VERSION ""

NS_ :

BS_:

BU_: PowertrainControlModule AtmosphericSensor SafetyRestraintSystem2 Aftertreatment_2_GasOutlet Aftertreatment_2_GasIntake DieselParticulateFilterControl Turbocharger SafetyRestraintSystem1 CabDisplay2 Aftertreatment_1_GasOutlet Aftertreatment_1_GasIntake OnBoardDataLogger OffBoardDiagnosticTool2 OffBoardDiagnosticTool1 FileServer ParkingBrakeController SeatController2 FanDriveController SteeringColumnUnit CommunicationUnitRadio CommunicationUnitSatellite CommunicationUnitCellular PropulsionBatteryCharger ChassisController2 ChassisController1 EngineValveControl AuxiliaryHeater2 AuxiliaryHeater1 ClutchUnit RampControl InformationSystem1 SuspensionSystemController2 OilSensor VehicleDynamicStability ExhaustEmissionController TransmissionDisplay2 TransmissionDisplay1 ClimateControl2 WaterPumpController RearAxleSteeringController LightingOperatorControl SeatController1 IgnitionController2 IgnitionController1 TirePressureController CabController2 CabController1 PneumaticSystemController SuspensionSystemController1 HydraulicPumpController EnduranceBrakingSystem RetarderExhaustEngine2 OnBoardDiagnosticUnit HeadwayController RetarderExhaustEngine1 CabDisplay1 ManagementComputer VirtualTerminal OffVehicleGateway PowerTakeOffFront HitchControl AuxiliaryValveControl BodyController TractorTrailerBridge1 StarterSystem ElectricalSystem VehicleSecurity VehicleNavigation AerodynamicControl ElectricalChargingSystem ClimateControl1 TripRecorder InstrumentCluster SuspensionDriveAxle2 SuspensionDriveAxle1 SuspensionSteerAxle SteeringController FuelSystem CruiseControl RetarderDriveline RetarderEngine BrakesDriveAxle2 BrakesDriveAxle1 BrakesSystemController BrakesSteerAxle AxleDrive2 AxleDrive1 AxleSteering PowerTakeOff ShiftConsoleSecondary ShiftConsolePrimary Transmission2 Transmission1 Engine2 Engine1

BO_ 2558394110 EAMC: 8 Vector__XXX
 SG_ Instance15 : 46|1@1+ (1,0) [0|1] "" Vector__XXX
 SG_ Instance14 : 45|1@1+ (1,0) [0|1] "" Vector__XXX
 SG_ Instance13 : 44|1@1+ (1,0) [0|1] "" Vector__XXX
 SG_ Instance12 : 43|1@1+ (1,0) [0|1] "" Vector__XXX
 SG_ Instance11 : 42|1@1+ (1,0) [0|1] "" Vector__XXX
 SG_ Instance10 : 41|1@1+ (1,0) [0|1] "" Vector__XXX
 SG_ Instance9 : 40|1@1+ (1,0) [0|1] "" Vector__XXX
 SG_ Instance8 : 39|1@1+ (1,0) [0|1] "" Vector__XXX
 SG_ Instance7 : 38|1@1+ (1,0) [0|1] "" Vector__XXX
 SG_ Instance6 : 37|1@1+ (1,0) [0|1] "" Vector__XXX
 SG_ Instance5 : 36|1@1+ (1,0) [0|1] "" Vector__XXX
 SG_ Instance4 : 35|1@1+ (1,0) [0|1] "" Vector__XXX
 SG_ Instance3 : 34|1@1+ (1,0) [0|1] "" Vector__XXX
 SG_ Instance2 : 33|1@1+ (1,0) [0|1] "" Vector__XXX
 SG_ Instance1 : 32|1@1+ (1,0) [0|1] "" Vector__XXX
 SG_ PercentSpdCmd : 24|8@1+ (0.5,0) [0|100] "%" Vector__XXX
 SG_ SpdCmd : 8|16@1+ (0.5,0) [0|32127.5] "rpm" Vector__XXX
 SG_ PwrHold : 2|2@1+ (1,0) [0|3] "" Vector__XXX
 SG_ EnableCmd : 0|2@1+ (1,0) [0|3] "" Vector__XXX

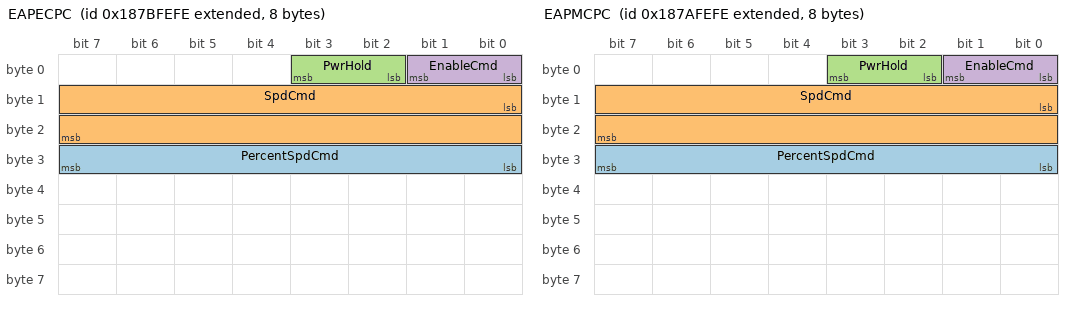
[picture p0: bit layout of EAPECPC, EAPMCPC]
BO_ 2558263038 EAPECPC: 8 Vector__XXX
 SG_ PercentSpdCmd : 24|8@1+ (0.5,0) [0|100] "%" Vector__XXX
 SG_ SpdCmd : 8|16@1+ (0.5,0) [0|32127.5] "rpm" Vector__XXX
 SG_ PwrHold : 2|2@1+ (1,0) [0|3] "" Vector__XXX
 SG_ EnableCmd : 0|2@1+ (1,0) [0|3] "" Vector__XXX

BO_ 2558197502 EAPMCPC: 8 Vector__XXX
 SG_ PercentSpdCmd : 24|8@1+ (0.5,0) [0|100] "%" Vector__XXX
 SG_ SpdCmd : 8|16@1+ (0.5,0) [0|32127.5] "rpm" Vector__XXX
 SG_ PwrHold : 2|2@1+ (1,0) [0|3] "" Vector__XXX
 SG_ EnableCmd : 0|2@1+ (1,0) [0|3] "" Vector__XXX

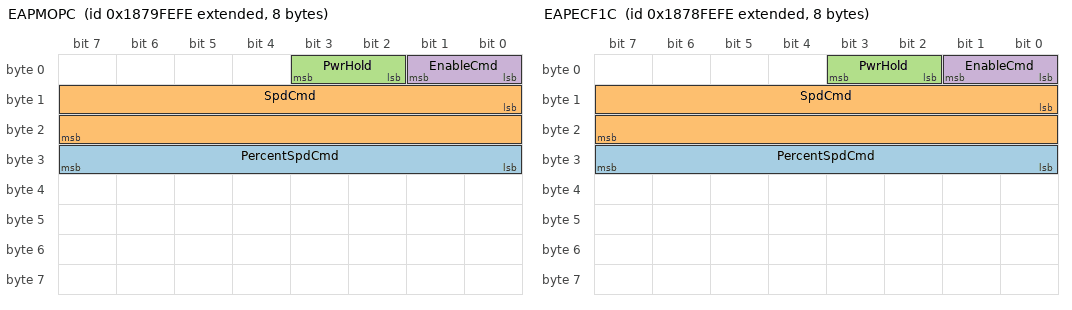
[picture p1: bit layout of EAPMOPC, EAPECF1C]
BO_ 2558131966 EAPMOPC: 8 Vector__XXX
 SG_ PercentSpdCmd : 24|8@1+ (0.5,0) [0|100] "%" Vector__XXX
 SG_ SpdCmd : 8|16@1+ (0.5,0) [0|32127.5] "rpm" Vector__XXX
 SG_ PwrHold : 2|2@1+ (1,0) [0|3] "" Vector__XXX
 SG_ EnableCmd : 0|2@1+ (1,0) [0|3] "" Vector__XXX

BO_ 2558066430 EAPECF1C: 8 Vector__XXX
 SG_ PercentSpdCmd : 24|8@1+ (0.5,0) [0|100] "%" Vector__XXX
 SG_ SpdCmd : 8|16@1+ (0.5,0) [0|32127.5] "rpm" Vector__XXX
 SG_ PwrHold : 2|2@1+ (1,0) [0|3] "" Vector__XXX
 SG_ EnableCmd : 0|2@1+ (1,0) [0|3] "" Vector__XXX

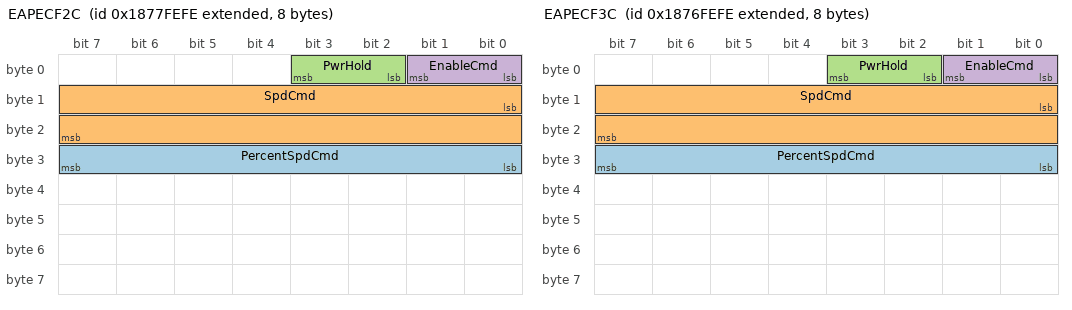
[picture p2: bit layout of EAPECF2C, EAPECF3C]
BO_ 2558000894 EAPECF2C: 8 Vector__XXX
 SG_ PercentSpdCmd : 24|8@1+ (0.5,0) [0|100] "%" Vector__XXX
 SG_ SpdCmd : 8|16@1+ (0.5,0) [0|32127.5] "rpm" Vector__XXX
 SG_ PwrHold : 2|2@1+ (1,0) [0|3] "" Vector__XXX
 SG_ EnableCmd : 0|2@1+ (1,0) [0|3] "" Vector__XXX

BO_ 2557935358 EAPECF3C: 8 Vector__XXX
 SG_ PercentSpdCmd : 24|8@1+ (0.5,0) [0|100] "%" Vector__XXX
 SG_ SpdCmd : 8|16@1+ (0.5,0) [0|32127.5] "rpm" Vector__XXX
 SG_ PwrHold : 2|2@1+ (1,0) [0|3] "" Vector__XXX
 SG_ EnableCmd : 0|2@1+ (1,0) [0|3] "" Vector__XXX

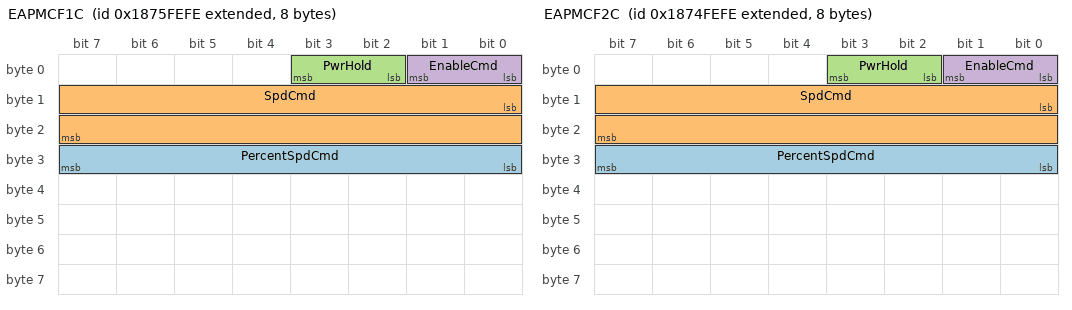
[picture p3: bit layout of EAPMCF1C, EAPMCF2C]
BO_ 2557869822 EAPMCF1C: 8 Vector__XXX
 SG_ PercentSpdCmd : 24|8@1+ (0.5,0) [0|100] "%" Vector__XXX
 SG_ SpdCmd : 8|16@1+ (0.5,0) [0|32127.5] "rpm" Vector__XXX
 SG_ PwrHold : 2|2@1+ (1,0) [0|3] "" Vector__XXX
 SG_ EnableCmd : 0|2@1+ (1,0) [0|3] "" Vector__XXX

BO_ 2557804286 EAPMCF2C: 8 Vector__XXX
 SG_ PercentSpdCmd : 24|8@1+ (0.5,0) [0|100] "%" Vector__XXX
 SG_ SpdCmd : 8|16@1+ (0.5,0) [0|32127.5] "rpm" Vector__XXX
 SG_ PwrHold : 2|2@1+ (1,0) [0|3] "" Vector__XXX
 SG_ EnableCmd : 0|2@1+ (1,0) [0|3] "" Vector__XXX

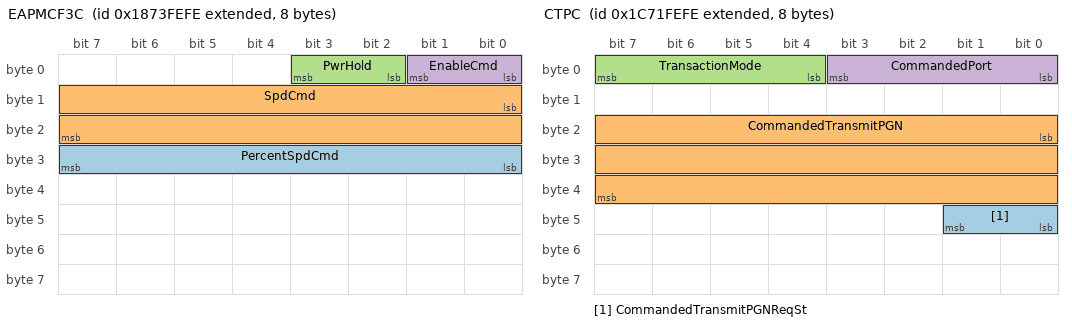
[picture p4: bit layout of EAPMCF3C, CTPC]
BO_ 2557738750 EAPMCF3C: 8 Vector__XXX
 SG_ PercentSpdCmd : 24|8@1+ (0.5,0) [0|100] "%" Vector__XXX
 SG_ SpdCmd : 8|16@1+ (0.5,0) [0|32127.5] "rpm" Vector__XXX
 SG_ PwrHold : 2|2@1+ (1,0) [0|3] "" Vector__XXX
 SG_ EnableCmd : 0|2@1+ (1,0) [0|3] "" Vector__XXX

BO_ 2557673214 ODMCC: 37 Vector__XXX
 SG_ NFBin6CountCmd : 272|24@1+ (1,0) [0|16449535] "" Vector__XXX
 SG_ NFBin5CountCmd : 248|24@1+ (1,0) [0|16449535] "" Vector__XXX
 SG_ NFBin4CountCmd : 224|24@1+ (1,0) [0|16449535] "" Vector__XXX
 SG_ NFBin3CountCmd : 200|24@1+ (1,0) [0|16449535] "" Vector__XXX
 SG_ NFBin2CountCmd : 176|24@1+ (1,0) [0|16449535] "" Vector__XXX
 SG_ NFBin1CountCmd : 152|24@1+ (1,0) [0|16449535] "" Vector__XXX
 SG_ FBin6CountCmd : 128|24@1+ (1,0) [0|16449535] "" Vector__XXX
 SG_ FBin5CountCmd : 104|24@1+ (1,0) [0|16449535] "" Vector__XXX
 SG_ FBin4CountCmd : 80|24@1+ (1,0) [0|16449535] "" Vector__XXX
 SG_ FBin3CountCmd : 56|24@1+ (1,0) [0|16449535] "" Vector__XXX
 SG_ FBin2CountCmd : 32|24@1+ (1,0) [0|16449535] "" Vector__XXX
 SG_ FBin1CountCmd : 8|24@1+ (1,0) [0|16449535] "" Vector__XXX
 SG_ IdNum : 0|8@1+ (1,0) [0|250] "" Vector__XXX

BO_ 2624716542 CTPC: 8 Vector__XXX
 SG_ CommandedTransmitPGNReqSt : 40|2@1+ (1,0) [0|3] "" Vector__XXX
 SG_ CommandedTransmitPGN : 16|24@1+ (1,0) [0|16777215] "" Vector__XXX
 SG_ TransactionMode : 4|4@1+ (1,0) [0|15] "" Vector__XXX
 SG_ CommandedPort : 0|4@1+ (1,0) [0|15] "" Vector__XXX

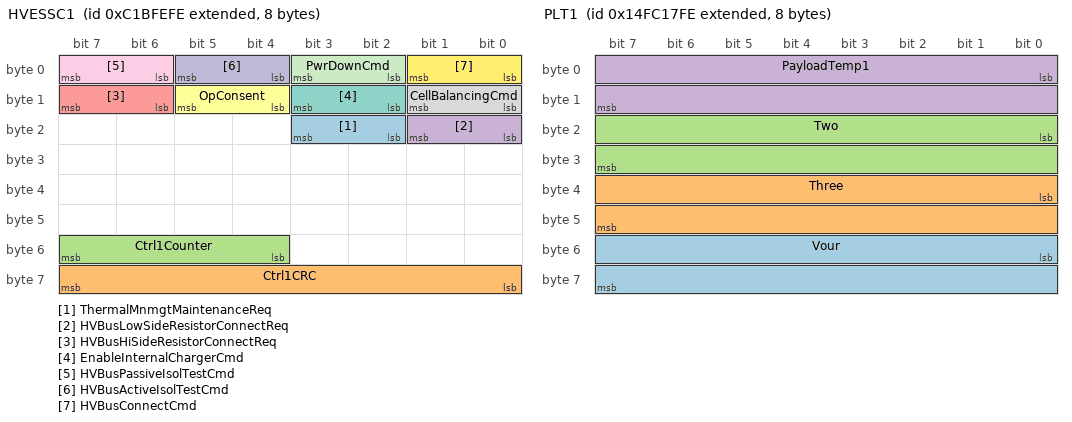
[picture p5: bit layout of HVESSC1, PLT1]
BO_ 2350644990 HVESSC1: 8 Vector__XXX
 SG_ ThermalMnmgtMaintenanceReq : 18|2@1+ (1,0) [0|3] "" Vector__XXX
 SG_ Ctrl1CRC : 56|8@1+ (1,0) [0|255] "" Vector__XXX
 SG_ Ctrl1Counter : 52|4@1+ (1,0) [0|15] "" Vector__XXX
 SG_ HVBusLowSideResistorConnectReq : 16|2@1+ (1,0) [0|3] "" Vector__XXX
 SG_ HVBusHiSideResistorConnectReq : 14|2@1+ (1,0) [0|3] "" Vector__XXX
 SG_ OpConsent : 12|2@1+ (1,0) [0|3] "" Vector__XXX
 SG_ EnableInternalChargerCmd : 10|2@1+ (1,0) [0|3] "" Vector__XXX
 SG_ CellBalancingCmd : 8|2@1+ (1,0) [0|3] "" Vector__XXX
 SG_ HVBusPassiveIsolTestCmd : 6|2@1+ (1,0) [0|3] "" Vector__XXX
 SG_ HVBusActiveIsolTestCmd : 4|2@1+ (1,0) [0|3] "" Vector__XXX
 SG_ PwrDownCmd : 2|2@1+ (1,0) [0|3] "" Vector__XXX
 SG_ HVBusConnectCmd : 0|2@1+ (1,0) [0|3] "" Vector__XXX

BO_ 2566658558 PLST1: 8 Vector__XXX
 SG_ TotalHaulCycleCount : 32|32@1+ (1,0) [0|4211081215] "" Vector__XXX
 SG_ TotalDeliveredPayloadWeight : 0|32@1+ (100,0) [0|421108121500] "kg" Vector__XXX

BO_ 2566658302 PLST2: 8 Vector__XXX
 SG_ TotalPayloadTransactionCount : 0|32@1+ (1,0) [0|4211081215] "" Vector__XXX

BO_ 2499549182 PLT1: 8 Vector__XXX
 SG_ Vour : 48|16@1+ (0.03125,-273) [-40|250] "°C" Vector__XXX
 SG_ Three : 32|16@1+ (0.03125,-273) [-40|250] "°C" Vector__XXX
 SG_ Two : 16|16@1+ (0.03125,-273) [-40|250] "°C" Vector__XXX
 SG_ PayloadTemp1 : 0|16@1+ (0.03125,-273) [-40|250] "°C" Vector__XXX

BO_ 2499548926 PLT2: 8 Vector__XXX
 SG_ Five : 0|16@1+ (0.03125,-273) [-40|250] "°C" Vector__XXX

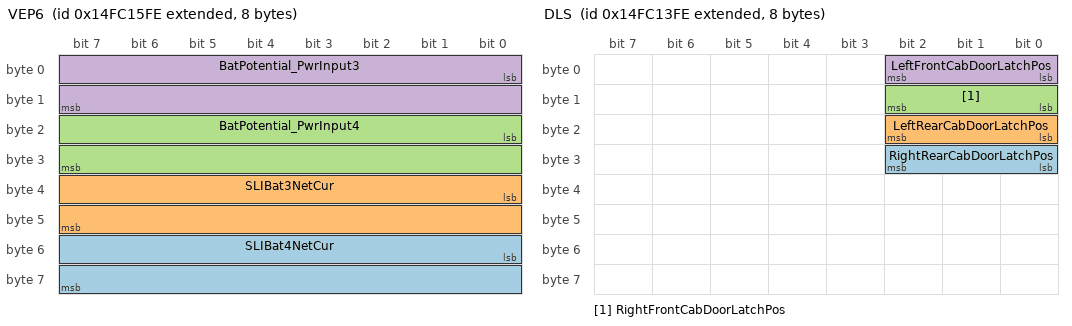
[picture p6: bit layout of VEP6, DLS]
BO_ 2499548670 VEP6: 8 Vector__XXX
 SG_ SLIBat4NetCur : 48|16@1+ (0.05,-1600) [-1600|1612.75] "A" Vector__XXX
 SG_ SLIBat3NetCur : 32|16@1+ (0.05,-1600) [-1600|1612.75] "A" Vector__XXX
 SG_ BatPotential_PwrInput4 : 16|16@1+ (0.05,0) [0|3212.75] "V" Vector__XXX
 SG_ BatPotential_PwrInput3 : 0|16@1+ (0.05,0) [0|3212.75] "V" Vector__XXX

BO_ 2499548158 DLS: 8 Vector__XXX
 SG_ RightRearCabDoorLatchPos : 24|3@1+ (1,0) [0|7] "" Vector__XXX
 SG_ LeftRearCabDoorLatchPos : 16|3@1+ (1,0) [0|7] "" Vector__XXX
 SG_ RightFrontCabDoorLatchPos : 8|3@1+ (1,0) [0|7] "" Vector__XXX
 SG_ LeftFrontCabDoorLatchPos : 0|3@1+ (1,0) [0|7] "" Vector__XXX

BO_ 2499547902 CDC1: 8 Vector__XXX
 SG_ MirrorAutoPanningEnable : 30|2@1+ (1,0) [0|3] "" Vector__XXX
 SG_ MirrorFoldingSw : 22|2@1+ (1,0) [0|3] "" Vector__XXX
 SG_ MirrorRight2HeatCmd : 54|2@1+ (1,0) [0|3] "" Vector__XXX
 SG_ MirrorLeft2HeatCmd : 52|2@1+ (1,0) [0|3] "" Vector__XXX
 SG_ MirrorRight1HeatCmd : 50|2@1+ (1,0) [0|3] "" Vector__XXX
 SG_ MirrorLeft1HeatCmd : 48|2@1+ (1,0) [0|3] "" Vector__XXX
 SG_ MirrorRight2VerticalCmd : 46|2@1+ (1,0) [0|3] "" Vector__XXX
 SG_ MirrorRight2HorizontalCmd : 44|2@1+ (1,0) [0|3] "" Vector__XXX
 SG_ MirrorLeft2VerticalCmd : 42|2@1+ (1,0) [0|3] "" Vector__XXX
 SG_ MirrorLeft2HorizontalCmd : 40|2@1+ (1,0) [0|3] "" Vector__XXX
 SG_ MirrorRight1VerticalCmd : 38|2@1+ (1,0) [0|3] "" Vector__XXX
 SG_ MirrorRight1HorizontalCmd : 36|2@1+ (1,0) [0|3] "" Vector__XXX
 SG_ MirrorLeft1VerticalCmd : 34|2@1+ (1,0) [0|3] "" Vector__XXX
 SG_ MirrorLeft1HorizontalCmd : 32|2@1+ (1,0) [0|3] "" Vector__XXX
 SG_ RightRearWindowPosCmd : 27|3@1+ (1,0) [0|7] "" Vector__XXX
 SG_ LeftRearWindowPosCmd : 24|3@1+ (1,0) [0|7] "" Vector__XXX
 SG_ RightFrontWindowPosCmd : 19|3@1+ (1,0) [0|7] "" Vector__XXX
 SG_ LeftFrontWindowPosCmd : 16|3@1+ (1,0) [0|7] "" Vector__XXX
 SG_ RemoteCabDoorLockReq : 8|3@1+ (1,0) [0|7] "" Vector__XXX
 SG_ DoorsLockActCmd : 0|3@1+ (1,0) [0|7] "" Vector__XXX

BO_ 2566656510 TGFI: 8 Vector__XXX
 SG_ EngTotalGasIdleFuelVolumeUsed : 32|32@1+ (0.5,0) [0|2105540607.5] "m³" Vector__XXX
 SG_ EngTotalGasFuelVolumeUsed : 0|32@1+ (0.5,0) [0|2105540607.5] "m³" Vector__XXX

BO_ 2565929214 ADASIS3: 8 Vector__XXX

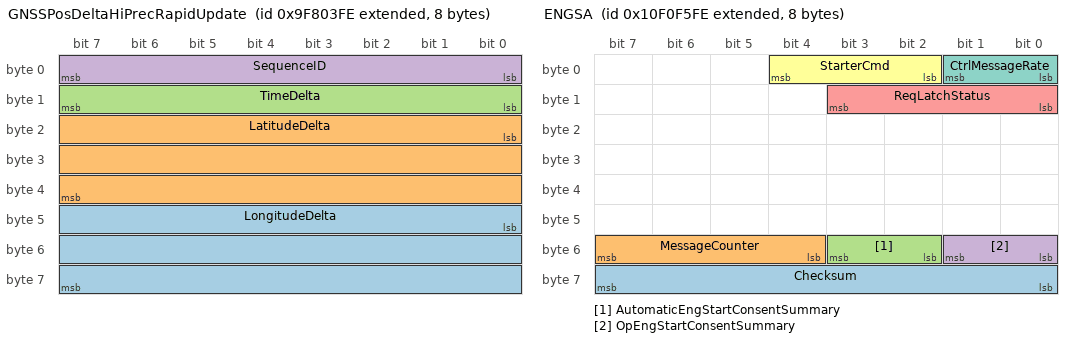
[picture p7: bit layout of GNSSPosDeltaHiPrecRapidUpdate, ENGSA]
BO_ 2314732542 GNSSPosDeltaHiPrecRapidUpdate: 8 Vector__XXX
 SG_ LongitudeDelta : 40|24@1- (10,0) [0|0] "µsec" Vector__XXX
 SG_ LatitudeDelta : 16|24@1- (10,0) [0|0] "µsec" Vector__XXX
 SG_ TimeDelta : 8|8@1+ (5,0) [0|0] "ms" Vector__XXX
 SG_ SequenceID : 0|8@1+ (1,0) [0|0] "" Vector__XXX

BO_ 2565928958 ADASIS2: 8 Vector__XXX

BO_ 2565928702 ADASIS1: 8 Vector__XXX

BO_ 2431710718 ENGSA: 8 Vector__XXX
 SG_ Checksum : 56|8@1+ (1,0) [0|255] "" Vector__XXX
 SG_ MessageCounter : 52|4@1+ (1,0) [0|15] "" Vector__XXX
 SG_ AutomaticEngStartConsentSummary : 50|2@1+ (1,0) [0|3] "" Vector__XXX
 SG_ OpEngStartConsentSummary : 48|2@1+ (1,0) [0|3] "" Vector__XXX
 SG_ ReqLatchStatus : 8|4@1+ (1,0) [0|15] "" Vector__XXX
 SG_ StarterCmd : 2|3@1+ (1,0) [0|7] "" Vector__XXX
 SG_ CtrlMessageRate : 0|2@1+ (1,0) [0|3] "" Vector__XXX

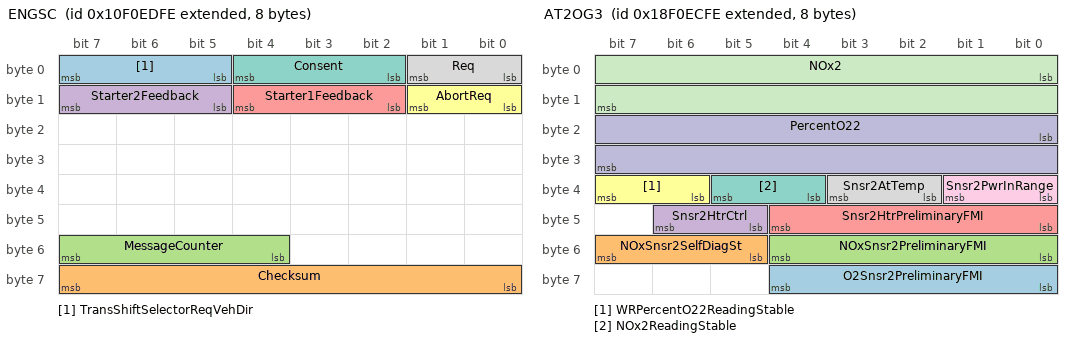
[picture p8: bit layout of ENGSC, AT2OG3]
BO_ 2431708670 ENGSC: 8 Vector__XXX
 SG_ TransShiftSelectorReqVehDir : 5|3@1+ (1,0) [0|7] "" Vector__XXX
 SG_ Checksum : 56|8@1+ (1,0) [0|255] "" Vector__XXX
 SG_ MessageCounter : 52|4@1+ (1,0) [0|15] "" Vector__XXX
 SG_ Starter2Feedback : 13|3@1+ (1,0) [0|7] "" Vector__XXX
 SG_ Starter1Feedback : 10|3@1+ (1,0) [0|7] "" Vector__XXX
 SG_ AbortReq : 8|2@1+ (1,0) [0|3] "" Vector__XXX
 SG_ Consent : 2|3@1+ (1,0) [0|7] "" Vector__XXX
 SG_ Req : 0|2@1+ (1,0) [0|3] "" Vector__XXX

BO_ 2566661118 LFC2: 8 Vector__XXX
 SG_ EngTotalDieselFuelDemand : 0|32@1+ (0.5,0) [0|2105540607.5] "l" Vector__XXX

BO_ 2633769726 EEC19: 8 Vector__XXX
 SG_ ExhFlowRate : 32|32@1+ (0.001,0) [0|4211081.215] "kg/h" Vector__XXX
 SG_ TotalEngEnergy : 0|32@1+ (1,0) [0|4211081215] "kWh" Vector__XXX

BO_ 2565926142 AT2OG3: 8 Vector__XXX
 SG_ O2Snsr2PreliminaryFMI : 56|5@1+ (1,0) [0|31] "" Vector__XXX
 SG_ NOxSnsr2SelfDiagSt : 53|3@1+ (1,0) [0|7] "" Vector__XXX
 SG_ NOxSnsr2PreliminaryFMI : 48|5@1+ (1,0) [0|31] "" Vector__XXX
 SG_ Snsr2HtrCtrl : 45|2@1+ (1,0) [0|3] "" Vector__XXX
 SG_ Snsr2HtrPreliminaryFMI : 40|5@1+ (1,0) [0|31] "" Vector__XXX
 SG_ WRPercentO22ReadingStable : 38|2@1+ (1,0) [0|3] "" Vector__XXX
 SG_ NOx2ReadingStable : 36|2@1+ (1,0) [0|3] "" Vector__XXX
 SG_ Snsr2AtTemp : 34|2@1+ (1,0) [0|3] "" Vector__XXX
 SG_ Snsr2PwrInRange : 32|2@1+ (1,0) [0|3] "" Vector__XXX
 SG_ PercentO22 : 16|16@1+ (0.000514,-12) [-12|21.02707] "%" Vector__XXX
 SG_ NOx2 : 0|16@1+ (0.05,-200) [-200|3012.75] "ppm" Vector__XXX

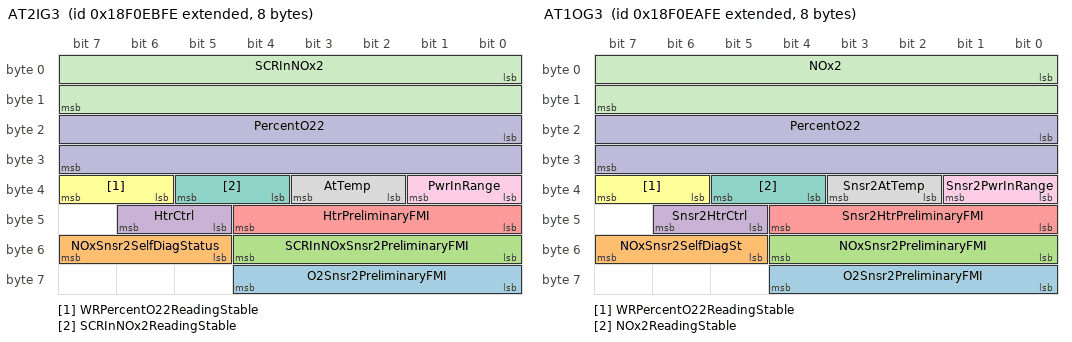
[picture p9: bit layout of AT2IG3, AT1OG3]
BO_ 2565925886 AT2IG3: 8 Vector__XXX
 SG_ O2Snsr2PreliminaryFMI : 56|5@1+ (1,0) [0|31] "" Vector__XXX
 SG_ NOxSnsr2SelfDiagStatus : 53|3@1+ (1,0) [0|7] "" Vector__XXX
 SG_ SCRInNOxSnsr2PreliminaryFMI : 48|5@1+ (1,0) [0|31] "" Vector__XXX
 SG_ HtrCtrl : 45|2@1+ (1,0) [0|3] "" Vector__XXX
 SG_ HtrPreliminaryFMI : 40|5@1+ (1,0) [0|31] "" Vector__XXX
 SG_ WRPercentO22ReadingStable : 38|2@1+ (1,0) [0|3] "" Vector__XXX
 SG_ SCRInNOx2ReadingStable : 36|2@1+ (1,0) [0|3] "" Vector__XXX
 SG_ AtTemp : 34|2@1+ (1,0) [0|3] "" Vector__XXX
 SG_ PwrInRange : 32|2@1+ (1,0) [0|3] "" Vector__XXX
 SG_ PercentO22 : 16|16@1+ (0.000514,-12) [-12|21.02707] "%" Vector__XXX
 SG_ SCRInNOx2 : 0|16@1+ (0.05,-200) [-200|3012.75] "ppm" Vector__XXX

BO_ 2565925630 AT1OG3: 8 Vector__XXX
 SG_ O2Snsr2PreliminaryFMI : 56|5@1+ (1,0) [0|31] "" Vector__XXX
 SG_ NOxSnsr2SelfDiagSt : 53|3@1+ (1,0) [0|7] "" Vector__XXX
 SG_ NOxSnsr2PreliminaryFMI : 48|5@1+ (1,0) [0|31] "" Vector__XXX
 SG_ Snsr2HtrCtrl : 45|2@1+ (1,0) [0|3] "" Vector__XXX
 SG_ Snsr2HtrPreliminaryFMI : 40|5@1+ (1,0) [0|31] "" Vector__XXX
 SG_ WRPercentO22ReadingStable : 38|2@1+ (1,0) [0|3] "" Vector__XXX
 SG_ NOx2ReadingStable : 36|2@1+ (1,0) [0|3] "" Vector__XXX
 SG_ Snsr2AtTemp : 34|2@1+ (1,0) [0|3] "" Vector__XXX
 SG_ Snsr2PwrInRange : 32|2@1+ (1,0) [0|3] "" Vector__XXX
 SG_ PercentO22 : 16|16@1+ (0.000514,-12) [-12|21.02707] "%" Vector__XXX
 SG_ NOx2 : 0|16@1+ (0.05,-200) [-200|3012.75] "ppm" Vector__XXX

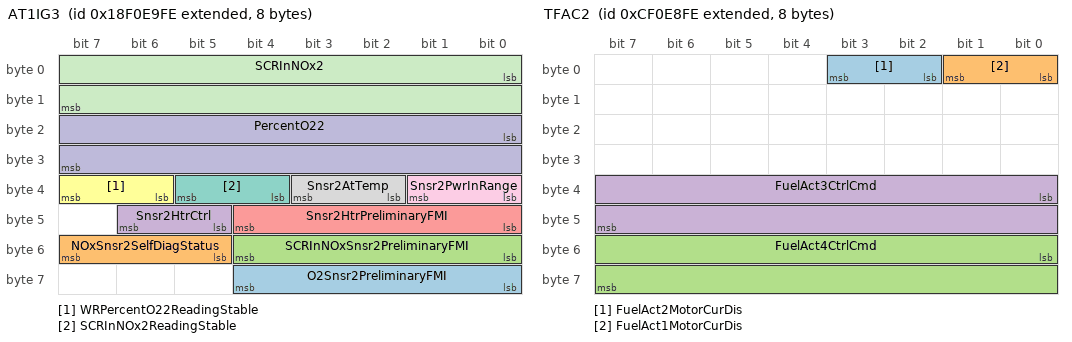
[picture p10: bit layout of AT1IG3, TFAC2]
BO_ 2565925374 AT1IG3: 8 Vector__XXX
 SG_ O2Snsr2PreliminaryFMI : 56|5@1+ (1,0) [0|31] "" Vector__XXX
 SG_ NOxSnsr2SelfDiagStatus : 53|3@1+ (1,0) [0|7] "" Vector__XXX
 SG_ SCRInNOxSnsr2PreliminaryFMI : 48|5@1+ (1,0) [0|31] "" Vector__XXX
 SG_ Snsr2HtrCtrl : 45|2@1+ (1,0) [0|3] "" Vector__XXX
 SG_ Snsr2HtrPreliminaryFMI : 40|5@1+ (1,0) [0|31] "" Vector__XXX
 SG_ WRPercentO22ReadingStable : 38|2@1+ (1,0) [0|3] "" Vector__XXX
 SG_ SCRInNOx2ReadingStable : 36|2@1+ (1,0) [0|3] "" Vector__XXX
 SG_ Snsr2AtTemp : 34|2@1+ (1,0) [0|3] "" Vector__XXX
 SG_ Snsr2PwrInRange : 32|2@1+ (1,0) [0|3] "" Vector__XXX
 SG_ PercentO22 : 16|16@1+ (0.000514,-12) [-12|21.02707] "%" Vector__XXX
 SG_ SCRInNOx2 : 0|16@1+ (0.05,-200) [-200|3012.75] "ppm" Vector__XXX

BO_ 2364598526 TFAC2: 8 Vector__XXX
 SG_ FuelAct2MotorCurDis : 2|2@1+ (1,0) [0|3] "" Vector__XXX
 SG_ FuelAct1MotorCurDis : 0|2@1+ (1,0) [0|3] "" Vector__XXX
 SG_ FuelAct4CtrlCmd : 48|16@1+ (0.0025,0) [0|160.6375] "%" Vector__XXX
 SG_ FuelAct3CtrlCmd : 32|16@1+ (0.0025,0) [0|100] "%" Vector__XXX

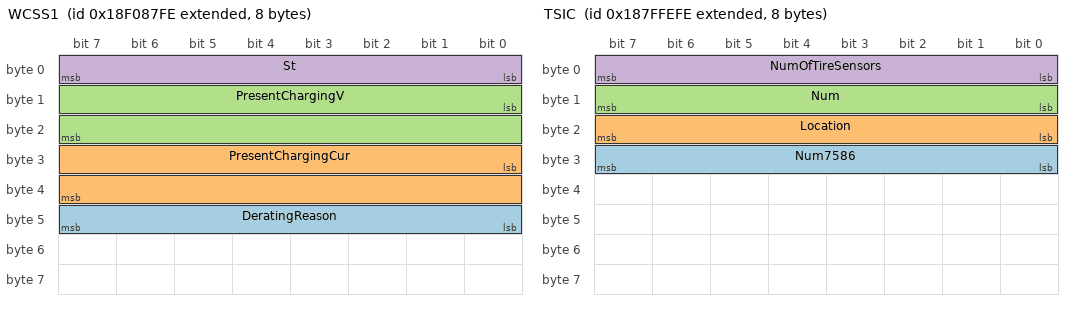
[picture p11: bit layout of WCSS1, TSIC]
BO_ 2565900286 WCSS1: 8 Vector__XXX
 SG_ DeratingReason : 40|8@1+ (1,0) [0|255] "" Vector__XXX
 SG_ PresentChargingCur : 24|16@1+ (0.1,-3212.7) [-3212.7|3212.8] "A" Vector__XXX
 SG_ PresentChargingV : 8|16@1+ (0.03125,0) [0|2007.96875] "V" Vector__XXX
 SG_ St : 0|8@1+ (1,0) [0|255] "" Vector__XXX

BO_ 2558525182 TSIC: 8 Vector__XXX
 SG_ Num7586 : 24|8@1+ (1,0) [0|255] "" Vector__XXX
 SG_ Location : 16|8@1+ (1,0) [0|255] "" Vector__XXX
 SG_ Num : 8|8@1+ (1,0) [0|250] "" Vector__XXX
 SG_ NumOfTireSensors : 0|8@1+ (1,0) [0|250] "" Vector__XXX

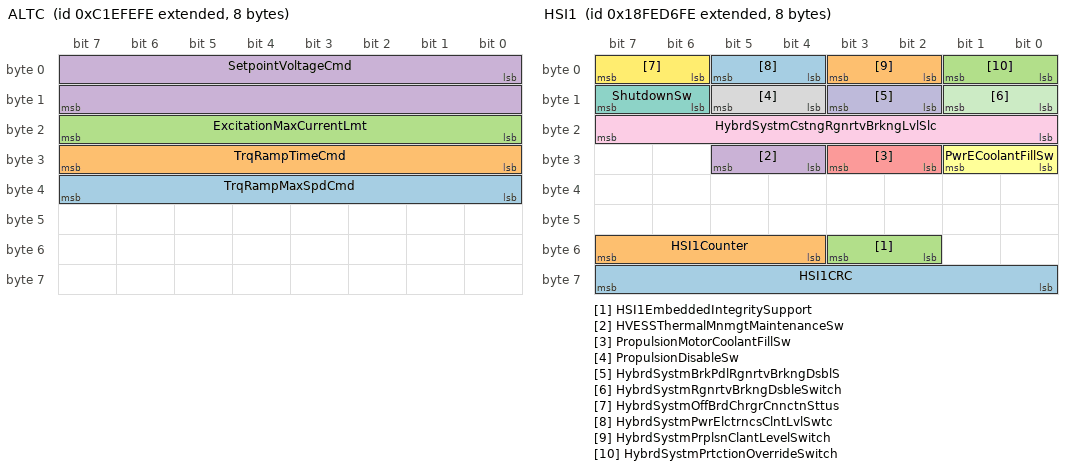
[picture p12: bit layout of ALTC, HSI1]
BO_ 2350841598 ALTC: 8 Vector__XXX
 SG_ TrqRampMaxSpdCmd : 32|8@1+ (32,0) [0|8000] "rpm" Vector__XXX
 SG_ TrqRampTimeCmd : 24|8@1+ (0.1,0) [0.1|25] "s" Vector__XXX
 SG_ ExcitationMaxCurrentLmt : 16|8@1+ (0.25,0) [0|62.5] "A" Vector__XXX
 SG_ SetpointVoltageCmd : 0|16@1+ (0.001,0) [0|64.255] "V" Vector__XXX

BO_ 2566838014 HSI1: 8 Vector__XXX
 SG_ HSI1CRC : 56|8@1+ (1,0) [0|255] "" Vector__XXX
 SG_ HSI1Counter : 52|4@1+ (1,0) [0|15] "" Vector__XXX
 SG_ HSI1EmbeddedIntegritySupport : 50|2@1+ (1,0) [0|3] "" Vector__XXX
 SG_ HVESSThermalMnmgtMaintenanceSw : 28|2@1+ (1,0) [0|3] "" Vector__XXX
 SG_ PropulsionMotorCoolantFillSw : 26|2@1+ (1,0) [0|3] "" Vector__XXX
 SG_ PwrECoolantFillSw : 24|2@1+ (1,0) [0|3] "" Vector__XXX
 SG_ ShutdownSw : 14|2@1+ (1,0) [0|3] "" Vector__XXX
 SG_ PropulsionDisableSw : 12|2@1+ (1,0) [0|3] "" Vector__XXX
 SG_ HybrdSystmCstngRgnrtvBrkngLvlSlc : 16|8@1+ (0.4,0) [0|100] "%" Vector__XXX
 SG_ HybrdSystmBrkPdlRgnrtvBrkngDsblS : 10|2@1+ (1,0) [0|3] "" Vector__XXX
 SG_ HybrdSystmRgnrtvBrkngDsbleSwitch : 8|2@1+ (1,0) [0|3] "" Vector__XXX
 SG_ HybrdSystmOffBrdChrgrCnnctnSttus : 6|2@1+ (1,0) [0|3] "" Vector__XXX
 SG_ HybrdSystmPwrElctrncsClntLvlSwtc : 4|2@1+ (1,0) [0|3] "" Vector__XXX
 SG_ HybrdSystmPrplsnClantLevelSwitch : 2|2@1+ (1,0) [0|3] "" Vector__XXX
 SG_ HybrdSystmPrtctionOverrideSwitch : 0|2@1+ (1,0) [0|3] "" Vector__XXX

BO_ 2566761726 EFI: 8 Vector__XXX
 SG_ EngIdleFuelFlowRateThreshold : 8|32@1+ (0.001,0) [0|4211081.215] "l/h" Vector__XXX
 SG_ NmbrOfFlCnsmptnMntrngTransducers : 0|8@1+ (1,0) [0|250] "" Vector__XXX

BO_ 2566756350 LFI3: 8 Vector__XXX
 SG_ EngFuelReturnTemp : 8|8@1+ (1,-40) [-40|210] "°C" Vector__XXX
 SG_ EngFuelSupplyTemp : 0|8@1+ (1,-40) [-40|210] "°C" Vector__XXX

BO_ 2566756094 LFI2: 8 Vector__XXX
 SG_ EngFuelReturnFlowRate : 32|32@1+ (0.001,0) [0|4211081.215] "l/h" Vector__XXX
 SG_ EngFuelSupplyFlowRate : 0|32@1+ (0.001,0) [0|4211081.215] "l/h" Vector__XXX

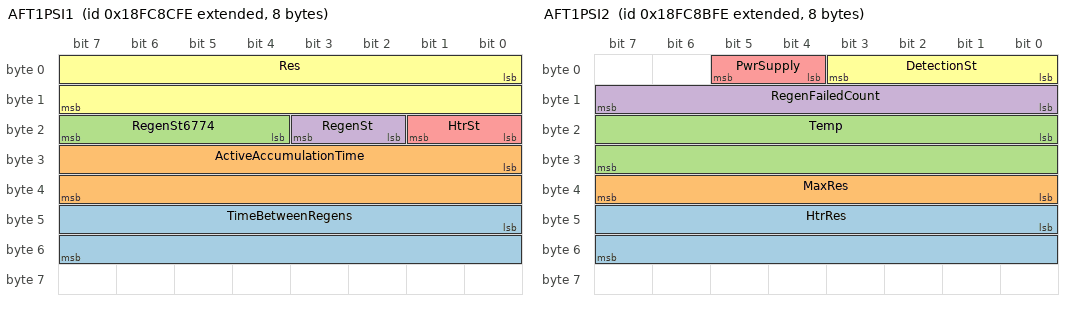
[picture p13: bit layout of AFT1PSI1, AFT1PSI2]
BO_ 2566687998 AFT1PSI1: 8 Vector__XXX
 SG_ TimeBetweenRegens : 40|16@1+ (6,0) [0|385530] "s" Vector__XXX
 SG_ ActiveAccumulationTime : 24|16@1+ (6,0) [0|385530] "s" Vector__XXX
 SG_ RegenSt6774 : 20|4@1+ (1,0) [0|15] "" Vector__XXX
 SG_ RegenSt : 18|2@1+ (1,0) [0|3] "" Vector__XXX
 SG_ HtrSt : 16|2@1+ (1,0) [0|3] "" Vector__XXX
 SG_ Res : 0|16@1+ (1,0) [0|62500] "kOhm" Vector__XXX

BO_ 2566687742 AFT1PSI2: 8 Vector__XXX
 SG_ HtrRes : 40|16@1+ (0.1,0) [0|6425.5] "Ohm" Vector__XXX
 SG_ MaxRes : 32|8@1+ (250,0) [0|62500] "kOhm" Vector__XXX
 SG_ Temp : 16|16@1+ (0.03125,-273) [-273|1734.96875] "°C" Vector__XXX
 SG_ RegenFailedCount : 8|8@1+ (1,0) [0|250] "" Vector__XXX
 SG_ PwrSupply : 4|2@1+ (1,0) [0|3] "" Vector__XXX
 SG_ DetectionSt : 0|4@1+ (1,0) [0|15] "" Vector__XXX

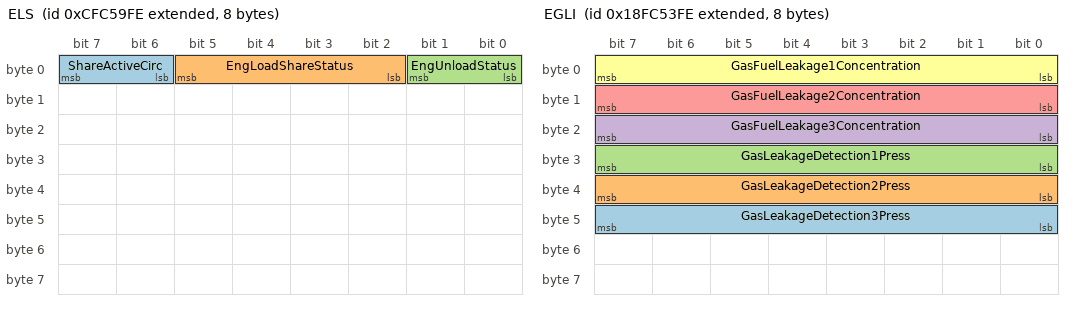
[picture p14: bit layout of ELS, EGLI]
BO_ 2365348350 ELS: 8 Vector__XXX
 SG_ ShareActiveCirc : 6|2@1+ (1,0) [0|3] "" Vector__XXX
 SG_ EngLoadShareStatus : 2|4@1+ (1,0) [0|15] "" Vector__XXX
 SG_ EngUnloadStatus : 0|2@1+ (1,0) [0|3] "" Vector__XXX

BO_ 2566674686 TCI7: 8 Vector__XXX
 SG_ EngTC2OilTemp : 24|16@1+ (0.03125,-273) [-273|1734.96875] "°C" Vector__XXX
 SG_ EngTurbo4LubeOilPress : 16|8@1+ (4,0) [0|1000] "kPa" Vector__XXX
 SG_ EngTurbo3LubeOilPress : 8|8@1+ (4,0) [0|1000] "kPa" Vector__XXX
 SG_ EngTurbo2LubeOilPress : 0|8@1+ (4,0) [0|1000] "kPa" Vector__XXX

BO_ 2566674430 SCROII1: 8 Vector__XXX
 SG_ DslExhstFldQalityMalfunctionTime : 32|32@1+ (1,0) [0|4211081215] "s" Vector__XXX
 SG_ DieselExhaustFluidTank1EmptyTime : 0|32@1+ (1,0) [0|4211081215] "s" Vector__XXX

BO_ 2566674174 SCROII2: 8 Vector__XXX
 SG_ SCROperatorInducementTotalTime : 32|32@1+ (1,0) [0|4211081215] "s" Vector__XXX
 SG_ AFTSCRMalfunctionTime : 0|32@1+ (1,0) [0|4211081215] "s" Vector__XXX

BO_ 2566673406 EGLI: 8 Vector__XXX
 SG_ GasLeakageDetection3Press : 40|8@1+ (4,0) [0|100] "kPa" Vector__XXX
 SG_ GasLeakageDetection2Press : 32|8@1+ (4,0) [0|100] "kPa" Vector__XXX
 SG_ GasLeakageDetection1Press : 24|8@1+ (4,0) [0|100] "kPa" Vector__XXX
 SG_ GasFuelLeakage3Concentration : 16|8@1+ (0.5,0) [0|100] "%" Vector__XXX
 SG_ GasFuelLeakage2Concentration : 8|8@1+ (0.5,0) [0|100] "%" Vector__XXX
 SG_ GasFuelLeakage1Concentration : 0|8@1+ (0.5,0) [0|100] "%" Vector__XXX

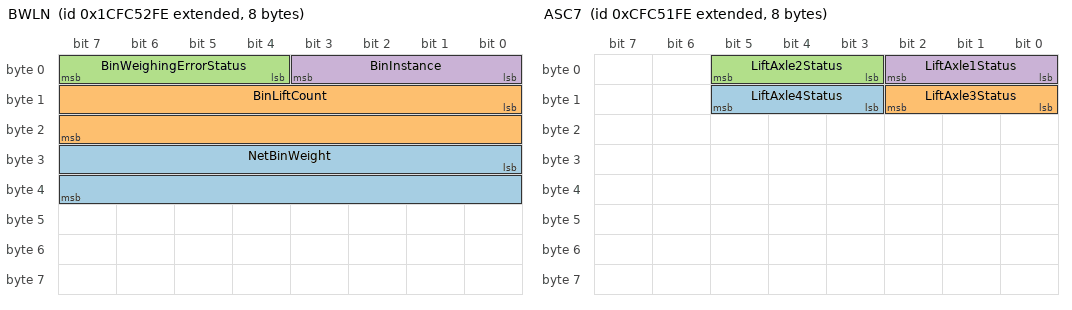
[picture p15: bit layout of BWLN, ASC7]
BO_ 2633782014 BWLN: 8 Vector__XXX
 SG_ NetBinWeight : 24|16@1+ (2,0) [0|128510] "kg" Vector__XXX
 SG_ BinLiftCount : 8|16@1+ (1,0) [0|64255] "" Vector__XXX
 SG_ BinWeighingErrorStatus : 4|4@1+ (1,0) [0|15] "" Vector__XXX
 SG_ BinInstance : 0|4@1+ (1,0) [0|15] "" Vector__XXX

BO_ 2365346302 ASC7: 8 Vector__XXX
 SG_ LiftAxle4Status : 11|3@1+ (1,0) [0|7] "" Vector__XXX
 SG_ LiftAxle3Status : 8|3@1+ (1,0) [0|7] "" Vector__XXX
 SG_ LiftAxle2Status : 3|3@1+ (1,0) [0|7] "" Vector__XXX
 SG_ LiftAxle1Status : 0|3@1+ (1,0) [0|7] "" Vector__XXX

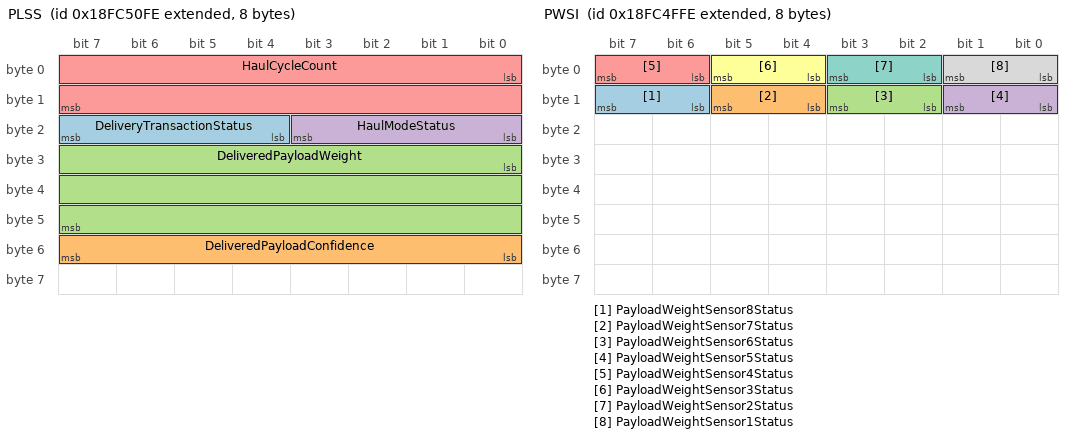
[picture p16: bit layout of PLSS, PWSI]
BO_ 2566672638 PLSS: 8 Vector__XXX
 SG_ DeliveryTransactionStatus : 20|4@1+ (1,0) [0|15] "" Vector__XXX
 SG_ DeliveredPayloadConfidence : 48|8@1+ (0.5,0) [0|100] "%" Vector__XXX
 SG_ DeliveredPayloadWeight : 24|24@1+ (2,0) [0|32899070] "kg" Vector__XXX
 SG_ HaulModeStatus : 16|4@1+ (1,0) [0|15] "" Vector__XXX
 SG_ HaulCycleCount : 0|16@1+ (1,0) [0|64255] "" Vector__XXX

BO_ 2566672382 PWSI: 8 Vector__XXX
 SG_ PayloadWeightSensor8Status : 14|2@1+ (1,0) [0|3] "" Vector__XXX
 SG_ PayloadWeightSensor7Status : 12|2@1+ (1,0) [0|3] "" Vector__XXX
 SG_ PayloadWeightSensor6Status : 10|2@1+ (1,0) [0|3] "" Vector__XXX
 SG_ PayloadWeightSensor5Status : 8|2@1+ (1,0) [0|3] "" Vector__XXX
 SG_ PayloadWeightSensor4Status : 6|2@1+ (1,0) [0|3] "" Vector__XXX
 SG_ PayloadWeightSensor3Status : 4|2@1+ (1,0) [0|3] "" Vector__XXX
 SG_ PayloadWeightSensor2Status : 2|2@1+ (1,0) [0|3] "" Vector__XXX
 SG_ PayloadWeightSensor1Status : 0|2@1+ (1,0) [0|3] "" Vector__XXX

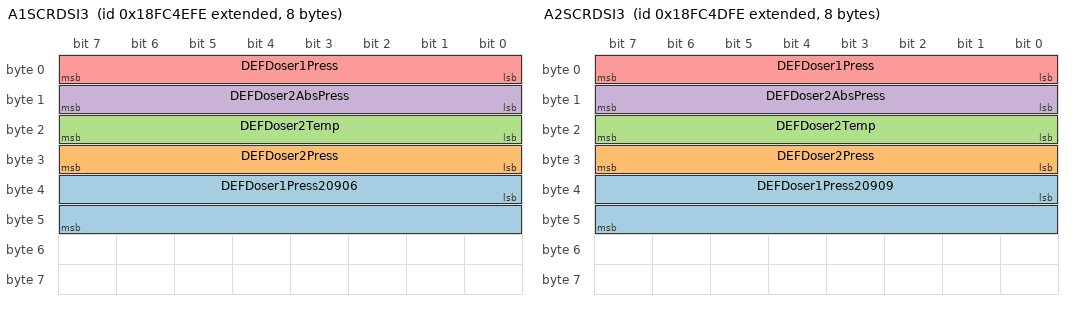
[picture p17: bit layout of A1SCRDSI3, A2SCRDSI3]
BO_ 2566672126 A1SCRDSI3: 8 Vector__XXX
 SG_ DEFDoser1Press20906 : 32|16@1+ (0.1,-100) [-100|6325.5] "kPa" Vector__XXX
 SG_ DEFDoser2Press : 24|8@1+ (4,0) [0|1000] "kPa" Vector__XXX
 SG_ DEFDoser2Temp : 16|8@1+ (1,-40) [-40|210] "°C" Vector__XXX
 SG_ DEFDoser2AbsPress : 8|8@1+ (8,0) [0|2000] "kPa" Vector__XXX
 SG_ DEFDoser1Press : 0|8@1+ (4,0) [0|1000] "kPa" Vector__XXX

BO_ 2566671870 A2SCRDSI3: 8 Vector__XXX
 SG_ DEFDoser1Press20909 : 32|16@1+ (0.1,-100) [-100|6325.5] "kPa" Vector__XXX
 SG_ DEFDoser2Press : 24|8@1+ (4,0) [0|1000] "kPa" Vector__XXX
 SG_ DEFDoser2Temp : 16|8@1+ (1,-40) [-40|210] "°C" Vector__XXX
 SG_ DEFDoser2AbsPress : 8|8@1+ (8,0) [0|2000] "kPa" Vector__XXX
 SG_ DEFDoser1Press : 0|8@1+ (4,0) [0|1000] "kPa" Vector__XXX

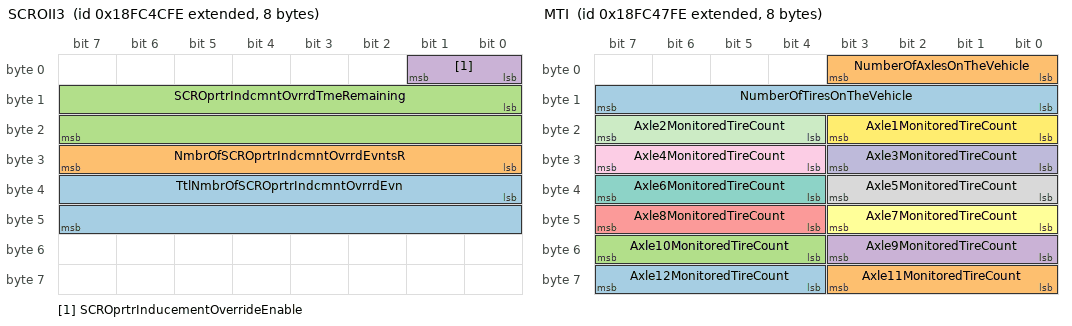
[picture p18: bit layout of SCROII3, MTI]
BO_ 2566671614 SCROII3: 8 Vector__XXX
 SG_ TtlNmbrOfSCROprtrIndcmntOvrrdEvn : 32|16@1+ (1,0) [0|64255] "" Vector__XXX
 SG_ NmbrOfSCROprtrIndcmntOvrrdEvntsR : 24|8@1+ (1,0) [0|250] "" Vector__XXX
 SG_ SCROprtrIndcmntOvrrdTmeRemaining : 8|16@1+ (1,0) [0|64255] "s" Vector__XXX
 SG_ SCROprtrInducementOverrideEnable : 0|2@1+ (1,0) [0|3] "" Vector__XXX

BO_ 2566671358 EEC17: 8 Vector__XXX
 SG_ CylFuelRate : 48|16@1+ (0.03125,0) [0|2007.96875] "mg/stroke" Vector__XXX
 SG_ EngExhaustFlowRate : 32|16@1+ (0.2,0) [0|12851] "kg/h" Vector__XXX
 SG_ VehicleFuelRate : 16|16@1+ (0.02,0) [0|1285.1] "g/s" Vector__XXX
 SG_ PEMSEngFuelMassFlowRate : 0|16@1+ (0.02,0) [0|1285.1] "g/s" Vector__XXX

BO_ 2566671102 SCRSC: 8 Vector__XXX
 SG_ AFT1CondNotMetForActiveClean : 60|2@1+ (1,0) [0|3] "" Vector__XXX
 SG_ SCRSystemCleaningForcedStatus : 53|3@1+ (1,0) [0|7] "" Vector__XXX
 SG_ SCRSystmClnngAtmtcIntationConfig : 48|2@1+ (1,0) [0|3] "" Vector__XXX
 SG_ SCRSystmClnngInhbtdDTVhclSpdBlwA : 46|2@1+ (1,0) [0|3] "" Vector__XXX
 SG_ SCRSystmClnngInhbtdDTEngNtWrmdUp : 44|2@1+ (1,0) [0|3] "" Vector__XXX
 SG_ SCRSystmClnngInhbtdDTPrmnntSystm : 42|2@1+ (1,0) [0|3] "" Vector__XXX
 SG_ SCRSystmClnngInhbtdDTTmprrySystm : 40|2@1+ (1,0) [0|3] "" Vector__XXX
 SG_ SCRSystmClnngInhbtdDTSystmTmeout : 38|2@1+ (1,0) [0|3] "" Vector__XXX
 SG_ SCRSystmClnngInhbtdDTSystmFltAct : 36|2@1+ (1,0) [0|3] "" Vector__XXX
 SG_ SCRSystmClnngInhbtdDTLwExhstTemp : 34|2@1+ (1,0) [0|3] "" Vector__XXX
 SG_ SCRSystmClnngInhbtdDTPrkngBrkNtS : 32|2@1+ (1,0) [0|3] "" Vector__XXX
 SG_ SCRSystmClnngInhbtdDTVhclSpdAbvA : 30|2@1+ (1,0) [0|3] "" Vector__XXX
 SG_ SCRSystmClnngInhbtdDTOtOfNeutral : 28|2@1+ (1,0) [0|3] "" Vector__XXX
 SG_ SCRSystmClnngInhbtdDTAcclPdlOffI : 26|2@1+ (1,0) [0|3] "" Vector__XXX
 SG_ SCRSystmClnngInhbtdDeToPTOActive : 24|2@1+ (1,0) [0|3] "" Vector__XXX
 SG_ SCRSystmClnngInhbtdDTSrvcBrkActv : 22|2@1+ (1,0) [0|3] "" Vector__XXX
 SG_ SCRSystmClnngInhbtdDTCltchDsnggd : 20|2@1+ (1,0) [0|3] "" Vector__XXX
 SG_ SCRSystmClnngInhbtdDTInhbtSwitch : 18|2@1+ (1,0) [0|3] "" Vector__XXX
 SG_ SCRSystemCleaningInhibitedStatus : 16|2@1+ (1,0) [0|3] "" Vector__XXX
 SG_ SCRSystemCleaningStatus : 10|2@1+ (1,0) [0|3] "" Vector__XXX
 SG_ SCRSystemCleaningLampCmd : 0|3@1+ (1,0) [0|7] "" Vector__XXX

BO_ 2566670846 AT1HI2: 28 Vector__XXX
 SG_ TotalAFTOperatingHours : 192|32@1+ (1,0) [0|4211081215] "s" Vector__XXX
 SG_ SCRSysAvgDistBetweenCleanEvents : 160|32@1+ (0.125,0) [0|526385151.875] "km" Vector__XXX
 SG_ SCRSysAvgTimeBetweenCleanEvents : 128|32@1+ (1,0) [0|4211081215] "s" Vector__XXX
 SG_ SCRSysTotalSysCleanManReq : 96|32@1+ (1,0) [0|4211081215] "" Vector__XXX
 SG_ SCRSysTotalSysCleanInhReq : 64|32@1+ (1,0) [0|4211081215] "" Vector__XXX
 SG_ SCRSysTotalSysCleanEvents : 32|32@1+ (1,0) [0|4211081215] "" Vector__XXX
 SG_ SCRSysTotalCleanTime : 0|32@1+ (1,0) [0|4211081215] "s" Vector__XXX

BO_ 2566670590 AT2HI2: 24 Vector__XXX
 SG_ SCRSysAvgDistBetweenCleanEvents : 160|32@1+ (0.125,0) [0|526385151.875] "km" Vector__XXX
 SG_ SCRSysAvgTimeBetweenCleanEvents : 128|32@1+ (1,0) [0|4211081215] "s" Vector__XXX
 SG_ SCRSysTotalSysCleanManReq : 96|32@1+ (1,0) [0|4211081215] "" Vector__XXX
 SG_ SCRSysTotalSysCleanInhReq : 64|32@1+ (1,0) [0|4211081215] "" Vector__XXX
 SG_ SCRSysTotalSysCleanEvents : 32|32@1+ (1,0) [0|4211081215] "" Vector__XXX
 SG_ SCRSysTotalSysCleanTime : 0|32@1+ (1,0) [0|4211081215] "s" Vector__XXX

BO_ 2566670334 MTI: 8 Vector__XXX
 SG_ Axle12MonitoredTireCount : 60|4@1+ (1,0) [0|13] "" Vector__XXX
 SG_ Axle11MonitoredTireCount : 56|4@1+ (1,0) [0|13] "" Vector__XXX
 SG_ Axle10MonitoredTireCount : 52|4@1+ (1,0) [0|13] "" Vector__XXX
 SG_ Axle9MonitoredTireCount : 48|4@1+ (1,0) [0|13] "" Vector__XXX
 SG_ Axle8MonitoredTireCount : 44|4@1+ (1,0) [0|13] "" Vector__XXX
 SG_ Axle7MonitoredTireCount : 40|4@1+ (1,0) [0|13] "" Vector__XXX
 SG_ Axle6MonitoredTireCount : 36|4@1+ (1,0) [0|13] "" Vector__XXX
 SG_ Axle5MonitoredTireCount : 32|4@1+ (1,0) [0|13] "" Vector__XXX
 SG_ Axle4MonitoredTireCount : 28|4@1+ (1,0) [0|13] "" Vector__XXX
 SG_ Axle3MonitoredTireCount : 24|4@1+ (1,0) [0|13] "" Vector__XXX
 SG_ Axle2MonitoredTireCount : 20|4@1+ (1,0) [0|13] "" Vector__XXX
 SG_ Axle1MonitoredTireCount : 16|4@1+ (1,0) [0|13] "" Vector__XXX
 SG_ NumberOfTiresOnTheVehicle : 8|8@1+ (1,0) [0|250] "" Vector__XXX
 SG_ NumberOfAxlesOnTheVehicle : 0|4@1+ (1,0) [0|13] "" Vector__XXX

BO_ 2566670078 TSIS: 8 Vector__XXX
 SG_ TireSensorIdentificationNumber : 24|8@1+ (1,0) [0|255] "" Vector__XXX
 SG_ TireSensorLocation : 16|8@1+ (1,0) [0|255] "" Vector__XXX
 SG_ TireSensorTireNumber : 8|8@1+ (1,0) [0|250] "" Vector__XXX
 SG_ NumberOfTireSensors : 0|8@1+ (1,0) [0|250] "" Vector__XXX

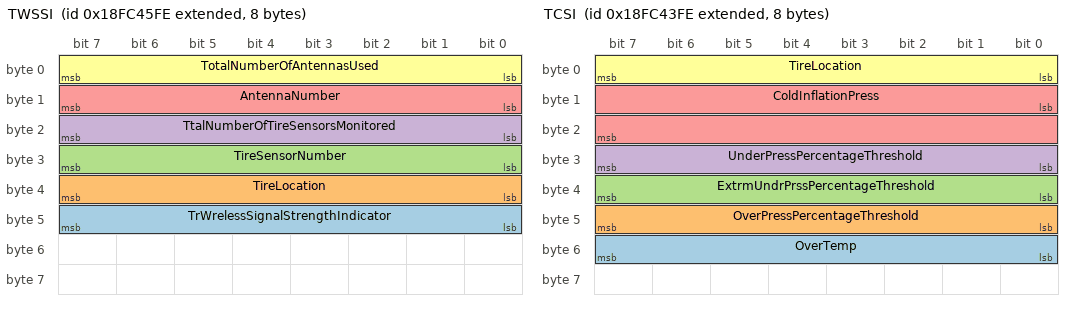
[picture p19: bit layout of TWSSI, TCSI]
BO_ 2566669822 TWSSI: 8 Vector__XXX
 SG_ TrWrelessSignalStrengthIndicator : 40|8@1+ (0.5,-125) [-125|0] "dBm" Vector__XXX
 SG_ TireLocation : 32|8@1+ (1,0) [0|255] "" Vector__XXX
 SG_ TireSensorNumber : 24|8@1+ (1,0) [0|250] "" Vector__XXX
 SG_ TtalNumberOfTireSensorsMonitored : 16|8@1+ (1,0) [0|250] "" Vector__XXX
 SG_ AntennaNumber : 8|8@1+ (1,0) [0|250] "" Vector__XXX
 SG_ TotalNumberOfAntennasUsed : 0|8@1+ (1,0) [0|250] "" Vector__XXX

BO_ 2566669310 TCSI: 8 Vector__XXX
 SG_ OverTemp : 48|8@1+ (1,-40) [-40|210] "°C" Vector__XXX
 SG_ OverPressPercentageThreshold : 40|8@1+ (0.5,0) [0|125] "%" Vector__XXX
 SG_ ExtrmUndrPrssPercentageThreshold : 32|8@1+ (0.5,0) [0|125] "%" Vector__XXX
 SG_ UnderPressPercentageThreshold : 24|8@1+ (0.5,0) [0|125] "%" Vector__XXX
 SG_ ColdInflationPress : 8|16@1+ (1,0) [0|64255] "kPa" Vector__XXX
 SG_ TireLocation : 0|8@1+ (1,0) [0|255] "" Vector__XXX

BO_ 2566669054 TIRE2: 8 Vector__XXX
 SG_ RequiredTirePress : 24|16@1+ (1,0) [0|64255] "kPa" Vector__XXX
 SG_ TirePress : 8|16@1+ (1,0) [0|64255] "kPa" Vector__XXX
 SG_ TireLocation : 0|8@1+ (1,0) [0|255] "" Vector__XXX

BO_ 2566668798 AF4: 8 Vector__XXX
 SG_ EngFl2InjctorMeteringRail1Press2 : 48|16@1+ (2,0) [0|128510] "kPa" Vector__XXX
 SG_ EngFel2InjectorMeteringRail2Temp : 40|8@1+ (1,-40) [-40|210] "°C" Vector__XXX
 SG_ EngFel2InjectorMeteringRail1Temp : 32|8@1+ (1,-40) [-40|210] "°C" Vector__XXX
 SG_ EngFl2InjectorMeteringRail2Press : 16|16@1+ (2,0) [0|128510] "kPa" Vector__XXX
 SG_ EngFl2InjectorMeteringRail1Press : 0|16@1+ (2,0) [0|128510] "kPa" Vector__XXX

CM_ BO_ 2558394110 "Electrified Accessory Motor Command
The command message to the Electrified Accessory Motor controller.  See PGN 64513 for the corresponding status message.  This PG should only be used in a case where the specific PG for the Electrified Accessory ...";
CM_ SG_ 2558394110 Instance15 "Indicates this instance of the Electrified Accessory Motor.  Multiple instances can be controlled with the same command PG by setting each unique instance parameter to 0b.
0b = Command applied to this Accessory Motor Instance
1b = No Command ...";
CM_ SG_ 2558394110 Instance14 "Indicates this instance of the Electrified Accessory Motor.  Multiple instances can be controlled with the same command PG by setting each unique instance parameter to 0b.
0b = Command applied to this Accessory Motor Instance
1b = No Command ...";
CM_ SG_ 2558394110 Instance13 "Indicates this instance of the Electrified Accessory Motor.  Multiple instances can be controlled with the same command PG by setting each unique instance parameter to 0b.
0b = Command applied to this Accessory Motor Instance
1b = No Command ...";
CM_ SG_ 2558394110 Instance12 "Indicates this instance of the Electrified Accessory Motor.  Multiple instances can be controlled with the same command PG by setting each unique instance parameter to 0b.
0b = Command applied to this Accessory Motor Instance
1b = No Command ...";
CM_ SG_ 2558394110 Instance11 "Indicates this instance of the Electrified Accessory Motor.  Multiple instances can be controlled with the same command PG by setting each unique instance parameter to 0b.
0b = Command applied to this Accessory Motor Instance
1b = No Command ...";
CM_ SG_ 2558394110 Instance10 "Indicates this instance of the Electrified Accessory Motor.  Multiple instances can be controlled with the same command PG by setting each unique instance parameter to 0b.
0b = Command applied to this Accessory Motor Instance
1b = No Command ...";
CM_ SG_ 2558394110 Instance9 "Indicates this instance of the Electrified Accessory Motor.  Multiple instances can be controlled with the same command PG by setting each unique instance parameter to 0b.
0b = Command applied to this Accessory Motor Instance
1b = No Command ...";
CM_ SG_ 2558394110 Instance8 "Indicates this instance of the Electrified Accessory Motor.  Multiple instances can be controlled with the same command PG by setting each unique instance parameter to 0b.
0b = Command applied to this Accessory Motor Instance
1b = No Command ...";
CM_ SG_ 2558394110 Instance7 "Indicates this instance of the Electrified Accessory Motor.  Multiple instances can be controlled with the same command PG by setting each unique instance parameter to 0b.
0b = Command applied to this Accessory Motor Instance
1b = No Command ...";
CM_ SG_ 2558394110 Instance6 "Indicates this instance of the Electrified Accessory Motor.  Multiple instances can be controlled with the same command PG by setting each unique instance parameter to 0b.
0b = Command applied to this Accessory Motor Instance
1b = No Command ...";
CM_ SG_ 2558394110 Instance5 "Indicates this instance of the Electrified Accessory Motor.  Multiple instances can be controlled with the same command PG by setting each unique instance parameter to 0b.
0b = Command applied to this Accessory Motor Instance
1b = No Command ...";
CM_ SG_ 2558394110 Instance4 "Indicates this instance of the Electrified Accessory Motor.  Multiple instances can be controlled with the same command PG by setting each unique instance parameter to 0b.
0b = Command applied to this Accessory Motor Instance
1b = No Command ...";
CM_ SG_ 2558394110 Instance3 "Indicates this instance of the Electrified Accessory Motor.  Multiple instances can be controlled with the same command PG by setting each unique instance parameter to 0b.
0b = Command applied to this Accessory Motor Instance
1b = No Command ...";
CM_ SG_ 2558394110 Instance2 "Indicates this instance of the Electrified Accessory Motor.  Multiple instances can be controlled with the same command PG by setting each unique instance parameter to 0b.
0b = Command applied to this Accessory Motor Instance
1b = No Command ...";
CM_ SG_ 2558394110 Instance1 "Indicates this instance of the Electrified Accessory Motor.  Multiple instances can be controlled with the same command PG by setting each unique instance parameter to 0b.
0b = Command applied to this Accessory Motor Instance
1b = No Command ...";
CM_ SG_ 2558394110 PercentSpdCmd "Speed command to this Electrified Accessory Motor in percentage of maximum speed.
Note: Both Speed Command and Percent Speed Command cannot be used at the same time.  Always set the unused speed command to Not Available.
If both commands are set ...";
CM_ SG_ 2558394110 SpdCmd "Speed command to this Electrified Accessory Motor.  Note: Both Speed Command and Percent Speed Command cannot be used at the same time.  Always set the unused speed command to Not Available.
If both commands are set to Not Available, a ...";
CM_ SG_ 2558394110 PwrHold "Command to allow this Electrified Accessory Motor to remain alive independently of the electrical enable input to the Accessory Motor.  For example, this could allow continued device operation after the keyswitch has turned off.
00b = Power Hold ...";
CM_ SG_ 2558394110 EnableCmd "Enable and direction command to this electrified Accessory Motor.

00b = Accessory Motor Off
01b = Accessory Motor On Normal/Default Direction
10b = Accessory Motor On Reverse Direction
11b = Don't Care/Take no action";
CM_ BO_ 2558263038 "Electrified Accessory Power Electronics Coolant Pump Command
The command message to the electrified accessory: Power Electronics Coolant Pump.  See PGN 64511 for the corresponding status message.";
CM_ SG_ 2558263038 PercentSpdCmd "Speed command to the Power Electronics Coolant Pump in percentage of maximum speed.
Note: Both Speed Command and Percent Speed Command cannot be used at the same time.  Always set the unused speed command to Not Available.  If both commands are set ...";
CM_ SG_ 2558263038 SpdCmd "Speed command to the Power Electronics Coolant Pump.
Note: Both Speed Command and Percent Speed Command cannot be used at the same time.  Always set the unused speed command to Not Available.  If both commands are set to Not Available, a ...";
CM_ SG_ 2558263038 PwrHold "Command to allow the Power Electronics Coolant Pump to remain alive independently of the electrical enable input to the Accessory Motor.  For example, this could allow continued device operation after the keyswitch has turned off.
00b = Power Hold ...";
CM_ SG_ 2558263038 EnableCmd "Enable and direction command to the Power Electonics Coolant Pump.

00b = Accessory Motor Off
01b = Accessory Motor On Normal/Default Direction
10b = Accessory Motor On Reverse Direction
11b = Don't Care/Take no action";
CM_ BO_ 2558197502 "Electrified Accessory Propulsion Motor Coolant Pump Command
The command message to the electrified accessory: Propulsion Motor Coolant pump.  See PGN 64510 for the corresponding status message.";
CM_ SG_ 2558197502 PercentSpdCmd "Speed command to the Propulsion Motor Coolant Pump in percentage of maximum speed.
Note: Both Speed Command and Percent Speed Command cannot be used at the same time.  Always set the unused speed command to Not Available.  If both commands are set ...";
CM_ SG_ 2558197502 SpdCmd "Speed command to the Propulsion Motor Coolant Pump.
Note: Both Speed Command and Percent Speed Command cannot be used at the same time.  Always set the unused speed command to Not Available.  If both commands are set to Not Available, a ...";
CM_ SG_ 2558197502 PwrHold "Command to allow the Propulsion Motor Coolant Pump to remain alive independently of the electrical enable input to the Accessory Motor.  For example, this could allow continued device operation after the keyswitch has turned off.
00b = Power Hold ...";
CM_ SG_ 2558197502 EnableCmd "Enable and direction command to the Propulsion Motor Coolant Pump.

00b = Accessory Motor Off
01b = Accessory Motor On Normal/Default Direction
10b = Accessory Motor On Reverse Direction
11b = Don't Care/Take no action";
CM_ BO_ 2558131966 "Electrified Accessory Propulsion Motor Oil Pump Command
The command message to the electrified accessory: Propulsion Motor Oil pump.  See PGN 64509 for the corresponding status message.";
CM_ SG_ 2558131966 PercentSpdCmd "Speed command to the Propulsion Motor Oil Pump in percentage of maximum speed.
Note: Both Speed Command and Percent Speed Command cannot be used at the same time.  Always set the unused speed command to Not Available.  If both commands are set to ...";
CM_ SG_ 2558131966 SpdCmd "Speed command to the Propulsion Motor Oil Pump.
Note: Both Speed Command and Percent Speed Command cannot be used at the same time.  Always set the unused speed command to Not Available.  If both commands are set to Not Available, a preprogrammed ...";
CM_ SG_ 2558131966 PwrHold "Command to allow the Propulsion Motor Oil Pump to remain alive independently of the electrical enable input to the Accessory Motor.  For example, this could allow continued device operation after the keyswitch has turned off.
00b = Power Hold ...";
CM_ SG_ 2558131966 EnableCmd "Enable and direction command to the Propulsion Motor Oil Pump.

00b = Accessory Motor Off
01b = Accessory Motor On Normal/Default Direction
10b = Accessory Motor On Reverse Direction
11b = Don't Care/Take no action";
CM_ BO_ 2558066430 "Electrified Accessory Power Electronics Coolant Fan 1 Command
The command message to the electrified accessory: Power Electronics Coolant Fan 1.  See PGN 64508 for the corresponding status message.";
CM_ SG_ 2558066430 PercentSpdCmd "Speed command to the Power Electronics Coolant Fan 1 in percentage of maximum speed.
Note: Both Speed Command and Percent Speed Command cannot be used at the same time.  Always set the unused speed command to Not Available.  If both commands are ...";
CM_ SG_ 2558066430 SpdCmd "Speed command to the Power Electronics Coolant Fan 1.
Note: Both Speed Command and Percent Speed Command cannot be used at the same time.  Always set the unused speed command to Not Available.  If both commands are set to Not Available, a ...";
CM_ SG_ 2558066430 PwrHold "Command to allow the Power Electronics Coolant Fan 1 to remain alive independently of the electrical enable input to the Accessory Motor.  For example, this could allow continued device operation after the keyswitch has turned off.
00b = Power Hold ...";
CM_ SG_ 2558066430 EnableCmd "Enable and direction command to the Power Electonics Coolant Fan 1.

00b = Accessory Motor Off
01b = Accessory Motor On Normal/Default Direction
10b = Accessory Motor On Reverse Direction
11b = Don't Care/Take no action";
CM_ BO_ 2558000894 "Electrified Accessory Power Electronics Coolant Fan 2 Command
The command message to the electrified accessory: Power Electronics Coolant Fan 2.  See PGN 64507 for the corresponding status message.";
CM_ SG_ 2558000894 PercentSpdCmd "Speed command to the Power Electronics Coolant Fan 2 in percentage of maximum speed.
Note: Both Speed Command and Percent Speed Command cannot be used at the same time.  Always set the unused speed command to Not Available.  If both commands are ...";
CM_ SG_ 2558000894 SpdCmd "Speed command to the Power Electronics Coolant Fan 2.
Note: Both Speed Command and Percent Speed Command cannot be used at the same time.  Always set the unused speed command to Not Available.  If both commands are set to Not Available, a ...";
CM_ SG_ 2558000894 PwrHold "Command to allow the Power Electronics Coolant Fan 2 to remain alive independently of the electrical enable input to the Accessory Motor.  For example, this could allow continued device operation after the keyswitch has turned off.
00b = Power Hold ...";
CM_ SG_ 2558000894 EnableCmd "Enable and direction command to the Power Electonics Coolant Fan 2.

00b = Accessory Motor Off
01b = Accessory Motor On Normal/Default Direction
10b = Accessory Motor On Reverse Direction
11b = Don't Care/Take no action";
CM_ BO_ 2557935358 "Electrified Accessory Power Electronics Coolant Fan 3 Command
The command message to the electrified accessory: Power Electronics Coolant Fan 3.  See PGN 64506 for the corresponding status message.";
CM_ SG_ 2557935358 PercentSpdCmd "Speed command to the Power Electronics Coolant Fan 3 in percentage of maximum speed.
Note: Both Speed Command and Percent Speed Command cannot be used at the same time.  Always set the unused speed command to Not Available.  If both commands are ...";
CM_ SG_ 2557935358 SpdCmd "Speed command to the Power Electronics Coolant Fan 3.
Note: Both Speed Command and Percent Speed Command cannot be used at the same time.  Always set the unused speed command to Not Available.  If both commands are set to Not Available, a ...";
CM_ SG_ 2557935358 PwrHold "Command to allow the Power Electronics Coolant Fan 3 to remain alive independently of the electrical enable input to the Accessory Motor.  For example, this could allow continued device operation after the keyswitch has turned off.
00b = Power Hold ...";
CM_ SG_ 2557935358 EnableCmd "Enable and direction command to the Power Electonics Coolant Fan 3.

00b = Accessory Motor Off
01b = Accessory Motor On Normal/Default Direction
10b = Accessory Motor On Reverse Direction
11b = Don't Care/Take no action";
CM_ BO_ 2557869822 "Electrified Accessory Propulsion Motor Coolant Fan 1 Command
The command message to the electrified accessory: Propulsion Motor Coolant Fan 1.  See PGN 64505 for the corresponding status message.";
CM_ SG_ 2557869822 PercentSpdCmd "Speed command to the Propulsion Motor Coolant Fan 1 in percentage of maximum speed.
Note: Both Speed Command and Percent Speed Command cannot be used at the same time.  Always set the unused speed command to Not Available.  If both commands are set ...";
CM_ SG_ 2557869822 SpdCmd "Speed command to the Propulsion Motor Coolant Fan 1.
Note: Both Speed Command and Percent Speed Command cannot be used at the same time.  Always set the unused speed command to Not Available.  If both commands are set to Not Available, a ...";
CM_ SG_ 2557869822 PwrHold "Command to allow the Propulsion Motor Coolant Fan 1 to remain alive independently of the electrical enable input to the Accessory Motor.  For example, this could allow continued device operation after the keyswitch has turned off.
00b = Power Hold ...";
CM_ SG_ 2557869822 EnableCmd "Enable and direction command to the Propulsion Motor Coolant Fan 1.

00b = Accessory Motor Off
01b = Accessory Motor On Normal/Default Direction
10b = Accessory Motor On Reverse Direction
11b = Don't Care/Take no action";
CM_ BO_ 2557804286 "Electrified Accessory Propulsion Motor Coolant Fan 2 Command
The command message to the electrified accessory: Propulsion Motor Coolant Fan 2.  See PGN 64504 for the corresponding status message.";
CM_ SG_ 2557804286 PercentSpdCmd "Speed command to the Propulsion Motor Coolant Fan 2 in percentage of maximum speed.
Note: Both Speed Command and Percent Speed Command cannot be used at the same time.  Always set the unused speed command to Not Available.  If both commands are set ...";
CM_ SG_ 2557804286 SpdCmd "Speed command to the Propulsion Motor Coolant Fan 2.
Note: Both Speed Command and Percent Speed Command cannot be used at the same time.  Always set the unused speed command to Not Available.  If both commands are set to Not Available, a ...";
CM_ SG_ 2557804286 PwrHold "Command to allow the Propulsion Motor Coolant Fan 2 to remain alive independently of the electrical enable input to the Accessory Motor.  For example, this could allow continued device operation after the keyswitch has turned off.
00b = Power Hold ...";
CM_ SG_ 2557804286 EnableCmd "Enable and direction command to the Power Motor Coolant Fan 2.

00b = Accessory Motor Off
01b = Accessory Motor On Normal/Default Direction
10b = Accessory Motor On Reverse Direction
11b = Don't Care/Take no action";
CM_ BO_ 2557738750 "Electrified Accessory Propulsion Motor Coolant Fan 3 Command
The command message to the electrified accessory: Propulsion Motor Coolant Fan 3.  See PGN 64503 for the corresponding status message.";
CM_ SG_ 2557738750 PercentSpdCmd "Speed command to the Propulsion Motor Coolant Fan 3 in percentage of maximum speed.
Note: Both Speed Command and Percent Speed Command cannot be used at the same time.  Always set the unused speed command to Not Available.  If both commands are set ...";
CM_ SG_ 2557738750 SpdCmd "Speed command to the Propulsion Motor Coolant Fan 3.
Note: Both Speed Command and Percent Speed Command cannot be used at the same time.  Always set the unused speed command to Not Available.  If both commands are set to Not Available, a ...";
CM_ SG_ 2557738750 PwrHold "Command to allow the Propulsion Motor Coolant Fan 3 to remain alive independently of the electrical enable input to the Accessory Motor.  For example, this could allow continued device operation after the keyswitch has turned off.
00b = Power Hold ...";
CM_ SG_ 2557738750 EnableCmd "Enable and direction command to the Propulsion Motor Coolant Fan 3.

00b = Accessory Motor Off
01b = Accessory Motor On Normal/Default Direction
10b = Accessory Motor On Reverse Direction
11b = Don't Care/Take no action";
CM_ BO_ 2557673214 "Oil Debris Monitor Configuration Command
Configures the attributes for an oil debris sensor within the Oil Debris Monitoring (ODM) system.
NOTE: After receiving the ODM Configuration Command, the ODM will put the new counts into effect and then ...";
CM_ SG_ 2557673214 NFBin6CountCmd "New starting value for total count of particles detected in Non-Ferrous bin 6.

NOTE: The value FFFFFFh indicates \"Do Not Change\" (i.e. the current count value of the Oil Debris Monitor for this bin will not be modified).";
CM_ SG_ 2557673214 NFBin5CountCmd "New starting value for total count of particles detected in Non-Ferrous bin 5.

NOTE: The value FFFFFFh indicates \"Do Not Change\" (i.e. the current count value of the Oil Debris Monitor for this bin will not be modified).";
CM_ SG_ 2557673214 NFBin4CountCmd "New starting value for total count of particles detected in Non-Ferrous bin 4.

NOTE: The value FFFFFFh indicates \"Do Not Change\" (i.e. the current count value of the Oil Debris Monitor for this bin will not be modified).";
CM_ SG_ 2557673214 NFBin3CountCmd "New starting value for total count of particles detected in Non-Ferrous bin 3.

NOTE: The value FFFFFFh indicates \"Do Not Change\" (i.e. the current count value of the Oil Debris Monitor for this bin will not be modified).";
CM_ SG_ 2557673214 NFBin2CountCmd "New starting value for total count of particles detected in Non-Ferrous bin 2.

NOTE: The value FFFFFFh indicates \"Do Not Change\" (i.e. the current count value of the Oil Debris Monitor for this bin will not be modified).";
CM_ SG_ 2557673214 NFBin1CountCmd "New starting value for total count of particles detected in Non-Ferrous bin 1.

NOTE: The value FFFFFFh indicates \"Do Not Change\" (i.e. the current count value of the Oil Debris Monitor for this bin will not be modified).";
CM_ SG_ 2557673214 FBin6CountCmd "New starting value for total count of particles detected in Ferrous bin 6.

NOTE: The value FFFFFFh indicates \"Do Not Change\" (i.e. the current count value of the Oil Debris Monitor for this bin will not be modified).";
CM_ SG_ 2557673214 FBin5CountCmd "New starting value for total count of particles detected in Ferrous bin 5.

NOTE: The value FFFFFFh indicates \"Do Not Change\" (i.e. the current count value of the Oil Debris Monitor for this bin will not be modified).";
CM_ SG_ 2557673214 FBin4CountCmd "New starting value for total count of particles detected in Ferrous bin 4.

NOTE: The value FFFFFFh indicates \"Do Not Change\" (i.e. the current count value of the Oil Debris Monitor for this bin will not be modified).";
CM_ SG_ 2557673214 FBin3CountCmd "New starting value for total count of particles detected in Ferrous bin 3.

NOTE: The value FFFFFFh indicates \"Do Not Change\" (i.e. the current count value of the Oil Debris Monitor for this bin will not be modified).";
CM_ SG_ 2557673214 FBin2CountCmd "New starting value for total count of particles detected in Ferrous bin 2.

NOTE: The value FFFFFFh indicates \"Do Not Change\" (i.e. the current count value of the Oil Debris Monitor for this bin will not be modified).";
CM_ SG_ 2557673214 FBin1CountCmd "New starting value for total count of particles detected in Ferrous bin 1.

NOTE: The value FFFFFFh indicates \"Do Not Change\" (i.e. the current count value of the Oil Debris Monitor for this bin will not be modified).";
CM_ SG_ 2557673214 IdNum "Identification number of the Oil Debris Monitoring (ODM) sensor being configured. Identification numbers are application specific.";
CM_ BO_ 2624716542 "Configurable Transmit PGNs Command
PGN 28928 and PGN 64471 are used to manage and report messages that are transmitted by a Configurable ECU.  PGN 28928 is used by an ECU to request the transmitted message status or configure the transmitted ...";
CM_ SG_ 2624716542 CommandedTransmitPGNReqSt "Identifies the transmit enable state being commanded for the specified PG on the port identified in SPN 8595.  This parameter is only valid when SPN 8596 is set to 'Configure Port Transmit State' (1).  For transaction modes where this parameter is ...";
CM_ SG_ 2624716542 CommandedTransmitPGN "Identifies the PG to be acted on by the associated SPN 8598.";
CM_ SG_ 2624716542 TransactionMode "Identifies the command or action being commanded to the target Configurable ECU of this instance of PGN 28928.
0000b = Request Port Transmit Status - Identifies the message as a request for the list of configurable transmit PGs on port the ...";
CM_ SG_ 2624716542 CommandedPort "Identifies the ECU communication port of the target Configurable ECU for this instance of PGN 28928.  The identification of each ECU communication port is ECU specific.  The correlation of ECU communication port to a physical network connection is ...";
CM_ BO_ 2350644990 "High Voltage Energy Storage System Control 1
Control commands to be sent to High Voltage Energy Storage System (or Pack 1 in systems with only one pack).";
CM_ SG_ 2350644990 ThermalMnmgtMaintenanceReq "Request to engage Thermal Management Maintenance Mode for the High Voltage Energy Storage System (or Pack 1 in systems with only one pack).
00b = HVESS Thermal Management Maintenance Mode is not requested
01b = HVESS Thermal Management Maintenance ...";
CM_ SG_ 2350644990 Ctrl1CRC "The CRC is defined as follows:
• Length: 8 bits
• Polynomial: x^8+x^5+x^3+x^2+x+1
• Initial Value: FFh
• Input Data Reflection: Not reflected
• Result Data Reflection: Not reflected
• XOR value: FFh
SAE makes no claim of the functional safety ...";
CM_ SG_ 2350644990 Ctrl1Counter "The message counter is used to detect situations where the transmitting ECU malfunction repeats the same frame all the time. The receiver of the information may use the counter parameter to detect this situation. The transmitting device will ...";
CM_ SG_ 2350644990 HVBusLowSideResistorConnectReq "This parameter is used to request connection of this HVES instance High-Voltage bus low side resistor in order to perform an isolation test.  See also SPN 8433  (HVESS Low-Voltage Bus High Side Resistor Connect Request).
This parameter provides ...";
CM_ SG_ 2350644990 HVBusHiSideResistorConnectReq "This parameter is used to request connection of this HVES instance High-Voltage bus high side resistor in order to perform an isolation test.  See also SPN 8434  (HVESS High-Voltage Bus Low Side Resistor Connect Request).
This parameter provides ...";
CM_ SG_ 2350644990 OpConsent "This parameter provides an indication to the High Voltage Energy Storage System (or Pack 1 in systems with only one pack) that an external device is ready for this HVES instance to proceed with normal operation.  In applications which support this ...";
CM_ SG_ 2350644990 EnableInternalChargerCmd "When the HVES has an internal charger this parameter will enable it.   External chargers may use the External Energy Source Connection Demand (SPN 7890) and related SPs.
This parameter provides HVES system level information. If there are multiple ...";
CM_ SG_ 2350644990 CellBalancingCmd "Command for the High Voltage Energy Storage System (or Pack 1 in systems with only one pack) to perform cell balancing.
This parameter provides HVES system level information. If there are multiple packs in the system, then both individual pack ...";
CM_ SG_ 2350644990 HVBusPassiveIsolTestCmd "Command for the High Voltage Energy Storage System (or Pack 1 in systems with only one pack) to perform a passive electrical isolation test on the high voltage bus.
A passive isolation test uses additional circuitry (e.g. a high impedance network) ...";
CM_ SG_ 2350644990 HVBusActiveIsolTestCmd "Command for the High Voltage Energy Storage System (or Pack 1 in systems with only one pack) to perform an active electrical isolation test on the high voltage bus.
An active isolation test might use a generated signal (e.g. an injected AC signal) ...";
CM_ SG_ 2350644990 PwrDownCmd "Command to shut down the High Voltage Energy Storage System (or Pack 1 in systems with only one pack).  A normal power-down may involve steps that take some period of time (tests, writing of data, etc.).  However, an emergency power-down should shut ...";
CM_ SG_ 2350644990 HVBusConnectCmd "Command to connect the High Voltage Energy Storage System (or Pack 1 in systems with only one pack) to the high-voltage bus.  The emergency contactor closure request may be used in situations where one or more faults in the hybrid powertrain prevent ...";
CM_ BO_ 2566658558 "Payload System Totals 1
Payload measurement system accumulators related to the haul cycle productivity.";
CM_ SG_ 2566658558 TotalHaulCycleCount "The total accumulated number of haul cycles over the life of the product.
This should be a monotonically increasing number that sums Haul Cycle Count (SPN 6847). If transactions are supported via Payload Delivery Transaction Status (SPN 7702) then ...";
CM_ SG_ 2566658558 TotalDeliveredPayloadWeight "The accumulated delivered payload mass over the life of the product.
This should be a monotonically increasing number that sums delivered payload weights (SPN 6849) If transactions are supported (Payload Delivery Transaction Status, SPN 7702) then ...";
CM_ BO_ 2566658302 "Payload System Totals 2
Payload measurement system accumulators.";
CM_ SG_ 2566658302 TotalPayloadTransactionCount "The accumulated number of completed payload delivery transactions over the life of the product.
If transaction status monitoring is supported via Payload Delivery Transaction Status (SPN 7702) then total payload transaction count may increment when ...";
CM_ BO_ 2499549182 "Payload Temperature 1
Payload temperatures";
CM_ SG_ 2499549182 Vour "Temperature of payload at measurement point 4.

Measurement position is manufacturer or regulation specific.";
CM_ SG_ 2499549182 Three "Temperature of payload at measurement point 3.

Measurement position is manufacturer or regulation specific.";
CM_ SG_ 2499549182 Two "Temperature of payload at measurement point 2.

Measurement position is manufacturer or regulation specific.";
CM_ SG_ 2499549182 PayloadTemp1 "Temperature of payload at measurement point 1.

Measurement position is manufacturer or regulation specific.";
CM_ BO_ 2499548926 "Payload Temperature 2
Payload temperatures";
CM_ SG_ 2499548926 Five "Temperature of payload at measurement point 5.

Measurement position is manufacturer or regulation specific.";
CM_ BO_ 2499548670 "Vehicle Electrical Power 6
Voltage and current measurements for batteries 3 and 4.";
CM_ SG_ 2499548670 SLIBat4NetCur "Net flow of electrical current into/out of the fourth battery or fourth set of batteries used for starting the engine, for lighting, and for ignition (SLI).";
CM_ SG_ 2499548670 SLIBat3NetCur "Net flow of electrical current into/out of the third battery or third set of batteries used for starting the engine, for lighting, and for ignition (SLI).";
CM_ SG_ 2499548670 BatPotential_PwrInput4 "This parameter measures the fourth source of battery potential as measured at the input of the ECU/actuator etc. coming from one or more batteries, irrespective of the distance between the component and the battery. This SP is also used when ECUs ...";
CM_ SG_ 2499548670 BatPotential_PwrInput3 "This parameter measures the third source of battery potential as measured at the input of the ECU/actuator etc. coming from one or more batteries, irrespective of the distance between the component and the battery. This SP is also used when ECUs are ...";
CM_ BO_ 2499548158 "Door Latch Status
This message provides status of the cabin door  latches. Doors are numbered left to right, front to back.";
CM_ SG_ 2499548158 RightRearCabDoorLatchPos "Status of the right rear cab door latch. Door latches may have 3 positions indicating fully open, 1st detent or \"ajar\", and 2nd detent or fully closed.
000b = Door Latch Open
001b = Door Latch Fully Closed/Latched
010b = Door Latch Ajar
011b = ...";
CM_ SG_ 2499548158 LeftRearCabDoorLatchPos "Status of the left rear cab door latch. Door latches may have 3 positions indicating fully open, 1st detent or \"ajar\", and 2nd detent or fully closed.
000b = Door Latch Open
001b = Door Latch Fully Closed/Latched
010b = Door Latch Ajar
011b = ...";
CM_ SG_ 2499548158 RightFrontCabDoorLatchPos "Status of the right front cab door latch (passenger door for left-hand steer vehicles). Door latches may have 3 positions indicating fully open, 1st detent or \"ajar\", and 2nd detent or fully closed.
000b = Door Latch Open
001b = Door Latch Fully ...";
CM_ SG_ 2499548158 LeftFrontCabDoorLatchPos "Status of the left front cab door latch (driver door for left-hand steer vehicles). Door latches may have 3 positions indicating fully open, 1st detent or \"ajar\", and 2nd detent or fully closed.
000b = Door Latch Open
001b = Door Latch Fully ...";
CM_ BO_ 2499547902 "Cab Door Control 1
This message requests or commands the cabin door functionality; door latches, windows, and mirrors. Doors are numbered left to right, front to back.";
CM_ SG_ 2499547902 MirrorAutoPanningEnable "Command to enable/disable the auto panning (trailer tracking) function of the mirror or mirror replacement camera.

00b = Disable panning
01b = Enable panning
10b = Reserved
11b = Not available/Take no action";
CM_ SG_ 2499547902 MirrorFoldingSw "Status of momentary switch used to toggle position of folding mirrors.

00b = No Request
01b = Request to toggle mirror position (fold/unfold)
10b = Reserved
11b = Take no action";
CM_ SG_ 2499547902 MirrorRight2HeatCmd "Command to activate heater for second mirror on the right side (passenger side for left-hand steer vehicle).  Mirror heat may be expected to latch in the \"on\" state upon receipt of the command, stay on while the command is \"take no action\" and turn ...";
CM_ SG_ 2499547902 MirrorLeft2HeatCmd "Command to activate heater for second mirror on the left side (driver side for left-hand steer vehicle).  Mirror heat may be expected to latch in the \"on\" state upon receipt of the command, stay on while the command is \"take no action\" and turn off ...";
CM_ SG_ 2499547902 MirrorRight1HeatCmd "Command to activate heater for primary mirror on the right side (passenger side for left-hand steer vehicle).  Mirror heat may be expected to latch in the \"on\" state upon receipt of the command, stay on while the command is \"take no action\" and turn ...";
CM_ SG_ 2499547902 MirrorLeft1HeatCmd "Command to activate heater for primary mirror on the left side (driver side for left-hand steer vehicle).  Mirror heat may be expected to latch in the \"on\" state upon receipt of the command, stay on while the command is \"take no action\" and turn off ...";
CM_ SG_ 2499547902 MirrorRight2VerticalCmd "Commands vertical position change of the second mirror on the right side (passenger side for lefthand steer vehicles).

00b = Move up
01b = Move down
10b = Reset (Move to predefined position)
11b = Take no action";
CM_ SG_ 2499547902 MirrorRight2HorizontalCmd "Commands horizontal position change of the second mirror on the right side (passenger side for lefthand steer vehicles).

00b = Move left
01b = Move right
10b = Reset (Move to predefined position)
11b = Take no action";
CM_ SG_ 2499547902 MirrorLeft2VerticalCmd "Commands vertical position change of the second mirror on the left side (driver side for left-hand steer vehicles). 

00b = Move up
01b = Move down
10b = Reset (Move to predefined position)
11b = Take no action";
CM_ SG_ 2499547902 MirrorLeft2HorizontalCmd "Commands horizontal position change of the second mirror on the left side (driver side for left-hand steer vehicles).

00b = Move left
01b = Move right
10b = Reset (Move to predefined position)
11b = Take no action";
CM_ SG_ 2499547902 MirrorRight1VerticalCmd "Commands vertical position change of the primary mirror on the right side (passenger side for lefthand steer vehicles).

00b = Move up
01b = Move down
10b = Reset (Move to predefined position)
11b = Take no action";
CM_ SG_ 2499547902 MirrorRight1HorizontalCmd "Commands horizontal position change of the primary mirror on the right side (passenger side for lefthand steer vehicles).

00b = Move left
01b = Move right
10b = Reset (Move to predefined position)
11b = Take no action";
CM_ SG_ 2499547902 MirrorLeft1VerticalCmd "Commands vertical position change of the primary mirror on the left side (driver side for left-hand steer vehicles).

00b = Move up
01b = Move down
10b = Reset (Move to predefined position)
11b = Take no action";
CM_ SG_ 2499547902 MirrorLeft1HorizontalCmd "Commands horizontal position change of the primary mirror on the left side (driver side for left-hand steer vehicles).

00b = Move left
01b = Move right
10b = Reset (Move to predefined position)
11b = Take no action";
CM_ SG_ 2499547902 RightRearWindowPosCmd "Commands position change of the right rear window.

000b = Window move up
001b = Window move down
010b = Window auto up
011b = Window auto down
100b = Reserved
101b = Reserved
110b = Reserved
111b = Take no action";
CM_ SG_ 2499547902 LeftRearWindowPosCmd "Commands position change of left rear window.

000b = Window move up
001b = Window move down
010b = Window auto up
011b = Window auto down
100b = Reserved
101b = Reserved
110b = Reserved
111b = Take no action";
CM_ SG_ 2499547902 RightFrontWindowPosCmd "Commands position change of right front window (passenger door window on left-hand steer vehicles).
000b = Window move up
001b = Window move down
010b = Window auto up
011b = Window auto down
100b = Reserved
101b = Reserved
110b = Reserved
 ...";
CM_ SG_ 2499547902 LeftFrontWindowPosCmd "Commands position change of left front window (driver door window on left-hand steer vehicles).
000b = Window move up
001b = Window move down
010b = Window auto up
011b = Window auto down
100b = Reserved
101b = Reserved
110b = Reserved
111b ...";
CM_ SG_ 2499547902 RemoteCabDoorLockReq "Request to the cab door lock controller from Remote Keyless Entry or or other external device to lock or unlock doors.
This parameter is different from Cab Doors Lock Actuation Command (SPN 7727) because this is a request to actuate door locks ...";
CM_ SG_ 2499547902 DoorsLockActCmd "Commands cab door latch state change: lock or unlock.
000b = Unlock left front cab door latch (driver door on LH steer vehicles)
001b = Unlock right front cab door latch (front passenger door for LH steer vehicles)
010b = Unlock left rear cab ...";
CM_ BO_ 2566656510 "Total Gaseous Fuel Information
Reports the total fuel information of systems using gaseous fuel.";
CM_ SG_ 2566656510 EngTotalGasIdleFuelVolumeUsed "Accumulated volume of engine gaseous fuel used during vehicle operation under idle conditions, in standard cubic meters.";
CM_ SG_ 2566656510 EngTotalGasFuelVolumeUsed "Accumulated volume of engine gaseous fuel used during vehicle operation, in standard cubic meters.

See SPN 1040 for alternate units.";
CM_ BO_ 2565929214 "Advanced Driver Assistance Systems Interface Specification 3
Refer to ADASIS for specific message and parameter definitions. See the ADASIS1  (PGN xxx) for more information.";
CM_ BO_ 2314732542 "This PGN is intended for applications where very high precision and very fast update rates are needed for position data 
and only has meaning when it is associated (via the Sequence ID field) with another PGN.";
CM_ SG_ 2314732542 SequenceID "An upward counting number used to tie related information together between different PGNs.";
CM_ BO_ 2565928958 "Advanced Driver Assistance Systems Interface Specification 2
Refer to ADASIS for specific message and parameter  definitions. See ADASIS1 (PGN 61686) for more information.";
CM_ BO_ 2565928702 "Advanced Driver Assistance Systems Interface Specification 1
Advanced Driver Assistance Systems Interface Specification (ADASIS) defines parameters that describe the upcoming vehicle's environment, including the attributes about the current ...";
CM_ BO_ 2431710718 "Engine Start Arbitrator
Message from the engine start arbitrator, used to manage engine starts.
Default broadcast rate of 20 ms unless the arbitrator is transmitting Engine Start Control Message Rate (SPN 7752) indicating a switch to 250 ms or on ...";
CM_ SG_ 2431710718 Checksum "Checksum to allow detection of data integrity issues. The receiving node shall calculate the checksum and compare its calculated value with the received checksum. In case of a mismatch the message shall be discarded.
The message checksum is ...";
CM_ SG_ 2431710718 MessageCounter "Message counter to allow detection of data integrity issues. The counter is incremented every time a device sends out the Engine Start Control message. When the counter has reached a value of 15 it starts over at 0 for the next message cycle ...";
CM_ SG_ 2431710718 AutomaticEngStartConsentSummary "Arbitrator's summary of the consent statuses of all devices which the arbitrator considers for automatic start requests. The purpose of this parameter is for requesters to determine if an automatic start request would be honored at the current time.
 ...";
CM_ SG_ 2431710718 OpEngStartConsentSummary "Arbitrator's summary of the consent statuses of all devices which the arbitrator considers for operator start requests. The purpose of this parameter is for requesters to determine if an operator start request would be honored at the current time.
 ...";
CM_ SG_ 2431710718 ReqLatchStatus "Indicates the arbitrator's latch status for engine start requests. All \"unlatched\" states shall transition to state \"0 - Start Request not received\" after 1000 ms unless a different state becomes more appropriate in the meantime. While this time may ...";
CM_ SG_ 2431710718 StarterCmd "Command from the arbitrator to the engine starter controller(s).
The arbitrator takes input from consenters and requesters to initiate an engine start. This signal is used by the arbitrator to command the first or second starter instance.
Starter ...";
CM_ SG_ 2431710718 CtrlMessageRate "This signal is sent by the arbitrator to control the rate at which other participants send the Engine Start Control Message (ENGSC). The arbitrator sets this signal to the slower rate after the first engine start attempt after initial power-up is ...";
CM_ BO_ 2431708670 "Engine Start Control
Message used to manage engine starts.
Default broadcast rate of 20 ms unless the sending device has received Engine Start Control Message Rate (SPN 7752) from the engine start arbitrator indicating a  switch to 250 ms or on ...";
CM_ SG_ 2431708670 TransShiftSelectorReqVehDir "This parameter indicates the direction selected by the operator via the active transmission shift selector.
Some regulations (e.g., Federal Motor Vehicle Safety Standards 102) require specific Engine Stop-Start behavior based on operator selected ...";
CM_ SG_ 2431708670 Checksum "Checksum to allow detection of data integrity issues. The receiving node shall calculate the checksum and compare its calculated value with the received checksum. In case of a mismatch the message shall be discarded.
The message checksum is ...";
CM_ SG_ 2431708670 MessageCounter "Message counter to allow detection of data integrity issues. The counter is incremented every time a device sends out the Engine Start Control message. When the counter has reached a value of 15 it starts over at 0 for the next message cycle ...";
CM_ SG_ 2431708670 Starter2Feedback "Feedback of the current state of second engine starter. This signal is intended to be used by the arbitrator as feedback to its command signal (SPN 7753).
Additional details regarding the starter state may be available in SPN 1675.
000b = Starter ...";
CM_ SG_ 2431708670 Starter1Feedback "Feedback of the current state of first engine starter. This signal is intended to be used by the arbitrator as feedback to its command signal (SPN 7753).
Additional details regarding the starter state may be available in SPN 1675.
000b = Starter ...";
CM_ SG_ 2431708670 AbortReq "Indicates the sender's desire to abort an engine start. This signal is used by requesters and consenters to request that the arbitrator cancel an engine start that is in progress.
The sender of this signal may increase the broadcast rate ...";
CM_ SG_ 2431708670 Consent "Indicates the sender's consent to start the engine for different start types. An operator-requested engine start is a start that is initiated directly by the operator (i.e. via the key switch). An automatic engine start is one that is initiated by a ...";
CM_ SG_ 2431708670 Req "Indicates the sender's desire to start the engine. The engine start arbitrator latches this signal and, if possible, completes the engine start regardless of a change of state of this signal. Use Engine Start Abort Request (SPN 7747) to un-latch the ...";
CM_ BO_ 2566661118 "Fuel Consumption (Liquid) 2
Engine fuel consumption accumulators.";
CM_ SG_ 2566661118 EngTotalDieselFuelDemand "Accumulated amount of liquid fuel that would have been used during engine operation, including actual diesel fuel used and the diesel fuel that was displaced by gaseous fuel.

This is the cumulative value of SPN 7596.";
CM_ BO_ 2633769726 "Electronic Engine Controller 19
Engine related parameters";
CM_ SG_ 2633769726 ExhFlowRate "Engine Exhaust Flow Rate shall indicate the measured/calculated exhaust gas mass flow upstream of the aftertreatment system.

See SPN 6895 for alternative range.";
CM_ SG_ 2633769726 TotalEngEnergy "The total amount of energy delivered by the engine. It is accumulated over the life of the engine.";
CM_ BO_ 2565926142 "Aftertreatment 2 Outlet Gas 3
The purpose of this PG is to group the aftertreatment outlet sensor data for bank 2.  These values include the NOx, %O2, status of the sensors with respect to the power being supplied and the heating element, errors ...";
CM_ SG_ 2565926142 O2Snsr2PreliminaryFMI "Used to identify the applicable J1939-73 FMI detected in the aftertreatment outlet oxygen second sensor by the manufacturer’s sensor control software in exhaust bank 2.  In the case of multiple failures the most severe is communicated.
A value of ...";
CM_ SG_ 2565926142 NOxSnsr2SelfDiagSt "Self-diagnosis result status for second NOx sensor ATO2 (Aftertreatment Outlet Bank 2)
000b = Diagnosis not active
001b = NOx Sensor ATO2 Self-diagnosis active flag
010b = NOx Sensor ATO2 Self-diagnosis Result Complete
011b = NOx Sensor ATO2 ...";
CM_ SG_ 2565926142 NOxSnsr2PreliminaryFMI "Used to identify the applicable J1939-73 FMI detected in the aftertreatment outlet NOx second sensor by the manufacturer’s sensor control software in exhaust bank 2.  In the case of multiple failures the most severe is communicated.
A value of 31 ...";
CM_ SG_ 2565926142 Snsr2HtrCtrl "Indicates the heater status in the warm-up process.  Upon receiving a power-up command, the gas second sensor ramps up according to a manufacturer defined profile.  The Preheat 1, Preheat 2, and Automatic messages are regions within this profile in ...";
CM_ SG_ 2565926142 Snsr2HtrPreliminaryFMI "Used to identify the applicable J1939-73 FMI detected in the heater of the outlet exhaust gas second sensor, either NOx or O2, by the manufacturer’s sensor control software in exhaust bank 2.  In the case of multiple failures the most severe is ...";
CM_ SG_ 2565926142 WRPercentO22ReadingStable "Indicates that the percent oxygen reading of the aftertreatment outlet gas second sensor, either NOx or O2, is stable as determined by the manufacturer's control software in exhaust bank 2.
For a single exhaust bank system, refer to parameters in ...";
CM_ SG_ 2565926142 NOx2ReadingStable "Indicates that the NOx reading of the aftertreatment outlet NOx second sensor is stable as determined by the manufacturer's control software in exhaust bank 2.
For a single exhaust bank system, refer to parameters in PGNs 61454, 61455, 64946, ...";
CM_ SG_ 2565926142 Snsr2AtTemp "Indicates that the heater element of the aftertreatment outlet gas second sensor, either NOx or O2, is within the manufacturer's specified range for accurate measurements in exhaust bank 2.
For a single exhaust bank system, refer to parameters in ...";
CM_ SG_ 2565926142 Snsr2PwrInRange "Indicates that the power supplied to the aftertreatment outlet gas second sensor, either NOx or O2, is within the manufacturer's specification in exhaust bank 2.
For a single exhaust bank system, refer to parameters in PGNs 61454, 61455, 64946, ...";
CM_ SG_ 2565926142 PercentO22 "The actual oxidation factor (percent oxygen) of the gas within the exhaust stream.  For positive values, the parameter represents the percent oxygen in excess of the amount required for stoichiometric combustion.  For negative values, the parameter ...";
CM_ SG_ 2565926142 NOx2 "The amount of combined NO and NO2 in the exhaust entering the aftertreatment system measured by the second NOx sensor at the aftertreatment outlet, represented in NOx molecule parts per million non-NOx molecules in exhaust bank 2.
For a single ...";
CM_ BO_ 2565925886 "Aftertreatment 2 Intake Gas 3
Groups the aftertreatment intake sensor data for bank 2 if an aftertreatment system exists.  If no aftertreatment system exists, then this PG includes sensor data for the exhaust in bank 2.
These values include the ...";
CM_ SG_ 2565925886 O2Snsr2PreliminaryFMI "Used to identify the applicable J1939-73 FMI detected in the second oxygen sensor by the manufacturer’s sensor control software in exhaust bank 2.  In the case of multiple failures the most severe is communicated.
This sensor is located at the ...";
CM_ SG_ 2565925886 NOxSnsr2SelfDiagStatus "Self-diagnosis result status for NOx second sensor EEB2 (Engine Exhaust Bank 2)
.  This sensor is located at the intake of the aftertreatment system if an aftertreatment system exists.
000b = Diagnosis not active
001b = NOx Sensor EEB2 ...";
CM_ SG_ 2565925886 SCRInNOxSnsr2PreliminaryFMI "Used to identify the applicable J1939-73 FMI detected in the second NOx sensor by the manufacturer’s sensor control software in exhaust bank 2.  This sensor is located at the intake of the SCR system if an SCR system exists.  In the case of multiple ...";
CM_ SG_ 2565925886 HtrCtrl "Indicates the heater status in the warm-up process.  Upon receiving a power-up command, the second gas sensor ramps up according to a manufacturer defined profile.  The Preheat 1, Preheat 2, and Automatic messages are regions within this profile in ...";
CM_ SG_ 2565925886 HtrPreliminaryFMI "Used to identify the applicable J1939-73 FMI detected in the heater of the second gas sensor, either NOx or O2, by the manufacturer’s sensor control software in exhaust bank 2.  In the case of multiple failures the most severe is communicated.
This ...";
CM_ SG_ 2565925886 WRPercentO22ReadingStable "Indicates that the percent oxygen reading of the second gas sensor, either NOx or O2, is stable as determined by the manufacturer's control software in exhaust bank 2.
This sensor is located at the engine exhaust in bank 2 and before the ...";
CM_ SG_ 2565925886 SCRInNOx2ReadingStable "Indicates that the NOx reading of the second NOx sensor is stable as determined by the manufacturer's control software in exhaust bank 2.
This sensor is located at the intake of the SCR system if an SCR system exists.
For a single exhaust bank ...";
CM_ SG_ 2565925886 AtTemp "Indicates that the heater element of the second gas sensor, either NOx or O2, is within the manufacturer's specified range for accurate measurements in exhaust bank 2.
This sensor is located at the engine exhaust in bank 2 and before the ...";
CM_ SG_ 2565925886 PwrInRange "Indicates that the power supplied to the second gas sensor, either NOx or O2, is within the manufacturer's specification in exhaust bank 2.
This sensor is located at the engine exhaust in bank 2 and before the aftertreatment intake in exhaust bank ...";
CM_ SG_ 2565925886 PercentO22 "The actual oxidation factor (percent oxygen) of the gas within the exhaust stream.  For positive values, the parameter represents the percent oxygen in excess of the amount required for stoichiometric combustion.  For negative values, the parameter ...";
CM_ SG_ 2565925886 SCRInNOx2 "The amount of combined NO and NO2 in the exhaust measured by the second NOx sensor at the aftertreatment intake, represented in NOx molecule parts per million non-NOx molecules in exhaust bank 2.  This sensor is located at the intake of the SCR ...";
CM_ BO_ 2565925630 "Aftertreatment 1 Outlet Gas 3
The purpose of this PG is to group the aftertreatment outlet sensor data for bank 1.  These values include the NOx, %O2, Status of the sensors with respect to the power being supplied and the heating element, errors ...";
CM_ SG_ 2565925630 O2Snsr2PreliminaryFMI "Used to identify the applicable J1939-73 FMI detected in the aftertreatment outlet oxygen second sensor by the manufacturer’s sensor control software in exhaust bank 1.  In the case of multiple failures the most severe is communicated.
A value of ...";
CM_ SG_ 2565925630 NOxSnsr2SelfDiagSt "Self-diagnosis result status for NOx second sensor ATO1 (Aftertreatment Outlet Bank 1)
000b = Diagnosis not active
001b = NOx Sensor ATO1 Self-diagnosis active flag
010b = NOx Sensor ATO1 Self-diagnosis Result Complete
011b = NOx Sensor ATO1 ...";
CM_ SG_ 2565925630 NOxSnsr2PreliminaryFMI "Used to identify the applicable J1939-73 FMI detected in the aftertreatment outlet NOx second sensor by the manufacturer’s sensor control software in exhaust bank 1.  In the case of multiple failures the most severe is communicated.
A value of 31 ...";
CM_ SG_ 2565925630 Snsr2HtrCtrl "Indicates the heater status in the warm-up process.  Upon receiving a power-up command, the gas second sensor ramps up according to a manufacturer defined profile.  The Preheat 1, Preheat 2, and Automatic messages are regions within this profile in ...";
CM_ SG_ 2565925630 Snsr2HtrPreliminaryFMI "Used to identify the applicable J1939-73 FMI detected in the heater of the outlet exhaust gas second sensor, either NOx or O2, by the manufacturer’s sensor control software in exhaust bank 1.    In the case of multiple failures the most severe is ...";
CM_ SG_ 2565925630 WRPercentO22ReadingStable "Indicates that the percent oxygen reading of the aftertreatment outlet gas second sensor, either NOx or O2, is stable as determined by the manufacturer's control software in exhaust bank 1.
00b = Not stable
01b = Stable
10b = Error
11b = Not ...";
CM_ SG_ 2565925630 NOx2ReadingStable "Indicates that the NOx reading of the aftertreatment outlet NOx second sensor is stable as determined by the manufacturer's control software in exhaust bank 1.

00b = Not stable
01b = Stable
10b = Error
11b = Not available";
CM_ SG_ 2565925630 Snsr2AtTemp "Indicates that the heater element of the aftertreatment outlet gas second sensor, either NOx or O2, is within the manufacturer's specified range for accurate measurements in exhaust bank 1.
00b = Not in range
01b = In range
10b = Error
11b = Not ...";
CM_ SG_ 2565925630 Snsr2PwrInRange "Indicates that the second measurement of power supplied to the aftertreatment outlet gas sensor, either NOx or O2, is within the manufacturer's specification in exhaust bank 1. This parameter reports the status as reported by the sensor.
00b = Not ...";
CM_ SG_ 2565925630 PercentO22 "The second measurement of the actual oxidation factor (percent oxygen) of the gas within the exhaust stream.  For positive values, the parameter represents the percent oxygen in excess of the amount required for stoichiometric combustion.  For ...";
CM_ SG_ 2565925630 NOx2 "The second measurement of the amount of combined NO and NO2 in the exhaust exiting the aftertreatment system measured by a NOx sensor at the aftertreatment outlet, represented in NOx molecule parts per million non-NOx molecules in exhaust bank 1.
 ...";
CM_ BO_ 2565925374 "Aftertreatment 1 Intake Gas 3
Groups the aftertreatment intake sensor data for bank 1 if an aftertreatment system exists.  If no aftertreatment system exists, then this PG includes sensor data for the exhaust in bank 1.
These values include the ...";
CM_ SG_ 2565925374 O2Snsr2PreliminaryFMI "Used to identify the second applicable J1939-73 FMI detected in the oxygen sensor by the manufacturer’s sensor control software in exhaust bank 1.   In the case of multiple failures the most severe is communicated.
This sensor is located at the ...";
CM_ SG_ 2565925374 NOxSnsr2SelfDiagStatus "Self-diagnosis result status for the second NOx sensor in Engine Exhaust Bank 1 (EEB1).
This sensor is located at the intake of the aftertreatment system if an aftertreatment system exists.
000b = Diagnosis not active
001b = NOx Sensor EEB1 ...";
CM_ SG_ 2565925374 SCRInNOxSnsr2PreliminaryFMI "Used to identify the applicable J1939-73 FMI detected in the second NOx sensor by the manufacturer’s sensor control software in exhaust bank 1.  In the case of multiple failures the most severe is communicated.
This sensor is located at the intake ...";
CM_ SG_ 2565925374 Snsr2HtrCtrl "Indicates the heater status in the warm-up process.  Upon receiving a power-up command, the second gas sensor ramps up according to a manufacturer defined profile.  The Preheat 1, Preheat 2, and Automatic messages are regions within this profile in ...";
CM_ SG_ 2565925374 Snsr2HtrPreliminaryFMI "Used to identify the second applicable J1939-73 FMI detected in the heater of the exhaust gas sensor, either NOx or O2, by the manufacturer’s sensor control software in exhaust bank 1.  In the case of multiple failures the most severe is ...";
CM_ SG_ 2565925374 WRPercentO22ReadingStable "Indicates that the second measurement of the percent oxygen reading of the gas sensor, either NOx or O2, is stable as determined by the manufacturer's control software in exhaust bank 1.
This sensor is located at the engine exhaust in bank 1 and ...";
CM_ SG_ 2565925374 SCRInNOx2ReadingStable "Indicates that the NOx reading of the second NOx sensor is stable as determined by the manufacturer's control software in exhaust bank 1.
This sensor is located at the intake of the SCR system if an SCR system exists.
00b = Not stable
01b = ...";
CM_ SG_ 2565925374 Snsr2AtTemp "Indicates that the heater element of the gas second sensor, either NOx or O2, is within the manufacturer's specified range for accurate measurements in exhaust bank 1.
This sensor is located at the engine exhaust in bank 1 and before the ...";
CM_ SG_ 2565925374 Snsr2PwrInRange "Indicates that the second measurement of power supplied to the gas sensor, either NOx or O2, is within the manufacturer's specification in exhaust bank 1.  This parameter reports the status as reported by the sensor.
This sensor is located at the ...";
CM_ SG_ 2565925374 PercentO22 "The second measurement of the actual oxidation factor (Percent Oxygen) of the gas within the exhaust stream. For positive values, the parameter represents the percent oxygen in excess of the amount required for stoichiometric combustion. For ...";
CM_ SG_ 2565925374 SCRInNOx2 "The second measurement of the amount of combined NO and NO2 in the exhaust, represented in NOx molecule parts per million non-NOx molecules in exhaust bank 1.  This sensor is located at the intake of the SCR system if an SCR system exists.
Any ...";
CM_ BO_ 2364598526 "Engine Throttle / Fuel Actuator Control Command 2
Used to control networked electronic throttle control actuator and/or fuel control actuator valves.
Otherwise, this PG can be used to monitor commanded % positioning to electronic throttle control ...";
CM_ SG_ 2364598526 FuelAct2MotorCurDis "Command to disable power to motor in the second actuator to prevent unnecessary load on the component.

00b = Do Not Disable
01b = Disable
10b = Reserved
11b = Don't Care/Take No Action";
CM_ SG_ 2364598526 FuelAct1MotorCurDis "Command to disable power to motor in the actuator to prevent unnecessary load on the component.

00b = Do Not Disable
01b = Disable
10b = Reserved
11b = Don't Care/Take No Action";
CM_ SG_ 2364598526 FuelAct4CtrlCmd "The control command to fuel actuator 4, normalized to percent, where 0% represents fully closed and 100% represents fully open.  Typically, this fuel actuator is used to regulate low pressure natural gas flow rate, mixing into the air flow, which ...";
CM_ SG_ 2364598526 FuelAct3CtrlCmd "The control command to fuel actuator 3, normalized to percent, where 0% represents fully closed and 100% represents fully open.  Typically, this fuel actuator is used to regulate low pressure natural gas flow rate, mixing into the air flow, which ...";
CM_ BO_ 2565900286 "Wireless Charger System Status 1
This message is sent from the Wireless Charger EVCC containing status information about the wireless charging system.";
CM_ SG_ 2565900286 DeratingReason "Dominant reason that the delivered power is lower than the requested power:
0 - Not Derating
1 - VA (Vehicle Assembly) Temperature
2 - VA (Vehicle Assembly) Alignment
3 - Vehicle Internal
4 - GA (Ground Assembly) Temperature
5 - GA (Ground ...";
CM_ SG_ 2565900286 PresentChargingCur "The present current of the supplied power from the charging system as measured by the wireless charging system. A Positive number denotes current being supplied into the battery, a negative number denotes current being pulled from the battery for ...";
CM_ SG_ 2565900286 PresentChargingV "The present voltage of the supplied power from the charging system as measured by the wireless charging system.";
CM_ SG_ 2565900286 St "The present charging state of the system. States are (reference to SAE J2847-6 Sep 2020):
000 - Off
001 - Standby
002 - Session Initiated
003 - Awaiting Alignment
004 - Idle
005 - Power Transfer
006 - Shutdown
007 - VA (Vehicle Assembly) ...";
CM_ BO_ 2558525182 "Tire Sensor Identification Command
The tire sensor identification number command for each monitored tire.
The command will be used to program sensor identification numbers for individual tire. Since there are multiple tire sensors to report, the ...";
CM_ SG_ 2558525182 Num7586 "The identification number of tire sensor for the tire specified in the tire sensor tire number (SPN 7584) or tire sensor location (SPN 7585).";
CM_ SG_ 2558525182 Location "The location of monitored tire that corresponds with the tire sensor identification number SPN 7586. In order to specify the monitored tire by tire number, use the tire number SPN 7584.
The high order 4 bits indicate the vehicle axle position of ...";
CM_ SG_ 2558525182 Num "The number of the monitored tire that corresponds with the tire sensor identification number SPN 7586. In order to specify the monitored tire by location, use the tire location SPN 7585.

The value FFh indicates this SP is not used.";
CM_ SG_ 2558525182 NumOfTireSensors "Total count of monitored tire sensor identification numbers represented in this instance of the parameter group.";
CM_ BO_ 2350841598 "Alternator Control
Parameters to control the alternator.";
CM_ SG_ 2350841598 TrqRampMaxSpdCmd "The Alternator Torque Ramp Time Command (SPN 7591) is applied if the alternator speed is less than Alternator Torque Ramp Maximum Speed Command (SPN 7592). If the alternator speed is greater than Alternator Torque Ramp Maximum Speed Command, then ...";
CM_ SG_ 2350841598 TrqRampTimeCmd "Sets the torque ramp rate in which the alternator can respond to a change in electrical load. 100% represents the reference engine torque (SPN 544).
This value will be applied if the alternator speed is less than Alternator Torque Ramp Maximum ...";
CM_ SG_ 2350841598 ExcitationMaxCurrentLmt "Command sent to alternator to set the maximum excitation current of the alternator.";
CM_ SG_ 2350841598 SetpointVoltageCmd "Setpoint voltage command to alternator. The setpoint voltage is the point that is regulated by the alternator. This may or may not be the output of the alternator.";
CM_ BO_ 2566838014 "Hybrid or EV System Inputs 1
This message can be sent by any controller that has hybrid or EV system related information.";
CM_ SG_ 2566838014 HSI1CRC "The CRC is defined as follows:
• Length: 8 bits
• Polynomial: x^8+x^5+x^3+x^2+x+1
• Initial Value: FFh
• Input Data Reflection: Not reflected
• Result Data Reflection: Not reflected
• XOR value: FFh
SAE makes no claim of the functional safety ...";
CM_ SG_ 2566838014 HSI1Counter "The message counter is used to detect situations where the transmitting ECU malfunction repeats the same frame all the time. The receiver of the information may use the counter parameter to detect this situation. The transmitting device will ...";
CM_ SG_ 2566838014 HSI1EmbeddedIntegritySupport "Indicates SPN 22273 (HSI1 CRC) and SPN 22271 (HSI1 Counter) are supported by the sender.
00b = HSI1 embedded CRC and Counter are supported by the sender
01b = HSI1 protection is supported using J1939-76 SHM
10b = Reserved
11b = HSI1 CRC and ...";
CM_ SG_ 2566838014 HVESSThermalMnmgtMaintenanceSw "Indicates the HVESS Thermal Management Maintenance Switch position. This switch is used to request the Hybrid or Electric Vehicle System Controller to maintain HVESS thermal management for maintenance purposes.
00b = Off
01b = On
10b = Error
11b ...";
CM_ SG_ 2566838014 PropulsionMotorCoolantFillSw "Indicates the coolant fill switch position for the propulsion motor cooling system.  This switch is used to enable the pump for filling the cooling system.  When the switch is in the On state, the pump is to be running.
00b = Off
01b = On
10b = ...";
CM_ SG_ 2566838014 PwrECoolantFillSw "Indicates the coolant fill switch position for the power electronics cooling system.  This switch is used to enable the pump for filling the cooling system.  When the switch is in the On state, the pump is to be running.
00b = Off
01b = On
10b = ...";
CM_ SG_ 2566838014 ShutdownSw "When the operator enables this switch, all hybrid or EV system functionality is disabled including propulsion, regenerative braking, and hybrid or EV powered accessories.  The hybrid or EV system shall be placed in an electrically off state where ...";
CM_ SG_ 2566838014 PropulsionDisableSw "When the operator enables this switch, the propulsion aspect of hybrid or EV system operation will be disabled.  However, hybrid or EV powered accessories may be on and the engine may still run in hybrid applications.  Regenerative braking is ...";
CM_ SG_ 2566838014 HybrdSystmCstngRgnrtvBrkngLvlSlc "Indicates the coasting regenerative braking level selector position.  Coasting regenerative braking occurs when neither the accelerator nor the brake pedal are depressed.
The coasting regenerative braking level is the position of the driver’s ...";
CM_ SG_ 2566838014 HybrdSystmBrkPdlRgnrtvBrkngDsblS "Indicates the brake pedal regenerative braking disable switch position.  This switch allows the operator to disable regenerative braking (e.g. such as during slippery road conditions) that is controlled by brake pedal application.   Regenerative ...";
CM_ SG_ 2566838014 HybrdSystmRgnrtvBrkngDsbleSwitch "Indicates the regenerative braking disable switch position.  This switch gives the operator the ability to disable all regenerative braking from all inputs (e.g. such as during slippery road conditions).
00b = Regenerative Braking Disable Switch is ...";
CM_ SG_ 2566838014 HybrdSystmOffBrdChrgrCnnctnSttus "Indicates the off-board plug-in charger connection status.  One of the uses of this signal is to protect against vehicle motion while a charger is plugged in.
00b = Off-board charger is not connected
01b = Off-board charger is connected
10b = ...";
CM_ SG_ 2566838014 HybrdSystmPwrElctrncsClntLvlSwtc "Indicates the coolant level switch position in the hybrid or EV system power electronics (e.g. Inverters, DC/DC converters) cooling system.

00b = Coolant Level is not sufficient
01b = Coolant Level is sufficient
10b = Error
11b = Not Available";
CM_ SG_ 2566838014 HybrdSystmPrplsnClantLevelSwitch "Indicates the coolant level switch position in the hybrid or EV system propulsion (e.g. electric motor, generator) cooling system.

00b = Coolant Level is not sufficient
01b = Coolant Level is sufficient
10b = Error
11b = Not Available";
CM_ SG_ 2566838014 HybrdSystmPrtctionOverrideSwitch "Indicates the Protection Override switch position.  This switch allows the operator to override hybrid or EV system protection features and failure modes allowing hybrid or EV system to continue to operate if possible.
00b = Not Active
01b = ...";
CM_ BO_ 2566761726 "Engine Fuel Information
Configuration information for engine fuel system.";
CM_ SG_ 2566761726 EngIdleFuelFlowRateThreshold "A configuration value that indicates the maximum flow rate for engine idle operation.";
CM_ SG_ 2566761726 NmbrOfFlCnsmptnMntrngTransducers "The number of fuel consumption monitoring transducers installed in the fuel consumption monitoring system.";
CM_ BO_ 2566756350 "Fuel Information 3 (Liquid)
Message for reporting information associated with liquid fuel.";
CM_ SG_ 2566756350 EngFuelReturnTemp "The temperature of the fuel flowing through a fuel return line from the engine back to the fuel tank.";
CM_ SG_ 2566756350 EngFuelSupplyTemp "The temperature of the fuel flowing through a fuel supply line from the fuel tank to the engine.";
CM_ BO_ 2566756094 "Fuel Information 2 (Liquid)
Message for reporting information associated with liquid fuel.";
CM_ SG_ 2566756094 EngFuelReturnFlowRate "The rate of fuel flowing through a fuel return line carrying fuel from the engine back to fuel tank.";
CM_ SG_ 2566756094 EngFuelSupplyFlowRate "The rate of fuel flowing through a fuel supply line carrying fuel from the fuel tank to the engine.";
CM_ BO_ 2566687998 "Aftertreatment 1 Particulate Sensor Information 1
This message contains information for the particulate sensor in bank 1 of a 2 bank system or the particulate sensor in a single bank system.

This sensor is downstream of the DPF.";
CM_ SG_ 2566687998 TimeBetweenRegens "This is the time between the last two successful regenerations of the particulate sensor for the current power cycle. This parameter reflects the time when the engine was running, not a duration based on a real time clock. If two successful ...";
CM_ SG_ 2566687998 ActiveAccumulationTime "This is the amount of time since the last successful regeneration completed.  The sensor has been accumulating particulate matter since that time.";
CM_ SG_ 2566687998 RegenSt6774 "Indicates if the particulate sensor regeneration is currently active, and if so, the reason for the regeneration.
0000b = Regeneration is not active
0001b = Regneration is active and has been initiated by request via SPN 6783
0010b = Regeneration ...";
CM_ SG_ 2566687998 RegenSt "The status of the most recent attempt of this power cycle to activate the particulate sensor regeneration process. This will not be updated until the regeneration is no longer active, as indicated by SPN 6774.
Power cycle refers to the time that ...";
CM_ SG_ 2566687998 HtrSt "The states of the particulate sensor heater.  The heater will change states from 11b to 10b, 10b to 01b, and 01b to 00b in a typical heating event.
00b = Heater is in closed loop control
01b = Heater is being held at a specified level
10b = ...";
CM_ SG_ 2566687998 Res "This sensor is located in the exhaust stream somewhere after the DPF, but not necessarily immediately after the DPF.  It provides a resistance value that can be used to determine particulate matter in the exhaust stream. The value in this parameter ...";
CM_ BO_ 2566687742 "Aftertreatment 1 Particulate Sensor Information 2
This message contains information for the particulate sensor in bank 1 of a 2 bank system or the particulate sensor in a single bank system.

This sensor is downstream of the DPF.";
CM_ SG_ 2566687742 HtrRes "The resistance of the particulate sensor heater.";
CM_ SG_ 2566687742 MaxRes "This is the maximum resistance that the particulate sensor can measure.";
CM_ SG_ 2566687742 Temp "Temperature of the particulate sensor.";
CM_ SG_ 2566687742 RegenFailedCount "This is the number of times that the particulate sensor regeneration process has been attempted but failed to complete this power cycle.";
CM_ SG_ 2566687742 PwrSupply "State signal which indicates when the Aftertreatment 1 particulate sensor has power applied to it. Note that this is referring to the power supplied to the sensor, not the power supplied to the controller connected to the sensor.
00b = Off
01b = ...";
CM_ SG_ 2566687742 DetectionSt "Detection status of the particulate sensor
0000b = Initialization for particulate matter detection
0001b = Waiting for dew point (see SPN 6784)
0010b = Particulate matter detection
0011b = Heater is active for particulate sensor regeneration
 ...";
CM_ BO_ 2365348350 "Engine Load Sharing Information
This PG contains information relating to integrated engine load sharing status values.";
CM_ SG_ 2365348350 ShareActiveCirc "The circuit that communicates the 'Load Share Active' status via an analog signal, such as a digital output signal from the ECU.

00b = Off
01b = On
10b = Error
11b = Not available";
CM_ SG_ 2365348350 EngLoadShareStatus "This signal indicates that the status of an engine load sharing feature.

0000b = Offline
0001b = Master
0010b = Slave
0011b = Loading
0100b = Unloading
0101b to 1101b = Reserved
1110b = Error
1111b = Unavailable";
CM_ SG_ 2365348350 EngUnloadStatus "This signal indicates the status of an external request to unload the engine, such as the external unload request switch.

00b = Not Requested
01b = Requested
10b = Error
11b = Not Available";
CM_ BO_ 2566674686 "Turbocharger Information 7
Turbocharger Information";
CM_ SG_ 2566674686 EngTC2OilTemp "Temperature of the lubricant for the second turbocharger.";
CM_ SG_ 2566674686 EngTurbo4LubeOilPress "Gage pressure of oil in the lubrication system for the 4th turbocharger.";
CM_ SG_ 2566674686 EngTurbo3LubeOilPress "Gage pressure of oil in the lubrication system for the 3rd turbocharger.";
CM_ SG_ 2566674686 EngTurbo2LubeOilPress "Gage pressure of oil in the lubrication system for the 2nd turbocharger.";
CM_ BO_ 2566674430 "SCR Operator Inducement Information 1
Contains timers that indicate how long specific causes for inducement have been active.";
CM_ SG_ 2566674430 DslExhstFldQalityMalfunctionTime "Indicates the amount of time an error has been active due to detection of low Diesel Exhaust Fluid Quality. This will accumulate over the life of the product and will never be reset.";
CM_ SG_ 2566674430 DieselExhaustFluidTank1EmptyTime "Indicates the time the Diesel Exhaust Fluid Tank 1 Level is indicated as empty. This will accumulate over the life of the product and will never be reset.";
CM_ BO_ 2566674174 "SCR Operator Inducement Information 2
Contains parameters that are related to SCR inducement.";
CM_ SG_ 2566674174 SCROperatorInducementTotalTime "Indicates the time that operator inducement has been active. This will accumulate over the life of the product and will never be reset.";
CM_ SG_ 2566674174 AFTSCRMalfunctionTime "Indicates the amount of time an error condition has been active due to a malfunction in the Aftertreatment SCR system.
The source of the malfunction condition could be a component failure, detection of tampering, or other reason that prevents ...";
CM_ BO_ 2566673406 "Engine Gaseous Leakage Information
Used to transmit the gaseous fuel leakage information determined by the engine monitoring system.";
CM_ SG_ 2566673406 GasLeakageDetection3Press "Pressure measured in gas leakage detection point 3. Measured media is of the gas, meaning it could be air, inert gas, fuel air mixture or charge air mixture, depending on the failure mode detected. The third measurement point is in a separate leak ...";
CM_ SG_ 2566673406 GasLeakageDetection2Press "Pressure measured in gas leakage detection point 2. Measured media is of the gas, meaning it could be air, inert gas, fuel air mixture or charge air mixture, depending on the failure mode detected. The second measurement point is either another ...";
CM_ SG_ 2566673406 GasLeakageDetection1Press "Pressure measured in gas leakage detection point 1. Measured media is of the gas, meaning it could be air, inert gas, fuel air mixture or charge air mixture, depending on the failure mode detected. The measurement point is typically in the engine ...";
CM_ SG_ 2566673406 GasFuelLeakage3Concentration "Percentage of detected gaseous fuel leak compared to the lower explosion limit (LEL). 100% means the measured value is on the lower explosion limit. 0% means no detected gaseous fuel in measurement point. The third measurement point is in a separate ...";
CM_ SG_ 2566673406 GasFuelLeakage2Concentration "Percentage of detected gaseous fuel leak compared to the lower explosion limit (LEL). 100% means the measured value is on the lower explosion limit. 0% means no detected gaseous fuel in measurement point. The second  measurement point is either ...";
CM_ SG_ 2566673406 GasFuelLeakage1Concentration "Percentage of detected gaseous fuel leak compared to the lower explosion limit (LEL). 100% means the measured value is on the lower explosion limit. 0% means no detected gaseous fuel in measurement point. The measurement point is typically in the ...";
CM_ BO_ 2633782014 "Bin Weight and Lift Count
Used to transmit bin weights.

Note:  This PG is transmitted for as many Bin Instances as exist on the vehicle.";
CM_ SG_ 2633782014 NetBinWeight "Mass of bin contents at most recent unload";
CM_ SG_ 2633782014 BinLiftCount "Increments with each lift, whether or not net bin weight changes.  The count rolls over at data range limit.

The count can be reset using SPN 6898 in PGN 56832.";
CM_ SG_ 2633782014 BinWeighingErrorStatus "Bin weighing error status

0 = No error
1 = Bad lift cycle
2 = Weighing error: bin lifted, not emptied
3 = Weighing error: empty bin lifted, emptied
4 to 14 = Reserved
15 = Not available / not applicable";
CM_ SG_ 2633782014 BinInstance "Gives the instance of the bin on the vehicle whose parameters are transmitted in the remainder of the PG, with the first or only bin as instance 1.";
CM_ BO_ 2365346302 "Air Suspension Control 7
Used for suspension control information";
CM_ SG_ 2365346302 LiftAxle4Status "Indicates the status of a tag axle 4. Numbering of lift/tag axles starts at front axle.
000b = Down (tag axle is laden)
001b = Unloading (load is being transferred from the tag axle)
010b = Lifting (tag axle is moving up)
011b = Up (tag axle is ...";
CM_ SG_ 2365346302 LiftAxle3Status "Indicates the status of a tag axle 3. Numbering of lift/tag axles starts at front axle.
000b = Down (tag axle is laden)
001b = Unloading (load is being transferred from the tag axle)
010b = Lifting (tag axle is moving up)
011b = Up (tag axle is ...";
CM_ SG_ 2365346302 LiftAxle2Status "Indicates the status of a tag axle 2.  Numbering of lift/tag axles starts at front axle.  SPN 1822 may be used if less detail is acceptable.
000b = Down (tag axle is laden)
001b = Unloading (load is being transferred from the tag axle)
010b = ...";
CM_ SG_ 2365346302 LiftAxle1Status "Indicates the status of a tag axle 1.  Numbering of lift/tag axles starts at front axle.  SPN 1743 may be used if less detail is acceptable.
000b = Down (tag axle is laden)
001b = Unloading (load is being transferred from the tag axle)
010b = ...";
CM_ BO_ 2566672638 "Payload System Status
Status Information for Payload Measurement Systems.
 
This provides the last haul cycle payload information to the operator.";
CM_ SG_ 2566672638 DeliveryTransactionStatus "The current state of the payload delivery transaction.
When a transaction is in progress, a receiving node may monitor Haul Cycle Count (SPN 6847) and Delivered Payload Weight (SPN 6849) in order to track the progress of a transaction, where the ...";
CM_ SG_ 2566672638 DeliveredPayloadConfidence "The level of confidence of the delivered payload weight measurement. Higher confidence values indicate greater probability the delivered payload weight is the actual weight and providing feedback on the potential for improving system accuracy.";
CM_ SG_ 2566672638 DeliveredPayloadWeight "The delivered payload mass during the last haul cycle. This is the amount of material moved and delivered by a machine is a key work cycle parameter.
Delivered payload weight is defined as the last loaded weight less the carry back weight (material ...";
CM_ SG_ 2566672638 HaulModeStatus "The current operating state of the haul cycle.
0000b = Not in Haul Mode
0001b = Loading -- Payload is being added to the machine
0010b = Approaching Loaded -- Machine is near its maximum capacity
0011b = Loaded -- Loading operation has been ...";
CM_ SG_ 2566672638 HaulCycleCount "A counter incremented by 1 with each instance of a new haul cycle, defined as a dump to dump cycle. The counter shall increment from 0 to 64255, rolling over to 0 on the next increment after 64255.";
CM_ BO_ 2566672382 "Payload Weight Sensor Information
Staus Information on each Payload sensor in a payload measurement system";
CM_ SG_ 2566672382 PayloadWeightSensor8Status "Status of the payload system sensor 8 measurement.

00b = Sensor fully functional
01b = Sensor degraded
10b = Error (Sensor failed)
11b = Not available";
CM_ SG_ 2566672382 PayloadWeightSensor7Status "Status of the payload system sensor 7 measurement.

00b = Sensor fully functional
01b = Sensor degraded
10b = Error (Sensor failed)
11b = Not available";
CM_ SG_ 2566672382 PayloadWeightSensor6Status "Status of the payload system sensor 6 measurement.

00b = Sensor fully functional
01b = Sensor degraded
10b = Error (Sensor failed)
11b = Not available";
CM_ SG_ 2566672382 PayloadWeightSensor5Status "Status of the payload system sensor 5 measurement.

00b = Sensor fully functional
01b = Sensor degraded
10b = Error (Sensor failed)
11b = Not available";
CM_ SG_ 2566672382 PayloadWeightSensor4Status "Status of the payload system sensor 4 measurement.

00b = Sensor fully functional
01b = Sensor degraded
10b = Error (Sensor failed)
11b = Not available";
CM_ SG_ 2566672382 PayloadWeightSensor3Status "Status of the payload system sensor 3 measurement.

00b = Sensor fully functional
01b = Sensor degraded
10b = Error (Sensor failed)
11b = Not available";
CM_ SG_ 2566672382 PayloadWeightSensor2Status "Status of the payload system sensor 2 measurement.

00b = Sensor fully functional
01b = Sensor degraded
10b = Error (Sensor failed)
11b = Not available";
CM_ SG_ 2566672382 PayloadWeightSensor1Status "Status of the payload system sensor 1 measurement.

00b = Sensor fully functional
01b = Sensor degraded
10b = Error (Sensor failed)
11b = Not available";
CM_ BO_ 2566672126 "Aftertreatment 1 SCR Dosing System Information 3
This message contains SCR dosing system information for aftertreatment system 1 (or bank 1).  See PGN 64833 for more information.";
CM_ SG_ 2566672126 DEFDoser1Press20906 "The SCR dosing diesel exhaust fluid gage pressure (measured closest to dosing valve) for aftertreatment system 1 (exhaust bank 1). 

See SPN 6875 for alternate range and resolution.";
CM_ SG_ 2566672126 DEFDoser2Press "The SCR doser 2 diesel exhaust fluid gage pressure (measured closest to dosing valve) for aftertreatment system 1 (exhaust bank 1). This is the gage equivalent to SPN 7459.

See SPN 20907 for alfternate range and resolution.";
CM_ SG_ 2566672126 DEFDoser2Temp "The temperature (measured closest to dosing valve) of the second DEF dosing unit for aftertreatment system 1 (exhaust bank 1).";
CM_ SG_ 2566672126 DEFDoser2AbsPress "The SCR doser 2 diesel exhaust fluid absolute pressure (measured closest to dosing valve) for aftertreatment system 1 (exhaust bank 1).";
CM_ SG_ 2566672126 DEFDoser1Press "The SCR dosing diesel exhaust fluid gage pressure (measured closest to dosing valve) for aftertreatment system 1 (exhaust bank 1). This is the gage equivalent to SPN 4334.

See SPN 20906 for alternate range and resolution.";
CM_ BO_ 2566671870 "Aftertreatment 2 SCR Dosing System Information 3
This message contains SCR dosing system information for aftertreatment system 2 (or bank 2).";
CM_ SG_ 2566671870 DEFDoser1Press20909 "The SCR dosing diesel exhaust fluid gage pressure (measured closest to dosing valve) for aftertreatment system 2 (exhaust bank 2). 

See SPN 6876 for alternate range and resolution.";
CM_ SG_ 2566671870 DEFDoser2Press "The SCR doser 2 diesel exhaust fluid gage pressure (measured closest to dosing valve) for aftertreatment system 2 (exhaust bank ). This is the gage equivalent to SPN 7464.

See SPN 20910 for alfternate range and resolution.";
CM_ SG_ 2566671870 DEFDoser2Temp "The temperature (measured closest to doser valve) of the second DEF doser unit for aftertreatment system 2 (exhaust bank 2).";
CM_ SG_ 2566671870 DEFDoser2AbsPress "The SCR doser 2 diesel exhaust fluid absolute pressure (measured closest to dosing valve) for aftertreatment system 2 (exhaust bank 2).";
CM_ SG_ 2566671870 DEFDoser1Press "The SCR dosing diesel exhaust fluid gage pressure (measured closest to dosing valve) for aftertreatment system 2 (exhaust bank 2). This is the gage equivalent to SPN 4387.

See SPN 20909 for alternate range and resolution.";
CM_ BO_ 2566671614 "SCR Operator Inducement Information 3
Contains parameters related to overriding the operator inducement.";
CM_ SG_ 2566671614 TtlNmbrOfSCROprtrIndcmntOvrrdEvn "Indicates total number of operator inducement override events activated throughout the lifetime of engine operation.
This number will remain at the maximum value once it is reached.
See EU Commission directive 2012/46/EU. Appendix 1 Section 5.5 ...";
CM_ SG_ 2566671614 NmbrOfSCROprtrIndcmntOvrrdEvntsR "During an operator inducement event, the operator may be able to override the inducement multiple times. This parameter indicates the remaining number of times that the currently active inducement can be overridden during an operator inducement ...";
CM_ SG_ 2566671614 SCROprtrIndcmntOvrrdTmeRemaining "This parameter is used to indicate the time remaining during an operator inducement override event.  See also SPN 7344 for an alternate SLOT.
When an operator inducement is not active, this parameter indicates the maximum time that an operator ...";
CM_ SG_ 2566671614 SCROprtrInducementOverrideEnable "Indicates if an operator inducement derate is allowed to be overridden.
Note: Inducement override is only allowed under certain conditions approved by EPA/ARB.
00b = Override not allowed
01b = Override allowed
10b = SAE Reserved
11b = Not ...";
CM_ BO_ 2566671358 "Electronic Engine Controller 17
This message includes some parameters that are used to support PEMS.
Manufacturers that support this PG shall support both PEMS Engine Fuel Mass Flow Rate (SPN 6893) and Vehicle Fuel Rate (SPN 6894) even if the ...";
CM_ SG_ 2566671358 CylFuelRate "Cylinder fuel rate shall indicate the amount of fuel injected into the cylinder for combustion during the most recent intake stroke of the engine.

NOTE: Cylinder fuel rate shall indicate zero mg/stroke when the engine is not running.";
CM_ SG_ 2566671358 EngExhaustFlowRate "Engine Exhaust Flow Rate shall indicate the measured/calculated exhaust gas mass flow upstream of the aftertreatment system.
Engine Exhaust Flow Rate shall be calculated as the average exhaust flow rate over the last 1000 milliseconds prior to the ...";
CM_ SG_ 2566671358 VehicleFuelRate "Vehicle Fuel Rate shall indicate the amount of fuel consumed by the engine and fuel injected directly into the aftertreatment system per unit of time, in grams per second.
Vehicle Fuel Rate shall be calculated as the sum of the fuel consumed over ...";
CM_ SG_ 2566671358 PEMSEngFuelMassFlowRate "PEMS Engine Fuel Mass Flow Rate shall indicate the amount of fuel consumed by the engine per unit of time (does not include fuel injected directly into the aftertreatment system, but does include fuel injected into the engine cylinders for the ...";
CM_ BO_ 2566671102 "SCR System Cleaning
Contains information about cleaning the SCR system in the aftertreatment system.
If there are aftertreatment systems on two banks, this PG represents the composite information from both banks.
NOTE: This message will be ...";
CM_ SG_ 2566671102 AFT1CondNotMetForActiveClean "Indicates that SCR System 1 is not able to begin or continue an active cleaning event at the current engine operating conditions.
00b = SCR System Cleaning not Inhibited
01b = SCR System Cleaning Inhibited
10b = Reserved for SAE Assignment
11b = ...";
CM_ SG_ 2566671102 SCRSystemCleaningForcedStatus "Indicates the forced execution status of SCR system cleaning.
000b = Not Active
001b = Active - Forced by Switch (See SPN 3696)
010b = Active - Forced by Service Tool
011b = Reserved for SAE Assignment
100b = Reserved for SAE Assignment
101b = ...";
CM_ SG_ 2566671102 SCRSystmClnngAtmtcIntationConfig "Indicates the configuration of SCR system cleaning automatic initiation.

00b = not enabled
01b = enabled
10b = reserved for SAE assignment
11b = not available";
CM_ SG_ 2566671102 SCRSystmClnngInhbtdDTVhclSpdBlwA "Indicates the state of SCR system cleaning inhibition due to the vehicle speed being less than the allowed vehicle speed.
00b = not inhibited
01b = inhibited
10b = reserved for SAE assignment
11b = not available
This SP indicates the reason for ...";
CM_ SG_ 2566671102 SCRSystmClnngInhbtdDTEngNtWrmdUp "Indicates the state of SCR system cleaning inhibition due to the engine not being warmed up.
00b = not inhibited
01b = inhibited
10b = reserved for SAE assignment
11b = not available
This SP indicates the reason for the SCR system cleaning ...";
CM_ SG_ 2566671102 SCRSystmClnngInhbtdDTPrmnntSystm "Indicates the state of SCR system cleaning inhibition due to a permanent system lockout.
00b = not inhibited
01b = inhibited
10b = reserved for SAE assignment
11b = not available
This SP indicates the reason for the SCR system cleaning event ...";
CM_ SG_ 2566671102 SCRSystmClnngInhbtdDTTmprrySystm "Indicates the state of SCR system cleaning inhibition due to a temporary system lockout.
00b = not inhibited
01b = inhibited
10b = reserved for SAE assignment
11b = not available
This SP indicates the reason for the SCR system cleaning event ...";
CM_ SG_ 2566671102 SCRSystmClnngInhbtdDTSystmTmeout "Indicates the state of SCR system cleaning inhibition due to a system timeout.
00b = not inhibited
01b = inhibited
10b = reserved for SAE assignment
11b = not available
This SP indicates the reason for the SCR system cleaning event not being ...";
CM_ SG_ 2566671102 SCRSystmClnngInhbtdDTSystmFltAct "Indicates the state of SCR system cleaning inhibition due to a system fault being active.
00b = not inhibited
01b = inhibited
10b = reserved for SAE assignment
11b = not available
This SP indicates the reason for the SCR system cleaning event ...";
CM_ SG_ 2566671102 SCRSystmClnngInhbtdDTLwExhstTemp "Indicates the state of SCR system cleaning inhibition due to the exhaust temperature being too low.  This implies that the SCR system is too cold for cleaning.
00b = not inhibited
01b = inhibited
10b = reserved for SAE assignment
11b = not ...";
CM_ SG_ 2566671102 SCRSystmClnngInhbtdDTPrkngBrkNtS "Indicates the state of SCR system cleaning inhibition due to the parking brake being not set.
00b = not inhibited
01b = inhibited
10b = reserved for SAE assignment
11b = not available
This SP indicates the reason for the SCR system cleaning ...";
CM_ SG_ 2566671102 SCRSystmClnngInhbtdDTVhclSpdAbvA "Indicates the state of SCR system cleaning inhibition due to the vehicle speed being above an allowed limit.
00b = not inhibited
01b = inhibited
10b = reserved for SAE assignment
11b = not available
This SP indicates the reason for the SCR ...";
CM_ SG_ 2566671102 SCRSystmClnngInhbtdDTOtOfNeutral "Indicates the state of SCR system cleaning inhibition due to the accelerator pedal being out of neutral.
00b = not inhibited
01b = inhibited
10b = reserved for SAE assignment
11b = not available
This SP indicates the reason for the SCR system ...";
CM_ SG_ 2566671102 SCRSystmClnngInhbtdDTAcclPdlOffI "Indicates the state of SCR system cleaning inhibition due to the accelerator pedal being off idle.
00b = not inhibited
01b = inhibited
10b = reserved for SAE assignment
11b = not available
This SP indicates the reason for the SCR system ...";
CM_ SG_ 2566671102 SCRSystmClnngInhbtdDeToPTOActive "Indicates the state of SCR system cleaning inhibition due to the PTO being active.
00b = not inhibited
01b = inhibited
10b = reserved for SAE assignment
11b = not available
This SP indicates the reason for the SCR system cleaning event not ...";
CM_ SG_ 2566671102 SCRSystmClnngInhbtdDTSrvcBrkActv "Indicates the state of SCR system cleaning inhibition due to the service brake being active.
00b = not inhibited
01b = inhibited
10b = reserved for SAE assignment
11b = not available
This SP indicates the reason for the SCR system cleaning ...";
CM_ SG_ 2566671102 SCRSystmClnngInhbtdDTCltchDsnggd "Indicates the state of SCR system cleaning event inhibition due to the clutch being disengaged.
00b = not inhibited
01b = inhibited
10b = reserved for SAE assignment
11b = not available
This SP indicates the reason for the SCR system cleaning ...";
CM_ SG_ 2566671102 SCRSystmClnngInhbtdDTInhbtSwitch "Indicates the state of SCR system cleaning inhibition due to the SCR system cleaning Inhibit Switch.
00b = not inhibited
01b = inhibited
10b = reserved for SAE assignment
11b = not available
This SP indicates the reason for the SCR system ...";
CM_ SG_ 2566671102 SCRSystemCleaningInhibitedStatus "Indicates the state of SCR system cleaning inhibition.
00b = not inhibited
01b = inhibited
10b = reserved for SAE assignment
11b = not available
This SP indicates the reason for the SCR system cleaning event not being initiated or being exited ...";
CM_ SG_ 2566671102 SCRSystemCleaningStatus "Indicates the state of SCR system cleaning.  This is an aggregate of bank 1 and bank 2.  It is a system status and not individual bank status.
00b = not active
01b = active
10b = SCR system cleaning is needed - automatically initiated SCR system ...";
CM_ SG_ 2566671102 SCRSystemCleaningLampCmd "Command to control the SCR system cleaning lamp.
000b = Off
001b = On - solid
010b = reserved for SAE assignment
011b = reserved for SAE assignment
100b = On - fast blink (1 HZ)
101b = reserved for SAE assignment
110b = reserved for SAE ...";
CM_ BO_ 2566670846 "Aftertreatment 1 Historical Information 2
Contains information about the history of the aftertreatment 1 system";
CM_ SG_ 2566670846 TotalAFTOperatingHours "Accumulated time of operation of aftertreatment system.  Operating hours are accumulated only when there is air flowing thru the aftertreatment system.";
CM_ SG_ 2566670846 SCRSysAvgDistBetweenCleanEvents "Indicates the average distance since last reset between cleaning events for the SCR system in bank 1.

If the manufacturer allows this parameter to be reset, this distance is the average since last reset.";
CM_ SG_ 2566670846 SCRSysAvgTimeBetweenCleanEvents "Indicates the average time since last reset between cleaning events for the SCR system in bank 1.
 
If the manufacturer allows this parameter to be reset, this time is the average since last reset.";
CM_ SG_ 2566670846 SCRSysTotalSysCleanManReq "Total number of manual cleaning requests on the SCR system in bank 1 by the operator over the lifetime of the device.";
CM_ SG_ 2566670846 SCRSysTotalSysCleanInhReq "Total number of cleaning inhibit requests on the SCR system in bank 1 by the operator over the lifetime of the device.";
CM_ SG_ 2566670846 SCRSysTotalSysCleanEvents "Total number of cleaning events that have occurred on the SCR system in bank 1 over the lifetime of the device.";
CM_ SG_ 2566670846 SCRSysTotalCleanTime "Total amount of time that a cleaning event has been active in the SCR system in bank 1 over the lifetime of the device.";
CM_ BO_ 2566670590 "Aftertreatment 2 Historical Information 2
Contains information about the history of the aftertreatment 2 system";
CM_ SG_ 2566670590 SCRSysAvgDistBetweenCleanEvents "Indicates the average distance since last reset between cleaning events for the SCR system in bank 2.

If the manufacturer allows this parameter to be reset, this distance is the average since last reset.";
CM_ SG_ 2566670590 SCRSysAvgTimeBetweenCleanEvents "Indicates the average time since last reset between cleaning events for the SCR system in bank 2.

If the manufacturer allows this parameter to be reset, this time is the average since last reset.";
CM_ SG_ 2566670590 SCRSysTotalSysCleanManReq "Total number of manual cleaning requests on the SCR system in bank 2 by the operator over the lifetime of the device.";
CM_ SG_ 2566670590 SCRSysTotalSysCleanInhReq "Total number of cleaning inhibit requests on the SCR system in bank 2 by the operator over the lifetime of the device.";
CM_ SG_ 2566670590 SCRSysTotalSysCleanEvents "Total number of cleaning events that have occurred on the SCR system in bank 2 over the lifetime of the device.";
CM_ SG_ 2566670590 SCRSysTotalSysCleanTime "Total amount of time that a cleaning event has been active in the SCR system in bank 2 over the lifetime of the device.";
CM_ BO_ 2566670334 "Monitored Tire Information
Used by the tire monitoring system to report the number of tires, number of axles and number of tires on each axle it is monitoring on a specific vehicle. The axle number increments from front to rear of the vehicle per ...";
CM_ SG_ 2566670334 Axle12MonitoredTireCount "The number of tires on Axle 12 which are monitored by the tire monitor controller. The axle number increments from front to rear of the vehicle when facing the vehicle in the forward vehicle travel orientation. If the axle is not monitored by the ...";
CM_ SG_ 2566670334 Axle11MonitoredTireCount "The number of tires on Axle 11 which are monitored by the tire monitor controller. The axle number increments from front to rear of the vehicle when facing the vehicle in the forward vehicle travel orientation. If the axle is not monitored by the ...";
CM_ SG_ 2566670334 Axle10MonitoredTireCount "The number of tires on Axle 10 which are monitored by the tire monitor controller. The axle number increments from front to rear of the vehicle when facing the vehicle in the forward vehicle travel orientation. If the axle is not monitored by the ...";
CM_ SG_ 2566670334 Axle9MonitoredTireCount "The number of tires on Axle 9 which are monitored by the tire monitor controller. The axle number increments from front to rear of the vehicle when facing the vehicle in the forward vehicle travel orientation. If the axle is not monitored by the ...";
CM_ SG_ 2566670334 Axle8MonitoredTireCount "The number of tires on Axle 8 which are monitored by the tire monitor controller. The axle number increments from front to rear of the vehicle when facing the vehicle in the forward vehicle travel orientation. If the axle is not monitored by the ...";
CM_ SG_ 2566670334 Axle7MonitoredTireCount "The number of tires on Axle 7 which are monitored by the tire monitor controller. The axle number increments from front to rear of the vehicle when facing the vehicle in the forward vehicle travel orientation. If the axle is not monitored by the ...";
CM_ SG_ 2566670334 Axle6MonitoredTireCount "The number of tires on Axle 6 which are monitored by the tire monitor controller. The axle number increments from front to rear of the vehicle when facing the vehicle in the forward vehicle travel orientation. If the axle is not monitored by the ...";
CM_ SG_ 2566670334 Axle5MonitoredTireCount "The number of tires on Axle 5 which are monitored by the tire monitor controller. The axle number increments from front to rear of the vehicle when facing the vehicle in the forward vehicle travel orientation. If the axle is not monitored by the ...";
CM_ SG_ 2566670334 Axle4MonitoredTireCount "The number of tires on Axle 4 which are monitored by the tire monitor controller. The axle number increments from front to rear of the vehicle when facing the vehicle in the forward vehicle travel orientation. If the axle is not monitored by the ...";
CM_ SG_ 2566670334 Axle3MonitoredTireCount "The number of tires on Axle 3 which are monitored by the tire monitor controller. The axle number increments from front to rear of the vehicle when facing the vehicle in the forward vehicle travel orientation. If the axle is not monitored by the ...";
CM_ SG_ 2566670334 Axle2MonitoredTireCount "The number of tires on Axle 2 which are monitored by the tire monitor controller. The axle number increments from front to rear of the vehicle when facing the vehicle in the forward vehicle travel orientation. If the axle is not monitored by the ...";
CM_ SG_ 2566670334 Axle1MonitoredTireCount "The number of tires on Axle 1 which are monitored by the tire monitor controller. The axle number increments from front to rear of the vehicle when facing the vehicle in the forward vehicle travel orientation. If the axle is not monitored by the ...";
CM_ SG_ 2566670334 NumberOfTiresOnTheVehicle "The total number of tires monitored for tire parameters. A maximum of 250 tires is defined.";
CM_ SG_ 2566670334 NumberOfAxlesOnTheVehicle "The number of axles monitored for tire parameters. A maximum of 12 axles is defined.";
CM_ BO_ 2566670078 "Tire Sensor Identification Status
The tire sensor identification number for each monitored tire.
Since there are multiple tire sensors to report, the message format will be a,b,c,d,b,c,d,b,c,d,b,c,d,...etc. where
a = Number of Tire Sensors
b = ...";
CM_ SG_ 2566670078 TireSensorIdentificationNumber "The identification number of the tire specified in the tire number (SPN 6964) or tire location (SPN 6965).";
CM_ SG_ 2566670078 TireSensorLocation "The location of monitored tire that corresponds with the Tire Sensor Identification Number (SPN 6966). In order to specify the monitored tire by tire number, use the Tire Number SPN 6964.
The high order 4 bits indicate the vehicle axle position of ...";
CM_ SG_ 2566670078 TireSensorTireNumber "The number of the monitored tire that corresponds with the Tire Sensor Identification Number (SPN 6966).  In order to specify the monitored tire by location, use the Tire Location SPN 6965.

The value FFh indicates this SP is not used.";
CM_ SG_ 2566670078 NumberOfTireSensors "Total count of monitored tire sensor identification numbers represented in this instance of the parameter group.";
CM_ BO_ 2566669822 "Tire Wireless Signal Strength Indicator
The tire wireless signal strength indicator for each monitored tire. If there are multiple tire sensors with multiple antennas to report, the message format will be ...";
CM_ SG_ 2566669822 TrWrelessSignalStrengthIndicator "The wireless signal strength between the tire pressure sensor and the specified antenna, for the tire specified in the tire sensor number or tire sensor Location.";
CM_ SG_ 2566669822 TireLocation "The location of monitored tire on the vehicle.
The high order 4 bits indicate the vehicle axle position of the tire sensor, counting front to back on the vehicle, with the value 0 representing the front axle on the vehicle.
The low order 4 bits ...";
CM_ SG_ 2566669822 TireSensorNumber "The number of the monitored tire sensor that corresponds with the tire wireless signal strength indicator. The location of the numbered tire is reported in the tire sensor location SP (SPN 6965). The value FFh indicates this SP is not used.";
CM_ SG_ 2566669822 TtalNumberOfTireSensorsMonitored "Total number of tire sensors monitored for the specified antenna in this instance of the parameter group.";
CM_ SG_ 2566669822 AntennaNumber "Number of the antenna used to communicate signal strength of a group of sensors.  If a single antenna is used this will default to 01h. When multiple antennas are used, the first antenna will have a value of 1, 2nd antenna will be 2, 3rd antenna ...";
CM_ SG_ 2566669822 TotalNumberOfAntennasUsed "Total count of antennas used in the specified vehicle system.";
CM_ BO_ 2566669310 "Tire Configuration Status Information
Details the attributes for the tire monitoring configuration status of the tires.
NOTE – Multiple instances of this message will be required to transmit data for all tire locations.  When reporting data for ...";
CM_ SG_ 2566669310 OverTemp "The temperature above which the over temperature alert will trigger.";
CM_ SG_ 2566669310 OverPressPercentageThreshold "The percentage deviation from the set cold inflation pressure, for the over tire pressure alert.";
CM_ SG_ 2566669310 ExtrmUndrPrssPercentageThreshold "The percentage deviation from the set cold inflation pressure, for the extreme under tire pressure alert.";
CM_ SG_ 2566669310 UnderPressPercentageThreshold "The percentage deviation from the set cold inflation pressure, for the under tire pressure alert.";
CM_ SG_ 2566669310 ColdInflationPress "The cold inflation pressure of the tire. Cold inflation pressure is the default/reference inflation pressure suggested by the manufacturer for a specific tire.";
CM_ SG_ 2566669310 TireLocation "The location of monitored tire on the vehicle.
The high order 4 bits indicate the vehicle axle position of the tire sensor, counting front to back on the vehicle, with the value 0 representing the front axle on the vehicle.
The low order 4 bits ...";
CM_ BO_ 2566669054 "Tire Condition Message 2
Tire Condition Message 2
NOTE – Multiple instances of this message will be required to transmit data for all tire locations.  When reporting data for multiple tire locations, each successive message, which provides data ...";
CM_ SG_ 2566669054 RequiredTirePress "The required tire pressure at which air is contained in cavity formed by tire and rim.

This pressure of the tire is compensated to meet the specific physical environmental conditions (temperature) of the vehicle.";
CM_ SG_ 2566669054 TirePress "Pressure at which air is contained in cavity formed by tire and rim. See SPN 241 for alternate tire pressure with a lower range and coarser resolution.";
CM_ SG_ 2566669054 TireLocation "Identifies which tire is associated with the parametric data in PGN 64578. Refer to SPN 929 for further details and examples. The low order 4 bits represent a position number, counting left to right when facing in the direction of normal vehicle ...";
CM_ BO_ 2566668798 "Alternate Fuel 4";
CM_ SG_ 2566668798 EngFl2InjctorMeteringRail1Press2 "The second pressure of fuel 2 measured by first rail pressure sensor in the primary, or first, metering rail as delivered from the supply pump to the injector metering intake.";
CM_ SG_ 2566668798 EngFel2InjectorMeteringRail2Temp "The temperature of fuel 2 measured by first rail temperature sensor in the metering rail 2 as delivered from the supply pump to the injector metering intake.";
CM_ SG_ 2566668798 EngFel2InjectorMeteringRail1Temp "The temperature of fuel 2 measured by first rail temperature sensor in the primary, or first, metering rail as delivered from the supply pump to the injector metering intake.";
CM_ SG_ 2566668798 EngFl2InjectorMeteringRail2Press "The pressure of fuel 2 measured by first rail pressure sensor in the metering rail 2 as delivered from the supply pump to the injector metering intake.";
CM_ SG_ 2566668798 EngFl2InjectorMeteringRail1Press "The pressure of fuel 2 measured by first rail pressure sensor in the primary, or first, metering rail as delivered from the supply pump to the injector metering intake.";
BA_DEF_ SG_  "GenSigInactiveValue" INT 0 0;
BA_DEF_ SG_  "SigType" ENUM  "Default","Range","RangeSigned","ASCII","Discrete","Control","ReferencePGN","DTC","StringDelimiter","StringLength","StringLengthControl","MessageCounter","MessageChecksum";
BA_DEF_ SG_  "GenSigStartValue" INT 0 2147483647;
BA_DEF_ SG_  "GenSigSendType" ENUM  "Cyclic","OnWrite","OnWriteWithRepetition","OnChange","OnChangeWithRepetition","IfActive","IfActiveWithRepetition","NoSigSendType";
BA_DEF_ SG_  "GenSigILSupport" ENUM  "No","Yes";
BA_DEF_ SG_  "SPN" INT 0 524287;
BA_DEF_ BO_  "J1939CPgSendTimeout" INT -1 3600000;
BA_DEF_ BO_  "J1939CPgTOS" INT 0 7;
BA_DEF_ BO_  "J1939PgAppearanceOnBus" ENUM  "Default","CAN_Extended","CANFD_Extended";
BA_DEF_ BO_  "FsJ1939UseCrcAndCounter" STRING ;
BA_DEF_ BO_  "TpJ1939VarDlc" ENUM  "No","Yes";
BA_DEF_ BO_  "GenMsgNrOfRepetition" INT 0 1000000;
BA_DEF_ BO_  "GenMsgCycleTimeFast" INT 0 3600000;
BA_DEF_ BO_  "GenMsgFastOnStart" INT 0 100000;
BA_DEF_ BO_  "GenMsgStartDelayTime" INT 0 100000;
BA_DEF_ BO_  "GenMsgILSupport" ENUM  "No","Yes";
BA_DEF_ BO_  "GenMsgDelayTime" INT 0 1000;
BA_DEF_ BO_  "GenMsgRequestable" INT 0 1;
BA_DEF_ BO_  "GenMsgSendType" ENUM  "cyclic","NotUsed","NotUsed","NotUsed","NotUsed","NotUsed","NotUsed","IfActive","noMsgSendType";
BA_DEF_ BO_  "VFrameFormat" ENUM  "StandardCAN","ExtendedCAN","reserved","J1939PG","reserved","reserved","reserved","reserved","reserved","reserved","reserved","reserved","reserved","reserved","StandardCAN_FD","ExtendedCAN_FD";
BA_DEF_ BO_  "SingleFrame" INT 0 1;
BA_DEF_ BO_  "GenMsgCycleTime" INT 0 3600000;
BA_DEF_ SG_  "SystemSignalLongSymbol" STRING ;
BA_DEF_DEF_  "GenSigInactiveValue" 0;
BA_DEF_DEF_  "SigType" "Default";
BA_DEF_DEF_  "GenSigStartValue" 0;
BA_DEF_DEF_  "GenSigSendType" "NoSigSendType";
BA_DEF_DEF_  "GenSigILSupport" "Yes";
BA_DEF_DEF_  "SPN" 0;
BA_DEF_DEF_  "J1939CPgSendTimeout" -1;
BA_DEF_DEF_  "J1939CPgTOS" 2;
BA_DEF_DEF_  "J1939PgAppearanceOnBus" "Default";
BA_DEF_DEF_  "FsJ1939UseCrcAndCounter" "";
BA_DEF_DEF_  "TpJ1939VarDlc" "No";
BA_DEF_DEF_  "GenMsgNrOfRepetition" 0;
BA_DEF_DEF_  "GenMsgCycleTimeFast" 0;
BA_DEF_DEF_  "GenMsgFastOnStart" 0;
BA_DEF_DEF_  "GenMsgStartDelayTime" 0;
BA_DEF_DEF_  "GenMsgILSupport" "Yes";
BA_DEF_DEF_  "GenMsgDelayTime" 0;
BA_DEF_DEF_  "GenMsgRequestable" 1;
BA_DEF_DEF_  "GenMsgSendType" "noMsgSendType";
BA_DEF_DEF_  "VFrameFormat" "J1939PG";
BA_DEF_DEF_  "SingleFrame" 1;
BA_DEF_DEF_  "GenMsgCycleTime" 0;
BA_DEF_DEF_  "SystemSignalLongSymbol" "";
BA_ "GenMsgSendType" BO_ 2558394110 0;
BA_ "GenMsgCycleTime" BO_ 2558394110 1000;
BA_ "GenMsgSendType" BO_ 2558263038 0;
BA_ "GenMsgCycleTime" BO_ 2558263038 1000;
BA_ "GenMsgSendType" BO_ 2558197502 0;
BA_ "GenMsgCycleTime" BO_ 2558197502 1000;
BA_ "GenMsgSendType" BO_ 2558131966 0;
BA_ "GenMsgCycleTime" BO_ 2558131966 1000;
BA_ "GenMsgSendType" BO_ 2558066430 0;
BA_ "GenMsgCycleTime" BO_ 2558066430 1000;
BA_ "GenMsgSendType" BO_ 2558000894 0;
BA_ "GenMsgCycleTime" BO_ 2558000894 1000;
BA_ "GenMsgSendType" BO_ 2557935358 0;
BA_ "GenMsgCycleTime" BO_ 2557935358 1000;
BA_ "GenMsgSendType" BO_ 2557869822 0;
BA_ "GenMsgCycleTime" BO_ 2557869822 1000;
BA_ "GenMsgSendType" BO_ 2557804286 0;
BA_ "GenMsgCycleTime" BO_ 2557804286 1000;
BA_ "GenMsgSendType" BO_ 2557738750 0;
BA_ "GenMsgCycleTime" BO_ 2557738750 1000;
BA_ "TpJ1939VarDlc" BO_ 2624716542 1;
BA_ "FsJ1939UseCrcAndCounter" BO_ 2350644990 "Aa";
BA_ "GenMsgSendType" BO_ 2350644990 0;
BA_ "GenMsgCycleTime" BO_ 2350644990 20;
BA_ "GenMsgSendType" BO_ 2566658558 0;
BA_ "GenMsgCycleTime" BO_ 2566658558 5000;
BA_ "GenMsgSendType" BO_ 2566658302 0;
BA_ "GenMsgCycleTime" BO_ 2566658302 5000;
BA_ "GenMsgSendType" BO_ 2499549182 0;
BA_ "GenMsgCycleTime" BO_ 2499549182 1000;
BA_ "GenMsgSendType" BO_ 2499548926 0;
BA_ "GenMsgCycleTime" BO_ 2499548926 1000;
BA_ "GenMsgSendType" BO_ 2499548670 0;
BA_ "GenMsgCycleTime" BO_ 2499548670 100;
BA_ "GenMsgDelayTime" BO_ 2499548158 100;
BA_ "GenMsgSendType" BO_ 2499548158 0;
BA_ "GenMsgCycleTime" BO_ 2499548158 1000;
BA_ "GenMsgDelayTime" BO_ 2499547902 100;
BA_ "GenMsgSendType" BO_ 2499547902 0;
BA_ "GenMsgCycleTime" BO_ 2499547902 1000;
BA_ "GenMsgSendType" BO_ 2314732542 0;
BA_ "GenMsgCycleTime" BO_ 2314732542 100;
BA_ "FsJ1939UseCrcAndCounter" BO_ 2431710718 "Da";
BA_ "GenMsgDelayTime" BO_ 2431710718 20;
BA_ "FsJ1939UseCrcAndCounter" BO_ 2431708670 "Da";
BA_ "GenMsgDelayTime" BO_ 2431708670 20;
BA_ "GenMsgSendType" BO_ 2565926142 0;
BA_ "GenMsgCycleTime" BO_ 2565926142 50;
BA_ "GenMsgSendType" BO_ 2565925886 0;
BA_ "GenMsgCycleTime" BO_ 2565925886 50;
BA_ "GenMsgSendType" BO_ 2565925630 0;
BA_ "GenMsgCycleTime" BO_ 2565925630 50;
BA_ "GenMsgSendType" BO_ 2565925374 0;
BA_ "GenMsgCycleTime" BO_ 2565925374 50;
BA_ "GenMsgSendType" BO_ 2364598526 0;
BA_ "GenMsgCycleTime" BO_ 2364598526 50;
BA_ "GenMsgSendType" BO_ 2565900286 0;
BA_ "GenMsgCycleTime" BO_ 2565900286 100;
BA_ "TpJ1939VarDlc" BO_ 2558525182 1;
BA_ "GenMsgSendType" BO_ 2350841598 0;
BA_ "GenMsgCycleTime" BO_ 2350841598 200;
BA_ "FsJ1939UseCrcAndCounter" BO_ 2566838014 "Aa";
BA_ "GenMsgSendType" BO_ 2566838014 0;
BA_ "GenMsgCycleTime" BO_ 2566838014 1000;
BA_ "GenMsgSendType" BO_ 2566756350 0;
BA_ "GenMsgCycleTime" BO_ 2566756350 1000;
BA_ "GenMsgSendType" BO_ 2566756094 0;
BA_ "GenMsgCycleTime" BO_ 2566756094 1000;
BA_ "GenMsgSendType" BO_ 2566687998 0;
BA_ "GenMsgCycleTime" BO_ 2566687998 200;
BA_ "GenMsgSendType" BO_ 2566687742 0;
BA_ "GenMsgCycleTime" BO_ 2566687742 200;
BA_ "GenMsgDelayTime" BO_ 2365348350 50;
BA_ "GenMsgSendType" BO_ 2365348350 0;
BA_ "GenMsgCycleTime" BO_ 2365348350 500;
BA_ "GenMsgSendType" BO_ 2566674686 0;
BA_ "GenMsgCycleTime" BO_ 2566674686 1000;
BA_ "GenMsgDelayTime" BO_ 2566674430 1000;
BA_ "GenMsgSendType" BO_ 2566674430 0;
BA_ "GenMsgCycleTime" BO_ 2566674430 10000;
BA_ "GenMsgDelayTime" BO_ 2566674174 1000;
BA_ "GenMsgSendType" BO_ 2566674174 0;
BA_ "GenMsgCycleTime" BO_ 2566674174 10000;
BA_ "GenMsgSendType" BO_ 2566673406 0;
BA_ "GenMsgCycleTime" BO_ 2566673406 500;
BA_ "GenMsgDelayTime" BO_ 2633782014 1000;
BA_ "GenMsgSendType" BO_ 2633782014 0;
BA_ "GenMsgCycleTime" BO_ 2633782014 10000;
BA_ "GenMsgSendType" BO_ 2365346302 0;
BA_ "GenMsgCycleTime" BO_ 2365346302 100;
BA_ "GenMsgSendType" BO_ 2566672638 0;
BA_ "GenMsgCycleTime" BO_ 2566672638 1000;
BA_ "GenMsgSendType" BO_ 2566672382 0;
BA_ "GenMsgCycleTime" BO_ 2566672382 1000;
BA_ "GenMsgSendType" BO_ 2566672126 0;
BA_ "GenMsgCycleTime" BO_ 2566672126 500;
BA_ "GenMsgSendType" BO_ 2566671870 0;
BA_ "GenMsgCycleTime" BO_ 2566671870 500;
BA_ "GenMsgDelayTime" BO_ 2566671102 100;
BA_ "GenMsgSendType" BO_ 2566671102 0;
BA_ "GenMsgCycleTime" BO_ 2566671102 1000;
BA_ "TpJ1939VarDlc" BO_ 2566670078 1;
BA_ "TpJ1939VarDlc" BO_ 2566669822 1;
BA_ "GenMsgSendType" BO_ 2566669054 0;
BA_ "GenMsgCycleTime" BO_ 2566669054 10000;
BA_ "GenMsgSendType" BO_ 2566668798 0;
BA_ "GenMsgCycleTime" BO_ 2566668798 500;
BA_ "SPN" SG_ 2558394110 Instance15 8306;
BA_ "SPN" SG_ 2558394110 Instance14 8305;
BA_ "SPN" SG_ 2558394110 Instance13 8304;
BA_ "SPN" SG_ 2558394110 Instance12 8303;
BA_ "SPN" SG_ 2558394110 Instance11 8302;
BA_ "SPN" SG_ 2558394110 Instance10 8301;
BA_ "SPN" SG_ 2558394110 Instance9 8300;
BA_ "SPN" SG_ 2558394110 Instance8 8299;
BA_ "SPN" SG_ 2558394110 Instance7 8298;
BA_ "SPN" SG_ 2558394110 Instance6 8297;
BA_ "SPN" SG_ 2558394110 Instance5 8296;
BA_ "SPN" SG_ 2558394110 Instance4 8295;
BA_ "SPN" SG_ 2558394110 Instance3 8294;
BA_ "SPN" SG_ 2558394110 Instance2 8293;
BA_ "SPN" SG_ 2558394110 Instance1 8292;
BA_ "SigType" SG_ 2558394110 PercentSpdCmd 1;
BA_ "SPN" SG_ 2558394110 PercentSpdCmd 7946;
BA_ "SigType" SG_ 2558394110 SpdCmd 1;
BA_ "SPN" SG_ 2558394110 SpdCmd 7945;
BA_ "SigType" SG_ 2558394110 PwrHold 4;
BA_ "SPN" SG_ 2558394110 PwrHold 7944;
BA_ "SigType" SG_ 2558394110 EnableCmd 4;
BA_ "SPN" SG_ 2558394110 EnableCmd 7943;
BA_ "SigType" SG_ 2558263038 PercentSpdCmd 1;
BA_ "SPN" SG_ 2558263038 PercentSpdCmd 7970;
BA_ "SigType" SG_ 2558263038 SpdCmd 1;
BA_ "SPN" SG_ 2558263038 SpdCmd 7969;
BA_ "SigType" SG_ 2558263038 PwrHold 4;
BA_ "SPN" SG_ 2558263038 PwrHold 7968;
BA_ "SigType" SG_ 2558263038 EnableCmd 4;
BA_ "SPN" SG_ 2558263038 EnableCmd 7967;
BA_ "SigType" SG_ 2558197502 PercentSpdCmd 1;
BA_ "SPN" SG_ 2558197502 PercentSpdCmd 7982;
BA_ "SigType" SG_ 2558197502 SpdCmd 1;
BA_ "SPN" SG_ 2558197502 SpdCmd 7981;
BA_ "SigType" SG_ 2558197502 PwrHold 4;
BA_ "SPN" SG_ 2558197502 PwrHold 7980;
BA_ "SigType" SG_ 2558197502 EnableCmd 4;
BA_ "SPN" SG_ 2558197502 EnableCmd 7979;
BA_ "SigType" SG_ 2558131966 PercentSpdCmd 1;
BA_ "SPN" SG_ 2558131966 PercentSpdCmd 7994;
BA_ "SigType" SG_ 2558131966 SpdCmd 1;
BA_ "SPN" SG_ 2558131966 SpdCmd 7993;
BA_ "SigType" SG_ 2558131966 PwrHold 4;
BA_ "SPN" SG_ 2558131966 PwrHold 7992;
BA_ "SigType" SG_ 2558131966 EnableCmd 4;
BA_ "SPN" SG_ 2558131966 EnableCmd 7991;
BA_ "SigType" SG_ 2558066430 PercentSpdCmd 1;
BA_ "SPN" SG_ 2558066430 PercentSpdCmd 8006;
BA_ "SigType" SG_ 2558066430 SpdCmd 1;
BA_ "SPN" SG_ 2558066430 SpdCmd 8005;
BA_ "SigType" SG_ 2558066430 PwrHold 4;
BA_ "SPN" SG_ 2558066430 PwrHold 8004;
BA_ "SigType" SG_ 2558066430 EnableCmd 4;
BA_ "SPN" SG_ 2558066430 EnableCmd 8003;
BA_ "SigType" SG_ 2558000894 PercentSpdCmd 1;
BA_ "SPN" SG_ 2558000894 PercentSpdCmd 8018;
BA_ "SigType" SG_ 2558000894 SpdCmd 1;
BA_ "SPN" SG_ 2558000894 SpdCmd 8017;
BA_ "SigType" SG_ 2558000894 PwrHold 4;
BA_ "SPN" SG_ 2558000894 PwrHold 8016;
BA_ "SigType" SG_ 2558000894 EnableCmd 4;
BA_ "SPN" SG_ 2558000894 EnableCmd 8015;
BA_ "SigType" SG_ 2557935358 PercentSpdCmd 1;
BA_ "SPN" SG_ 2557935358 PercentSpdCmd 8030;
BA_ "SigType" SG_ 2557935358 SpdCmd 1;
BA_ "SPN" SG_ 2557935358 SpdCmd 8029;
BA_ "SigType" SG_ 2557935358 PwrHold 4;
BA_ "SPN" SG_ 2557935358 PwrHold 8028;
BA_ "SigType" SG_ 2557935358 EnableCmd 4;
BA_ "SPN" SG_ 2557935358 EnableCmd 8027;
BA_ "SigType" SG_ 2557869822 PercentSpdCmd 1;
BA_ "SPN" SG_ 2557869822 PercentSpdCmd 8042;
BA_ "SigType" SG_ 2557869822 SpdCmd 1;
BA_ "SPN" SG_ 2557869822 SpdCmd 8041;
BA_ "SigType" SG_ 2557869822 PwrHold 4;
BA_ "SPN" SG_ 2557869822 PwrHold 8040;
BA_ "SigType" SG_ 2557869822 EnableCmd 4;
BA_ "SPN" SG_ 2557869822 EnableCmd 8039;
BA_ "SigType" SG_ 2557804286 PercentSpdCmd 1;
BA_ "SPN" SG_ 2557804286 PercentSpdCmd 8054;
BA_ "SigType" SG_ 2557804286 SpdCmd 1;
BA_ "SPN" SG_ 2557804286 SpdCmd 8053;
BA_ "SigType" SG_ 2557804286 PwrHold 4;
BA_ "SPN" SG_ 2557804286 PwrHold 8052;
BA_ "SigType" SG_ 2557804286 EnableCmd 4;
BA_ "SPN" SG_ 2557804286 EnableCmd 8051;
BA_ "SigType" SG_ 2557738750 PercentSpdCmd 1;
BA_ "SPN" SG_ 2557738750 PercentSpdCmd 8066;
BA_ "SigType" SG_ 2557738750 SpdCmd 1;
BA_ "SPN" SG_ 2557738750 SpdCmd 8065;
BA_ "SigType" SG_ 2557738750 PwrHold 4;
BA_ "SPN" SG_ 2557738750 PwrHold 8064;
BA_ "SigType" SG_ 2557738750 EnableCmd 4;
BA_ "SPN" SG_ 2557738750 EnableCmd 8063;
BA_ "SPN" SG_ 2557673214 NFBin6CountCmd 8203;
BA_ "SPN" SG_ 2557673214 NFBin5CountCmd 8202;
BA_ "SPN" SG_ 2557673214 NFBin4CountCmd 8201;
BA_ "SPN" SG_ 2557673214 NFBin3CountCmd 8200;
BA_ "SPN" SG_ 2557673214 NFBin2CountCmd 8199;
BA_ "SPN" SG_ 2557673214 NFBin1CountCmd 8198;
BA_ "SPN" SG_ 2557673214 FBin6CountCmd 8197;
BA_ "SPN" SG_ 2557673214 FBin5CountCmd 8196;
BA_ "SPN" SG_ 2557673214 FBin4CountCmd 8195;
BA_ "SPN" SG_ 2557673214 FBin3CountCmd 8194;
BA_ "SPN" SG_ 2557673214 FBin2CountCmd 8193;
BA_ "SPN" SG_ 2557673214 FBin1CountCmd 8192;
BA_ "SigType" SG_ 2557673214 IdNum 1;
BA_ "SPN" SG_ 2557673214 IdNum 8191;
BA_ "SigType" SG_ 2624716542 CommandedTransmitPGNReqSt 5;
BA_ "SPN" SG_ 2624716542 CommandedTransmitPGNReqSt 8598;
BA_ "SPN" SG_ 2624716542 CommandedTransmitPGN 8597;
BA_ "SPN" SG_ 2624716542 TransactionMode 8596;
BA_ "SPN" SG_ 2624716542 CommandedPort 8595;
BA_ "SigType" SG_ 2350644990 ThermalMnmgtMaintenanceReq 5;
BA_ "SPN" SG_ 2350644990 ThermalMnmgtMaintenanceReq 20878;
BA_ "SigType" SG_ 2350644990 Ctrl1CRC 12;
BA_ "SPN" SG_ 2350644990 Ctrl1CRC 13028;
BA_ "SigType" SG_ 2350644990 Ctrl1Counter 11;
BA_ "SPN" SG_ 2350644990 Ctrl1Counter 13027;
BA_ "SigType" SG_ 2350644990 HVBusLowSideResistorConnectReq 5;
BA_ "SPN" SG_ 2350644990 HVBusLowSideResistorConnectReq 8434;
BA_ "SigType" SG_ 2350644990 HVBusHiSideResistorConnectReq 5;
BA_ "SPN" SG_ 2350644990 HVBusHiSideResistorConnectReq 8433;
BA_ "SigType" SG_ 2350644990 OpConsent 4;
BA_ "SPN" SG_ 2350644990 OpConsent 8412;
BA_ "SigType" SG_ 2350644990 EnableInternalChargerCmd 5;
BA_ "SPN" SG_ 2350644990 EnableInternalChargerCmd 8213;
BA_ "SigType" SG_ 2350644990 CellBalancingCmd 5;
BA_ "SPN" SG_ 2350644990 CellBalancingCmd 8127;
BA_ "SigType" SG_ 2350644990 HVBusPassiveIsolTestCmd 5;
BA_ "SPN" SG_ 2350644990 HVBusPassiveIsolTestCmd 8126;
BA_ "SigType" SG_ 2350644990 HVBusActiveIsolTestCmd 5;
BA_ "SPN" SG_ 2350644990 HVBusActiveIsolTestCmd 8125;
BA_ "SigType" SG_ 2350644990 PwrDownCmd 5;
BA_ "SPN" SG_ 2350644990 PwrDownCmd 8124;
BA_ "SigType" SG_ 2350644990 HVBusConnectCmd 5;
BA_ "SPN" SG_ 2350644990 HVBusConnectCmd 8123;
BA_ "SigType" SG_ 2566658558 TotalHaulCycleCount 1;
BA_ "SPN" SG_ 2566658558 TotalHaulCycleCount 7700;
BA_ "SigType" SG_ 2566658558 TotalDeliveredPayloadWeight 1;
BA_ "SPN" SG_ 2566658558 TotalDeliveredPayloadWeight 7699;
BA_ "SigType" SG_ 2566658302 TotalPayloadTransactionCount 1;
BA_ "SPN" SG_ 2566658302 TotalPayloadTransactionCount 7701;
BA_ "SigType" SG_ 2499549182 Vour 1;
BA_ "GenSigStartValue" SG_ 2499549182 Vour 7456;
BA_ "SPN" SG_ 2499549182 Vour 7706;
BA_ "SigType" SG_ 2499549182 Three 1;
BA_ "GenSigStartValue" SG_ 2499549182 Three 7456;
BA_ "SPN" SG_ 2499549182 Three 7705;
BA_ "SigType" SG_ 2499549182 Two 1;
BA_ "GenSigStartValue" SG_ 2499549182 Two 7456;
BA_ "SPN" SG_ 2499549182 Two 7704;
BA_ "SigType" SG_ 2499549182 PayloadTemp1 1;
BA_ "GenSigStartValue" SG_ 2499549182 PayloadTemp1 7456;
BA_ "SPN" SG_ 2499549182 PayloadTemp1 7703;
BA_ "SigType" SG_ 2499548926 Five 1;
BA_ "GenSigStartValue" SG_ 2499548926 Five 7456;
BA_ "SPN" SG_ 2499548926 Five 7707;
BA_ "SigType" SG_ 2499548670 SLIBat4NetCur 1;
BA_ "SPN" SG_ 2499548670 SLIBat4NetCur 7715;
BA_ "SigType" SG_ 2499548670 SLIBat3NetCur 1;
BA_ "SPN" SG_ 2499548670 SLIBat3NetCur 7714;
BA_ "SigType" SG_ 2499548670 BatPotential_PwrInput4 1;
BA_ "SPN" SG_ 2499548670 BatPotential_PwrInput4 7713;
BA_ "SigType" SG_ 2499548670 BatPotential_PwrInput3 1;
BA_ "SPN" SG_ 2499548670 BatPotential_PwrInput3 7712;
BA_ "SPN" SG_ 2499548158 RightRearCabDoorLatchPos 7726;
BA_ "SPN" SG_ 2499548158 LeftRearCabDoorLatchPos 7725;
BA_ "SPN" SG_ 2499548158 RightFrontCabDoorLatchPos 7724;
BA_ "SPN" SG_ 2499548158 LeftFrontCabDoorLatchPos 7723;
BA_ "SigType" SG_ 2499547902 MirrorAutoPanningEnable 5;
BA_ "SPN" SG_ 2499547902 MirrorAutoPanningEnable 12318;
BA_ "SigType" SG_ 2499547902 MirrorFoldingSw 5;
BA_ "SPN" SG_ 2499547902 MirrorFoldingSw 12317;
BA_ "SigType" SG_ 2499547902 MirrorRight2HeatCmd 5;
BA_ "SPN" SG_ 2499547902 MirrorRight2HeatCmd 7744;
BA_ "SigType" SG_ 2499547902 MirrorLeft2HeatCmd 5;
BA_ "SPN" SG_ 2499547902 MirrorLeft2HeatCmd 7743;
BA_ "SigType" SG_ 2499547902 MirrorRight1HeatCmd 5;
BA_ "SPN" SG_ 2499547902 MirrorRight1HeatCmd 7742;
BA_ "SigType" SG_ 2499547902 MirrorLeft1HeatCmd 5;
BA_ "SPN" SG_ 2499547902 MirrorLeft1HeatCmd 7741;
BA_ "SigType" SG_ 2499547902 MirrorRight2VerticalCmd 5;
BA_ "SPN" SG_ 2499547902 MirrorRight2VerticalCmd 7740;
BA_ "SigType" SG_ 2499547902 MirrorRight2HorizontalCmd 5;
BA_ "SPN" SG_ 2499547902 MirrorRight2HorizontalCmd 7739;
BA_ "SigType" SG_ 2499547902 MirrorLeft2VerticalCmd 5;
BA_ "SPN" SG_ 2499547902 MirrorLeft2VerticalCmd 7738;
BA_ "SigType" SG_ 2499547902 MirrorLeft2HorizontalCmd 5;
BA_ "SPN" SG_ 2499547902 MirrorLeft2HorizontalCmd 7737;
BA_ "SigType" SG_ 2499547902 MirrorRight1VerticalCmd 5;
BA_ "SPN" SG_ 2499547902 MirrorRight1VerticalCmd 7736;
BA_ "SigType" SG_ 2499547902 MirrorRight1HorizontalCmd 5;
BA_ "SPN" SG_ 2499547902 MirrorRight1HorizontalCmd 7735;
BA_ "SigType" SG_ 2499547902 MirrorLeft1VerticalCmd 5;
BA_ "SPN" SG_ 2499547902 MirrorLeft1VerticalCmd 7734;
BA_ "SigType" SG_ 2499547902 MirrorLeft1HorizontalCmd 5;
BA_ "SPN" SG_ 2499547902 MirrorLeft1HorizontalCmd 7733;
BA_ "SPN" SG_ 2499547902 RightRearWindowPosCmd 7732;
BA_ "SPN" SG_ 2499547902 LeftRearWindowPosCmd 7731;
BA_ "SPN" SG_ 2499547902 RightFrontWindowPosCmd 7730;
BA_ "SPN" SG_ 2499547902 LeftFrontWindowPosCmd 7729;
BA_ "SPN" SG_ 2499547902 RemoteCabDoorLockReq 7728;
BA_ "SPN" SG_ 2499547902 DoorsLockActCmd 7727;
BA_ "SigType" SG_ 2566656510 EngTotalGasIdleFuelVolumeUsed 1;
BA_ "SPN" SG_ 2566656510 EngTotalGasIdleFuelVolumeUsed 7456;
BA_ "SigType" SG_ 2566656510 EngTotalGasFuelVolumeUsed 1;
BA_ "SPN" SG_ 2566656510 EngTotalGasFuelVolumeUsed 7455;
BA_ "SigType" SG_ 2431710718 Checksum 12;
BA_ "SPN" SG_ 2431710718 Checksum 7758;
BA_ "SigType" SG_ 2431710718 MessageCounter 11;
BA_ "SPN" SG_ 2431710718 MessageCounter 7757;
BA_ "SigType" SG_ 2431710718 AutomaticEngStartConsentSummary 5;
BA_ "SPN" SG_ 2431710718 AutomaticEngStartConsentSummary 7756;
BA_ "SigType" SG_ 2431710718 OpEngStartConsentSummary 5;
BA_ "SPN" SG_ 2431710718 OpEngStartConsentSummary 7755;
BA_ "SPN" SG_ 2431710718 ReqLatchStatus 7754;
BA_ "SPN" SG_ 2431710718 StarterCmd 7753;
BA_ "SigType" SG_ 2431710718 CtrlMessageRate 5;
BA_ "SPN" SG_ 2431710718 CtrlMessageRate 7752;
BA_ "SPN" SG_ 2431708670 TransShiftSelectorReqVehDir 7788;
BA_ "SigType" SG_ 2431708670 Checksum 12;
BA_ "SPN" SG_ 2431708670 Checksum 7751;
BA_ "SigType" SG_ 2431708670 MessageCounter 11;
BA_ "SPN" SG_ 2431708670 MessageCounter 7750;
BA_ "SPN" SG_ 2431708670 Starter2Feedback 7749;
BA_ "SPN" SG_ 2431708670 Starter1Feedback 7748;
BA_ "SigType" SG_ 2431708670 AbortReq 5;
BA_ "SPN" SG_ 2431708670 AbortReq 7747;
BA_ "SPN" SG_ 2431708670 Consent 7746;
BA_ "SigType" SG_ 2431708670 Req 5;
BA_ "SPN" SG_ 2431708670 Req 7745;
BA_ "SigType" SG_ 2566661118 EngTotalDieselFuelDemand 1;
BA_ "SPN" SG_ 2566661118 EngTotalDieselFuelDemand 7597;
BA_ "SigType" SG_ 2633769726 ExhFlowRate 1;
BA_ "SPN" SG_ 2633769726 ExhFlowRate 7852;
BA_ "SigType" SG_ 2633769726 TotalEngEnergy 1;
BA_ "SPN" SG_ 2633769726 TotalEngEnergy 7608;
BA_ "SPN" SG_ 2565926142 O2Snsr2PreliminaryFMI 7692;
BA_ "SPN" SG_ 2565926142 NOxSnsr2SelfDiagSt 7691;
BA_ "SPN" SG_ 2565926142 NOxSnsr2PreliminaryFMI 7690;
BA_ "SigType" SG_ 2565926142 Snsr2HtrCtrl 5;
BA_ "SPN" SG_ 2565926142 Snsr2HtrCtrl 7689;
BA_ "SPN" SG_ 2565926142 Snsr2HtrPreliminaryFMI 7688;
BA_ "SigType" SG_ 2565926142 WRPercentO22ReadingStable 5;
BA_ "SPN" SG_ 2565926142 WRPercentO22ReadingStable 7687;
BA_ "SigType" SG_ 2565926142 NOx2ReadingStable 5;
BA_ "SPN" SG_ 2565926142 NOx2ReadingStable 7686;
BA_ "SigType" SG_ 2565926142 Snsr2AtTemp 5;
BA_ "SPN" SG_ 2565926142 Snsr2AtTemp 7685;
BA_ "SigType" SG_ 2565926142 Snsr2PwrInRange 5;
BA_ "SPN" SG_ 2565926142 Snsr2PwrInRange 7684;
BA_ "SigType" SG_ 2565926142 PercentO22 1;
BA_ "SPN" SG_ 2565926142 PercentO22 7683;
BA_ "SigType" SG_ 2565926142 NOx2 1;
BA_ "SPN" SG_ 2565926142 NOx2 7682;
BA_ "SPN" SG_ 2565925886 O2Snsr2PreliminaryFMI 7681;
BA_ "SPN" SG_ 2565925886 NOxSnsr2SelfDiagStatus 7680;
BA_ "SPN" SG_ 2565925886 SCRInNOxSnsr2PreliminaryFMI 7679;
BA_ "SigType" SG_ 2565925886 HtrCtrl 5;
BA_ "SPN" SG_ 2565925886 HtrCtrl 7678;
BA_ "SPN" SG_ 2565925886 HtrPreliminaryFMI 7677;
BA_ "SigType" SG_ 2565925886 WRPercentO22ReadingStable 5;
BA_ "SPN" SG_ 2565925886 WRPercentO22ReadingStable 7676;
BA_ "SigType" SG_ 2565925886 SCRInNOx2ReadingStable 5;
BA_ "SPN" SG_ 2565925886 SCRInNOx2ReadingStable 7675;
BA_ "SigType" SG_ 2565925886 AtTemp 5;
BA_ "SPN" SG_ 2565925886 AtTemp 7674;
BA_ "SigType" SG_ 2565925886 PwrInRange 5;
BA_ "SPN" SG_ 2565925886 PwrInRange 7673;
BA_ "SigType" SG_ 2565925886 PercentO22 1;
BA_ "SPN" SG_ 2565925886 PercentO22 7672;
BA_ "SigType" SG_ 2565925886 SCRInNOx2 1;
BA_ "SPN" SG_ 2565925886 SCRInNOx2 7671;
BA_ "SPN" SG_ 2565925630 O2Snsr2PreliminaryFMI 7670;
BA_ "SPN" SG_ 2565925630 NOxSnsr2SelfDiagSt 7669;
BA_ "SPN" SG_ 2565925630 NOxSnsr2PreliminaryFMI 7668;
BA_ "SigType" SG_ 2565925630 Snsr2HtrCtrl 5;
BA_ "SPN" SG_ 2565925630 Snsr2HtrCtrl 7667;
BA_ "SPN" SG_ 2565925630 Snsr2HtrPreliminaryFMI 7666;
BA_ "SigType" SG_ 2565925630 WRPercentO22ReadingStable 5;
BA_ "SPN" SG_ 2565925630 WRPercentO22ReadingStable 7665;
BA_ "SigType" SG_ 2565925630 NOx2ReadingStable 5;
BA_ "SPN" SG_ 2565925630 NOx2ReadingStable 7664;
BA_ "SigType" SG_ 2565925630 Snsr2AtTemp 5;
BA_ "SPN" SG_ 2565925630 Snsr2AtTemp 7663;
BA_ "SigType" SG_ 2565925630 Snsr2PwrInRange 5;
BA_ "SPN" SG_ 2565925630 Snsr2PwrInRange 7662;
BA_ "SigType" SG_ 2565925630 PercentO22 1;
BA_ "SPN" SG_ 2565925630 PercentO22 7661;
BA_ "SigType" SG_ 2565925630 NOx2 1;
BA_ "SPN" SG_ 2565925630 NOx2 7660;
BA_ "SPN" SG_ 2565925374 O2Snsr2PreliminaryFMI 7659;
BA_ "SPN" SG_ 2565925374 NOxSnsr2SelfDiagStatus 7658;
BA_ "SPN" SG_ 2565925374 SCRInNOxSnsr2PreliminaryFMI 7657;
BA_ "SigType" SG_ 2565925374 Snsr2HtrCtrl 5;
BA_ "SPN" SG_ 2565925374 Snsr2HtrCtrl 7656;
BA_ "SPN" SG_ 2565925374 Snsr2HtrPreliminaryFMI 7655;
BA_ "SigType" SG_ 2565925374 WRPercentO22ReadingStable 5;
BA_ "SPN" SG_ 2565925374 WRPercentO22ReadingStable 7654;
BA_ "SigType" SG_ 2565925374 SCRInNOx2ReadingStable 5;
BA_ "SPN" SG_ 2565925374 SCRInNOx2ReadingStable 7653;
BA_ "SigType" SG_ 2565925374 Snsr2AtTemp 5;
BA_ "SPN" SG_ 2565925374 Snsr2AtTemp 7652;
BA_ "SigType" SG_ 2565925374 Snsr2PwrInRange 5;
BA_ "SPN" SG_ 2565925374 Snsr2PwrInRange 7651;
BA_ "SigType" SG_ 2565925374 PercentO22 1;
BA_ "SPN" SG_ 2565925374 PercentO22 7650;
BA_ "SigType" SG_ 2565925374 SCRInNOx2 1;
BA_ "SPN" SG_ 2565925374 SCRInNOx2 7649;
BA_ "SigType" SG_ 2364598526 FuelAct2MotorCurDis 5;
BA_ "SPN" SG_ 2364598526 FuelAct2MotorCurDis 21165;
BA_ "SigType" SG_ 2364598526 FuelAct1MotorCurDis 5;
BA_ "SPN" SG_ 2364598526 FuelAct1MotorCurDis 21164;
BA_ "SigType" SG_ 2364598526 FuelAct4CtrlCmd 1;
BA_ "SPN" SG_ 2364598526 FuelAct4CtrlCmd 7594;
BA_ "SigType" SG_ 2364598526 FuelAct3CtrlCmd 1;
BA_ "SPN" SG_ 2364598526 FuelAct3CtrlCmd 7593;
BA_ "SPN" SG_ 2565900286 DeratingReason 22727;
BA_ "SigType" SG_ 2565900286 PresentChargingCur 1;
BA_ "SPN" SG_ 2565900286 PresentChargingCur 22726;
BA_ "SigType" SG_ 2565900286 PresentChargingV 1;
BA_ "SPN" SG_ 2565900286 PresentChargingV 22725;
BA_ "SPN" SG_ 2565900286 St 22724;
BA_ "SigType" SG_ 2558525182 Num7586 8;
BA_ "SPN" SG_ 2558525182 Num7586 7586;
BA_ "SPN" SG_ 2558525182 Location 7585;
BA_ "SigType" SG_ 2558525182 Num 1;
BA_ "SPN" SG_ 2558525182 Num 7584;
BA_ "SigType" SG_ 2558525182 NumOfTireSensors 1;
BA_ "SPN" SG_ 2558525182 NumOfTireSensors 7583;
BA_ "SigType" SG_ 2350841598 TrqRampMaxSpdCmd 1;
BA_ "SPN" SG_ 2350841598 TrqRampMaxSpdCmd 7592;
BA_ "SigType" SG_ 2350841598 TrqRampTimeCmd 1;
BA_ "GenSigStartValue" SG_ 2350841598 TrqRampTimeCmd 1;
BA_ "SPN" SG_ 2350841598 TrqRampTimeCmd 7591;
BA_ "SigType" SG_ 2350841598 ExcitationMaxCurrentLmt 1;
BA_ "SPN" SG_ 2350841598 ExcitationMaxCurrentLmt 7590;
BA_ "SigType" SG_ 2350841598 SetpointVoltageCmd 1;
BA_ "SPN" SG_ 2350841598 SetpointVoltageCmd 7589;
BA_ "SigType" SG_ 2566838014 HSI1CRC 12;
BA_ "SPN" SG_ 2566838014 HSI1CRC 22272;
BA_ "SigType" SG_ 2566838014 HSI1Counter 11;
BA_ "SPN" SG_ 2566838014 HSI1Counter 22271;
BA_ "SigType" SG_ 2566838014 HSI1EmbeddedIntegritySupport 5;
BA_ "SPN" SG_ 2566838014 HSI1EmbeddedIntegritySupport 22270;
BA_ "SigType" SG_ 2566838014 HVESSThermalMnmgtMaintenanceSw 4;
BA_ "SPN" SG_ 2566838014 HVESSThermalMnmgtMaintenanceSw 20877;
BA_ "SigType" SG_ 2566838014 PropulsionMotorCoolantFillSw 4;
BA_ "SPN" SG_ 2566838014 PropulsionMotorCoolantFillSw 8476;
BA_ "SigType" SG_ 2566838014 PwrECoolantFillSw 4;
BA_ "SPN" SG_ 2566838014 PwrECoolantFillSw 8475;
BA_ "SigType" SG_ 2566838014 ShutdownSw 4;
BA_ "SPN" SG_ 2566838014 ShutdownSw 7555;
BA_ "SigType" SG_ 2566838014 PropulsionDisableSw 4;
BA_ "SPN" SG_ 2566838014 PropulsionDisableSw 7554;
BA_ "SigType" SG_ 2566838014 HybrdSystmCstngRgnrtvBrkngLvlSlc 1;
BA_ "SPN" SG_ 2566838014 HybrdSystmCstngRgnrtvBrkngLvlSlc 7556;
BA_ "SigType" SG_ 2566838014 HybrdSystmBrkPdlRgnrtvBrkngDsblS 4;
BA_ "SPN" SG_ 2566838014 HybrdSystmBrkPdlRgnrtvBrkngDsblS 7553;
BA_ "SigType" SG_ 2566838014 HybrdSystmRgnrtvBrkngDsbleSwitch 4;
BA_ "SPN" SG_ 2566838014 HybrdSystmRgnrtvBrkngDsbleSwitch 7552;
BA_ "SigType" SG_ 2566838014 HybrdSystmOffBrdChrgrCnnctnSttus 4;
BA_ "SPN" SG_ 2566838014 HybrdSystmOffBrdChrgrCnnctnSttus 7551;
BA_ "SigType" SG_ 2566838014 HybrdSystmPwrElctrncsClntLvlSwtc 4;
BA_ "SPN" SG_ 2566838014 HybrdSystmPwrElctrncsClntLvlSwtc 7550;
BA_ "SigType" SG_ 2566838014 HybrdSystmPrplsnClantLevelSwitch 4;
BA_ "SPN" SG_ 2566838014 HybrdSystmPrplsnClantLevelSwitch 7549;
BA_ "SigType" SG_ 2566838014 HybrdSystmPrtctionOverrideSwitch 4;
BA_ "SPN" SG_ 2566838014 HybrdSystmPrtctionOverrideSwitch 7548;
BA_ "SigType" SG_ 2566761726 EngIdleFuelFlowRateThreshold 1;
BA_ "SPN" SG_ 2566761726 EngIdleFuelFlowRateThreshold 2778;
BA_ "SigType" SG_ 2566761726 NmbrOfFlCnsmptnMntrngTransducers 1;
BA_ "SPN" SG_ 2566761726 NmbrOfFlCnsmptnMntrngTransducers 2777;
BA_ "SigType" SG_ 2566756350 EngFuelReturnTemp 1;
BA_ "SPN" SG_ 2566756350 EngFuelReturnTemp 2776;
BA_ "SigType" SG_ 2566756350 EngFuelSupplyTemp 1;
BA_ "SPN" SG_ 2566756350 EngFuelSupplyTemp 2775;
BA_ "SigType" SG_ 2566756094 EngFuelReturnFlowRate 1;
BA_ "SPN" SG_ 2566756094 EngFuelReturnFlowRate 2774;
BA_ "SigType" SG_ 2566756094 EngFuelSupplyFlowRate 1;
BA_ "SPN" SG_ 2566756094 EngFuelSupplyFlowRate 2773;
BA_ "SigType" SG_ 2566687998 TimeBetweenRegens 1;
BA_ "SPN" SG_ 2566687998 TimeBetweenRegens 6776;
BA_ "SigType" SG_ 2566687998 ActiveAccumulationTime 1;
BA_ "SPN" SG_ 2566687998 ActiveAccumulationTime 6775;
BA_ "SPN" SG_ 2566687998 RegenSt6774 6774;
BA_ "SigType" SG_ 2566687998 RegenSt 5;
BA_ "SPN" SG_ 2566687998 RegenSt 6773;
BA_ "SigType" SG_ 2566687998 HtrSt 5;
BA_ "SPN" SG_ 2566687998 HtrSt 6772;
BA_ "SigType" SG_ 2566687998 Res 1;
BA_ "SPN" SG_ 2566687998 Res 6771;
BA_ "SigType" SG_ 2566687742 HtrRes 1;
BA_ "SPN" SG_ 2566687742 HtrRes 7070;
BA_ "SigType" SG_ 2566687742 MaxRes 1;
BA_ "SPN" SG_ 2566687742 MaxRes 6781;
BA_ "SigType" SG_ 2566687742 Temp 1;
BA_ "SPN" SG_ 2566687742 Temp 6780;
BA_ "SigType" SG_ 2566687742 RegenFailedCount 1;
BA_ "SPN" SG_ 2566687742 RegenFailedCount 6779;
BA_ "SigType" SG_ 2566687742 PwrSupply 4;
BA_ "SPN" SG_ 2566687742 PwrSupply 6778;
BA_ "SPN" SG_ 2566687742 DetectionSt 6777;
BA_ "SigType" SG_ 2365348350 ShareActiveCirc 5;
BA_ "SPN" SG_ 2365348350 ShareActiveCirc 6718;
BA_ "SPN" SG_ 2365348350 EngLoadShareStatus 6794;
BA_ "SigType" SG_ 2365348350 EngUnloadStatus 4;
BA_ "SPN" SG_ 2365348350 EngUnloadStatus 6793;
BA_ "SigType" SG_ 2566674686 EngTC2OilTemp 1;
BA_ "SPN" SG_ 2566674686 EngTC2OilTemp 8850;
BA_ "SigType" SG_ 2566674686 EngTurbo4LubeOilPress 1;
BA_ "SPN" SG_ 2566674686 EngTurbo4LubeOilPress 6813;
BA_ "SigType" SG_ 2566674686 EngTurbo3LubeOilPress 1;
BA_ "SPN" SG_ 2566674686 EngTurbo3LubeOilPress 6812;
BA_ "SigType" SG_ 2566674686 EngTurbo2LubeOilPress 1;
BA_ "SPN" SG_ 2566674686 EngTurbo2LubeOilPress 6811;
BA_ "SigType" SG_ 2566674430 DslExhstFldQalityMalfunctionTime 1;
BA_ "SPN" SG_ 2566674430 DslExhstFldQalityMalfunctionTime 6818;
BA_ "SigType" SG_ 2566674430 DieselExhaustFluidTank1EmptyTime 1;
BA_ "SPN" SG_ 2566674430 DieselExhaustFluidTank1EmptyTime 6817;
BA_ "SigType" SG_ 2566674174 SCROperatorInducementTotalTime 1;
BA_ "SPN" SG_ 2566674174 SCROperatorInducementTotalTime 7095;
BA_ "SigType" SG_ 2566674174 AFTSCRMalfunctionTime 1;
BA_ "SPN" SG_ 2566674174 AFTSCRMalfunctionTime 6819;
BA_ "SigType" SG_ 2566673406 GasLeakageDetection3Press 1;
BA_ "SPN" SG_ 2566673406 GasLeakageDetection3Press 6839;
BA_ "SigType" SG_ 2566673406 GasLeakageDetection2Press 1;
BA_ "SPN" SG_ 2566673406 GasLeakageDetection2Press 6838;
BA_ "SigType" SG_ 2566673406 GasLeakageDetection1Press 1;
BA_ "SPN" SG_ 2566673406 GasLeakageDetection1Press 6837;
BA_ "SigType" SG_ 2566673406 GasFuelLeakage3Concentration 1;
BA_ "SPN" SG_ 2566673406 GasFuelLeakage3Concentration 6836;
BA_ "SigType" SG_ 2566673406 GasFuelLeakage2Concentration 1;
BA_ "SPN" SG_ 2566673406 GasFuelLeakage2Concentration 6835;
BA_ "SigType" SG_ 2566673406 GasFuelLeakage1Concentration 1;
BA_ "SPN" SG_ 2566673406 GasFuelLeakage1Concentration 6834;
BA_ "SigType" SG_ 2633782014 NetBinWeight 1;
BA_ "SPN" SG_ 2633782014 NetBinWeight 6841;
BA_ "SigType" SG_ 2633782014 BinLiftCount 1;
BA_ "SPN" SG_ 2633782014 BinLiftCount 6840;
BA_ "SPN" SG_ 2633782014 BinWeighingErrorStatus 6842;
BA_ "SPN" SG_ 2633782014 BinInstance 6845;
BA_ "SPN" SG_ 2365346302 LiftAxle4Status 12299;
BA_ "SPN" SG_ 2365346302 LiftAxle3Status 12298;
BA_ "SPN" SG_ 2365346302 LiftAxle2Status 6844;
BA_ "SPN" SG_ 2365346302 LiftAxle1Status 6843;
BA_ "SPN" SG_ 2566672638 DeliveryTransactionStatus 7702;
BA_ "SigType" SG_ 2566672638 DeliveredPayloadConfidence 1;
BA_ "SPN" SG_ 2566672638 DeliveredPayloadConfidence 6850;
BA_ "SPN" SG_ 2566672638 DeliveredPayloadWeight 6849;
BA_ "SPN" SG_ 2566672638 HaulModeStatus 6848;
BA_ "SigType" SG_ 2566672638 HaulCycleCount 1;
BA_ "SPN" SG_ 2566672638 HaulCycleCount 6847;
BA_ "SigType" SG_ 2566672382 PayloadWeightSensor8Status 5;
BA_ "SPN" SG_ 2566672382 PayloadWeightSensor8Status 6862;
BA_ "SigType" SG_ 2566672382 PayloadWeightSensor7Status 5;
BA_ "SPN" SG_ 2566672382 PayloadWeightSensor7Status 6861;
BA_ "SigType" SG_ 2566672382 PayloadWeightSensor6Status 5;
BA_ "SPN" SG_ 2566672382 PayloadWeightSensor6Status 6860;
BA_ "SigType" SG_ 2566672382 PayloadWeightSensor5Status 5;
BA_ "SPN" SG_ 2566672382 PayloadWeightSensor5Status 6859;
BA_ "SigType" SG_ 2566672382 PayloadWeightSensor4Status 5;
BA_ "SPN" SG_ 2566672382 PayloadWeightSensor4Status 6858;
BA_ "SigType" SG_ 2566672382 PayloadWeightSensor3Status 5;
BA_ "SPN" SG_ 2566672382 PayloadWeightSensor3Status 6857;
BA_ "SigType" SG_ 2566672382 PayloadWeightSensor2Status 5;
BA_ "SPN" SG_ 2566672382 PayloadWeightSensor2Status 6856;
BA_ "SigType" SG_ 2566672382 PayloadWeightSensor1Status 5;
BA_ "SPN" SG_ 2566672382 PayloadWeightSensor1Status 6855;
BA_ "SigType" SG_ 2566672126 DEFDoser1Press20906 1;
BA_ "SPN" SG_ 2566672126 DEFDoser1Press20906 20906;
BA_ "SigType" SG_ 2566672126 DEFDoser2Press 1;
BA_ "SPN" SG_ 2566672126 DEFDoser2Press 8152;
BA_ "SigType" SG_ 2566672126 DEFDoser2Temp 1;
BA_ "SPN" SG_ 2566672126 DEFDoser2Temp 7460;
BA_ "SigType" SG_ 2566672126 DEFDoser2AbsPress 1;
BA_ "SPN" SG_ 2566672126 DEFDoser2AbsPress 7459;
BA_ "SigType" SG_ 2566672126 DEFDoser1Press 1;
BA_ "SPN" SG_ 2566672126 DEFDoser1Press 6875;
BA_ "SigType" SG_ 2566671870 DEFDoser1Press20909 1;
BA_ "SPN" SG_ 2566671870 DEFDoser1Press20909 20909;
BA_ "SigType" SG_ 2566671870 DEFDoser2Press 1;
BA_ "SPN" SG_ 2566671870 DEFDoser2Press 8153;
BA_ "SigType" SG_ 2566671870 DEFDoser2Temp 1;
BA_ "SPN" SG_ 2566671870 DEFDoser2Temp 7465;
BA_ "SigType" SG_ 2566671870 DEFDoser2AbsPress 1;
BA_ "SPN" SG_ 2566671870 DEFDoser2AbsPress 7464;
BA_ "SigType" SG_ 2566671870 DEFDoser1Press 1;
BA_ "SPN" SG_ 2566671870 DEFDoser1Press 6876;
BA_ "SigType" SG_ 2566671614 TtlNmbrOfSCROprtrIndcmntOvrrdEvn 1;
BA_ "SPN" SG_ 2566671614 TtlNmbrOfSCROprtrIndcmntOvrrdEvn 6880;
BA_ "SigType" SG_ 2566671614 NmbrOfSCROprtrIndcmntOvrrdEvntsR 1;
BA_ "SPN" SG_ 2566671614 NmbrOfSCROprtrIndcmntOvrrdEvntsR 6879;
BA_ "SigType" SG_ 2566671614 SCROprtrIndcmntOvrrdTmeRemaining 1;
BA_ "SPN" SG_ 2566671614 SCROprtrIndcmntOvrrdTmeRemaining 6878;
BA_ "SigType" SG_ 2566671614 SCROprtrInducementOverrideEnable 5;
BA_ "SPN" SG_ 2566671614 SCROprtrInducementOverrideEnable 6877;
BA_ "SigType" SG_ 2566671358 CylFuelRate 1;
BA_ "SPN" SG_ 2566671358 CylFuelRate 7333;
BA_ "SigType" SG_ 2566671358 EngExhaustFlowRate 1;
BA_ "SPN" SG_ 2566671358 EngExhaustFlowRate 6895;
BA_ "SigType" SG_ 2566671358 VehicleFuelRate 1;
BA_ "SPN" SG_ 2566671358 VehicleFuelRate 6894;
BA_ "SigType" SG_ 2566671358 PEMSEngFuelMassFlowRate 1;
BA_ "SPN" SG_ 2566671358 PEMSEngFuelMassFlowRate 6893;
BA_ "SigType" SG_ 2566671102 AFT1CondNotMetForActiveClean 5;
BA_ "SPN" SG_ 2566671102 AFT1CondNotMetForActiveClean 7848;
BA_ "SPN" SG_ 2566671102 SCRSystemCleaningForcedStatus 6934;
BA_ "SigType" SG_ 2566671102 SCRSystmClnngAtmtcIntationConfig 5;
BA_ "SPN" SG_ 2566671102 SCRSystmClnngAtmtcIntationConfig 6933;
BA_ "SigType" SG_ 2566671102 SCRSystmClnngInhbtdDTVhclSpdBlwA 5;
BA_ "SPN" SG_ 2566671102 SCRSystmClnngInhbtdDTVhclSpdBlwA 6932;
BA_ "SigType" SG_ 2566671102 SCRSystmClnngInhbtdDTEngNtWrmdUp 5;
BA_ "SPN" SG_ 2566671102 SCRSystmClnngInhbtdDTEngNtWrmdUp 6931;
BA_ "SigType" SG_ 2566671102 SCRSystmClnngInhbtdDTPrmnntSystm 5;
BA_ "SPN" SG_ 2566671102 SCRSystmClnngInhbtdDTPrmnntSystm 6930;
BA_ "SigType" SG_ 2566671102 SCRSystmClnngInhbtdDTTmprrySystm 5;
BA_ "SPN" SG_ 2566671102 SCRSystmClnngInhbtdDTTmprrySystm 6929;
BA_ "SigType" SG_ 2566671102 SCRSystmClnngInhbtdDTSystmTmeout 5;
BA_ "SPN" SG_ 2566671102 SCRSystmClnngInhbtdDTSystmTmeout 6928;
BA_ "SigType" SG_ 2566671102 SCRSystmClnngInhbtdDTSystmFltAct 5;
BA_ "SPN" SG_ 2566671102 SCRSystmClnngInhbtdDTSystmFltAct 6927;
BA_ "SigType" SG_ 2566671102 SCRSystmClnngInhbtdDTLwExhstTemp 5;
BA_ "SPN" SG_ 2566671102 SCRSystmClnngInhbtdDTLwExhstTemp 6926;
BA_ "SigType" SG_ 2566671102 SCRSystmClnngInhbtdDTPrkngBrkNtS 5;
BA_ "SPN" SG_ 2566671102 SCRSystmClnngInhbtdDTPrkngBrkNtS 6925;
BA_ "SigType" SG_ 2566671102 SCRSystmClnngInhbtdDTVhclSpdAbvA 5;
BA_ "SPN" SG_ 2566671102 SCRSystmClnngInhbtdDTVhclSpdAbvA 6924;
BA_ "SigType" SG_ 2566671102 SCRSystmClnngInhbtdDTOtOfNeutral 5;
BA_ "SPN" SG_ 2566671102 SCRSystmClnngInhbtdDTOtOfNeutral 6923;
BA_ "SigType" SG_ 2566671102 SCRSystmClnngInhbtdDTAcclPdlOffI 5;
BA_ "SPN" SG_ 2566671102 SCRSystmClnngInhbtdDTAcclPdlOffI 6922;
BA_ "SigType" SG_ 2566671102 SCRSystmClnngInhbtdDeToPTOActive 5;
BA_ "SPN" SG_ 2566671102 SCRSystmClnngInhbtdDeToPTOActive 6921;
BA_ "SigType" SG_ 2566671102 SCRSystmClnngInhbtdDTSrvcBrkActv 5;
BA_ "SPN" SG_ 2566671102 SCRSystmClnngInhbtdDTSrvcBrkActv 6920;
BA_ "SigType" SG_ 2566671102 SCRSystmClnngInhbtdDTCltchDsnggd 5;
BA_ "SPN" SG_ 2566671102 SCRSystmClnngInhbtdDTCltchDsnggd 6919;
BA_ "SigType" SG_ 2566671102 SCRSystmClnngInhbtdDTInhbtSwitch 5;
BA_ "SPN" SG_ 2566671102 SCRSystmClnngInhbtdDTInhbtSwitch 6918;
BA_ "SigType" SG_ 2566671102 SCRSystemCleaningInhibitedStatus 5;
BA_ "SPN" SG_ 2566671102 SCRSystemCleaningInhibitedStatus 6917;
BA_ "SigType" SG_ 2566671102 SCRSystemCleaningStatus 5;
BA_ "SPN" SG_ 2566671102 SCRSystemCleaningStatus 6916;
BA_ "SPN" SG_ 2566671102 SCRSystemCleaningLampCmd 6915;
BA_ "SigType" SG_ 2566670846 TotalAFTOperatingHours 1;
BA_ "SPN" SG_ 2566670846 TotalAFTOperatingHours 8629;
BA_ "SigType" SG_ 2566670846 SCRSysAvgDistBetweenCleanEvents 1;
BA_ "SPN" SG_ 2566670846 SCRSysAvgDistBetweenCleanEvents 6940;
BA_ "SigType" SG_ 2566670846 SCRSysAvgTimeBetweenCleanEvents 1;
BA_ "SPN" SG_ 2566670846 SCRSysAvgTimeBetweenCleanEvents 6939;
BA_ "SigType" SG_ 2566670846 SCRSysTotalSysCleanManReq 1;
BA_ "SPN" SG_ 2566670846 SCRSysTotalSysCleanManReq 6938;
BA_ "SigType" SG_ 2566670846 SCRSysTotalSysCleanInhReq 1;
BA_ "SPN" SG_ 2566670846 SCRSysTotalSysCleanInhReq 6937;
BA_ "SigType" SG_ 2566670846 SCRSysTotalSysCleanEvents 1;
BA_ "SPN" SG_ 2566670846 SCRSysTotalSysCleanEvents 6936;
BA_ "SigType" SG_ 2566670846 SCRSysTotalCleanTime 1;
BA_ "SPN" SG_ 2566670846 SCRSysTotalCleanTime 6935;
BA_ "SigType" SG_ 2566670590 SCRSysAvgDistBetweenCleanEvents 1;
BA_ "SPN" SG_ 2566670590 SCRSysAvgDistBetweenCleanEvents 6947;
BA_ "SigType" SG_ 2566670590 SCRSysAvgTimeBetweenCleanEvents 1;
BA_ "SPN" SG_ 2566670590 SCRSysAvgTimeBetweenCleanEvents 6946;
BA_ "SigType" SG_ 2566670590 SCRSysTotalSysCleanManReq 1;
BA_ "SPN" SG_ 2566670590 SCRSysTotalSysCleanManReq 6945;
BA_ "SigType" SG_ 2566670590 SCRSysTotalSysCleanInhReq 1;
BA_ "SPN" SG_ 2566670590 SCRSysTotalSysCleanInhReq 6944;
BA_ "SigType" SG_ 2566670590 SCRSysTotalSysCleanEvents 1;
BA_ "SPN" SG_ 2566670590 SCRSysTotalSysCleanEvents 6943;
BA_ "SigType" SG_ 2566670590 SCRSysTotalSysCleanTime 1;
BA_ "SPN" SG_ 2566670590 SCRSysTotalSysCleanTime 6942;
BA_ "SPN" SG_ 2566670334 Axle12MonitoredTireCount 6962;
BA_ "SPN" SG_ 2566670334 Axle11MonitoredTireCount 6961;
BA_ "SPN" SG_ 2566670334 Axle10MonitoredTireCount 6960;
BA_ "SPN" SG_ 2566670334 Axle9MonitoredTireCount 6959;
BA_ "SPN" SG_ 2566670334 Axle8MonitoredTireCount 6958;
BA_ "SPN" SG_ 2566670334 Axle7MonitoredTireCount 6957;
BA_ "SPN" SG_ 2566670334 Axle6MonitoredTireCount 6956;
BA_ "SPN" SG_ 2566670334 Axle5MonitoredTireCount 6955;
BA_ "SPN" SG_ 2566670334 Axle4MonitoredTireCount 6954;
BA_ "SPN" SG_ 2566670334 Axle3MonitoredTireCount 6953;
BA_ "SPN" SG_ 2566670334 Axle2MonitoredTireCount 6952;
BA_ "SPN" SG_ 2566670334 Axle1MonitoredTireCount 6951;
BA_ "SigType" SG_ 2566670334 NumberOfTiresOnTheVehicle 1;
BA_ "SPN" SG_ 2566670334 NumberOfTiresOnTheVehicle 6950;
BA_ "SPN" SG_ 2566670334 NumberOfAxlesOnTheVehicle 6949;
BA_ "SigType" SG_ 2566670078 TireSensorIdentificationNumber 8;
BA_ "SPN" SG_ 2566670078 TireSensorIdentificationNumber 6966;
BA_ "SPN" SG_ 2566670078 TireSensorLocation 6965;
BA_ "SigType" SG_ 2566670078 TireSensorTireNumber 1;
BA_ "SPN" SG_ 2566670078 TireSensorTireNumber 6964;
BA_ "SigType" SG_ 2566670078 NumberOfTireSensors 1;
BA_ "SPN" SG_ 2566670078 NumberOfTireSensors 6963;
BA_ "SigType" SG_ 2566669822 TrWrelessSignalStrengthIndicator 1;
BA_ "SPN" SG_ 2566669822 TrWrelessSignalStrengthIndicator 6972;
BA_ "SPN" SG_ 2566669822 TireLocation 6971;
BA_ "SigType" SG_ 2566669822 TireSensorNumber 1;
BA_ "SPN" SG_ 2566669822 TireSensorNumber 6970;
BA_ "SigType" SG_ 2566669822 TtalNumberOfTireSensorsMonitored 1;
BA_ "SPN" SG_ 2566669822 TtalNumberOfTireSensorsMonitored 6969;
BA_ "SigType" SG_ 2566669822 AntennaNumber 1;
BA_ "SPN" SG_ 2566669822 AntennaNumber 6968;
BA_ "SigType" SG_ 2566669822 TotalNumberOfAntennasUsed 1;
BA_ "SPN" SG_ 2566669822 TotalNumberOfAntennasUsed 6967;
BA_ "SigType" SG_ 2566669310 OverTemp 1;
BA_ "SPN" SG_ 2566669310 OverTemp 6984;
BA_ "SigType" SG_ 2566669310 OverPressPercentageThreshold 1;
BA_ "SPN" SG_ 2566669310 OverPressPercentageThreshold 6983;
BA_ "SigType" SG_ 2566669310 ExtrmUndrPrssPercentageThreshold 1;
BA_ "SPN" SG_ 2566669310 ExtrmUndrPrssPercentageThreshold 6982;
BA_ "SigType" SG_ 2566669310 UnderPressPercentageThreshold 1;
BA_ "SPN" SG_ 2566669310 UnderPressPercentageThreshold 6981;
BA_ "SigType" SG_ 2566669310 ColdInflationPress 1;
BA_ "SPN" SG_ 2566669310 ColdInflationPress 6980;
BA_ "SPN" SG_ 2566669310 TireLocation 6979;
BA_ "SigType" SG_ 2566669054 RequiredTirePress 1;
BA_ "SPN" SG_ 2566669054 RequiredTirePress 6989;
BA_ "SigType" SG_ 2566669054 TirePress 1;
BA_ "SPN" SG_ 2566669054 TirePress 6988;
BA_ "SPN" SG_ 2566669054 TireLocation 6987;
BA_ "SigType" SG_ 2566668798 EngFl2InjctorMeteringRail1Press2 1;
BA_ "SPN" SG_ 2566668798 EngFl2InjctorMeteringRail1Press2 7513;
BA_ "SigType" SG_ 2566668798 EngFel2InjectorMeteringRail2Temp 1;
BA_ "SPN" SG_ 2566668798 EngFel2InjectorMeteringRail2Temp 7024;
BA_ "SigType" SG_ 2566668798 EngFel2InjectorMeteringRail1Temp 1;
BA_ "SPN" SG_ 2566668798 EngFel2InjectorMeteringRail1Temp 7023;
BA_ "SigType" SG_ 2566668798 EngFl2InjectorMeteringRail2Press 1;
BA_ "SPN" SG_ 2566668798 EngFl2InjectorMeteringRail2Press 7022;
BA_ "SigType" SG_ 2566668798 EngFl2InjectorMeteringRail1Press 1;
BA_ "SPN" SG_ 2566668798 EngFl2InjectorMeteringRail1Press 7021;
VAL_ 2558394110 Instance15 1 "No Command applied to this Accessory Motor Instance" 0 "Command applied to this Accessory Motor Instance" ;
VAL_ 2558394110 Instance14 1 "No Command applied to this Accessory Motor Instance" 0 "Command applied to this Accessory Motor Instance" ;
VAL_ 2558394110 Instance13 1 "No Command applied to this Accessory Motor Instance" 0 "Command applied to this Accessory Motor Instance" ;
VAL_ 2558394110 Instance12 1 "No Command applied to this Accessory Motor Instance" 0 "Command applied to this Accessory Motor Instance" ;
VAL_ 2558394110 Instance11 1 "No Command applied to this Accessory Motor Instance" 0 "Command applied to this Accessory Motor Instance" ;
VAL_ 2558394110 Instance10 1 "No Command applied to this Accessory Motor Instance" 0 "Command applied to this Accessory Motor Instance" ;
VAL_ 2558394110 Instance9 1 "No Command applied to this Accessory Motor Instance" 0 "Command applied to this Accessory Motor Instance" ;
VAL_ 2558394110 Instance8 1 "No Command applied to this Accessory Motor Instance" 0 "Command applied to this Accessory Motor Instance" ;
VAL_ 2558394110 Instance7 1 "No Command applied to this Accessory Motor Instance" 0 "Command applied to this Accessory Motor Instance" ;
VAL_ 2558394110 Instance6 1 "No Command applied to this Accessory Motor Instance" 0 "Command applied to this Accessory Motor Instance" ;
VAL_ 2558394110 Instance5 1 "No Command applied to this Accessory Motor Instance" 0 "Command applied to this Accessory Motor Instance" ;
VAL_ 2558394110 Instance4 1 "No Command applied to this Accessory Motor Instance" 0 "Command applied to this Accessory Motor Instance" ;
VAL_ 2558394110 Instance3 1 "No Command applied to this Accessory Motor Instance" 0 "Command applied to this Accessory Motor Instance" ;
VAL_ 2558394110 Instance2 1 "No Command applied to this Accessory Motor Instance" 0 "Command applied to this Accessory Motor Instance" ;
VAL_ 2558394110 Instance1 1 "No Command applied to this Accessory Motor Instance" 0 "Command applied to this Accessory Motor Instance" ;
VAL_ 2558394110 PwrHold 3 "Don't Care/Take no action" 2 "Reserved" 1 "Power Hold Enabled" 0 "Power Hold Disabled" ;
VAL_ 2558394110 EnableCmd 3 "Don't Care/Take no action" 2 "Accessory Motor On Reverse Direction" 1 "Accessory Motor On Normal/Default Direction" 0 "Accessory Motor Off" ;
VAL_ 2558263038 PwrHold 3 "Don't Care/Take no action" 2 "Reserved" 1 "Power Hold Enabled" 0 "Power Hold Disabled" ;
VAL_ 2558263038 EnableCmd 3 "Don't Care/Take no action" 2 "Accessory Motor On Reverse Direction" 1 "Accessory Motor On Normal/Default Direction" 0 "Accessory Motor Off" ;
VAL_ 2558197502 PwrHold 3 "Don't Care/Take no action" 2 "Reserved" 1 "Power Hold Enabled" 0 "Power Hold Disabled" ;
VAL_ 2558197502 EnableCmd 3 "Don't Care/Take no action" 2 "Accessory Motor On Reverse Direction" 1 "Accessory Motor On Normal/Default Direction" 0 "Accessory Motor Off" ;
VAL_ 2558131966 PwrHold 3 "Don't Care/Take no action" 2 "Reserved" 1 "Power Hold Enabled" 0 "Power Hold Disabled" ;
VAL_ 2558131966 EnableCmd 3 "Don't Care/Take no action" 2 "Accessory Motor On Reverse Direction" 1 "Accessory Motor On Normal/Default Direction" 0 "Accessory Motor Off" ;
VAL_ 2558066430 PwrHold 3 "Don't Care/Take no action" 2 "Reserved" 1 "Power Hold Enabled" 0 "Power Hold Disabled" ;
VAL_ 2558066430 EnableCmd 3 "Don't Care/Take no action" 2 "Accessory Motor On Reverse Direction" 1 "Accessory Motor On Normal/Default Direction" 0 "Accessory Motor Off" ;
VAL_ 2558000894 PwrHold 3 "Don't Care/Take no action" 2 "Reserved" 1 "Power Hold Enabled" 0 "Power Hold Disabled" ;
VAL_ 2558000894 EnableCmd 3 "Don't Care/Take no action" 2 "Accessory Motor On Reverse Direction" 1 "Accessory Motor On Normal/Default Direction" 0 "Accessory Motor Off" ;
VAL_ 2557935358 PwrHold 3 "Don't Care/Take no action" 2 "Reserved" 1 "Power Hold Enabled" 0 "Power Hold Disabled" ;
VAL_ 2557935358 EnableCmd 3 "Don't Care/Take no action" 2 "Accessory Motor On Reverse Direction" 1 "Accessory Motor On Normal/Default Direction" 0 "Accessory Motor Off" ;
VAL_ 2557869822 PwrHold 3 "Don't Care/Take no action" 2 "Reserved" 1 "Power Hold Enabled" 0 "Power Hold Disabled" ;
VAL_ 2557869822 EnableCmd 3 "Don't Care/Take no action" 2 "Accessory Motor On Reverse Direction" 1 "Accessory Motor On Normal/Default Direction" 0 "Accessory Motor Off" ;
VAL_ 2557804286 PwrHold 3 "Don't Care/Take no action" 2 "Reserved" 1 "Power Hold Enabled" 0 "Power Hold Disabled" ;
VAL_ 2557804286 EnableCmd 3 "Don't Care/Take no action" 2 "Accessory Motor On Reverse Direction" 1 "Accessory Motor On Normal/Default Direction" 0 "Accessory Motor Off" ;
VAL_ 2557738750 PwrHold 3 "Don't Care/Take no action" 2 "Reserved" 1 "Power Hold Enabled" 0 "Power Hold Disabled" ;
VAL_ 2557738750 EnableCmd 3 "Don't Care/Take no action" 2 "Accessory Motor On Reverse Direction" 1 "Accessory Motor On Normal/Default Direction" 0 "Accessory Motor Off" ;
VAL_ 2624716542 CommandedTransmitPGNReqSt 3 "Not Available" 2 "SAE Reserved" 1 "PG shall be enabled for transmit" 0 "PG shall be disabled for transmit" ;
VAL_ 2624716542 TransactionMode 15 "SAE Reserved" 14 "SAE Reserved" 13 "SAE Reserved" 12 "SAE Reserved" 10 "SAE Reserved" 9 "SAE Reserved" 8 "SAE Reserved" 7 "SAE Reserved" 6 "SAE Reserved" 5 "SAE Reserved" 11 "SAE Reserved" 4 "Partial Revert to Default" 3 "Global Revert to Default" 2 "Cancel Pending Changes" 1 "Configure Port Transmit State" 0 "Request Port Transmit Status" ;
VAL_ 2624716542 CommandedPort 15 "SAE Reserved" 14 "SAE Reserved" 13 "SAE Reserved" 12 "SAE Reserved" 11 "SAE Reserved" 10 "Port 10" 9 "Port 9" 8 "Port 8" 7 "Port 7" 6 "Port 6" 5 "Port 5" 4 "Port 4" 3 "Port 3" 2 "Port 2" 1 "Port 1" 0 "Current port" ;
VAL_ 2350644990 ThermalMnmgtMaintenanceReq 3 "Don't care/take no action" 2 "Reserved" 1 "HVESS Thermal Management Maintenance Mode is requested" 0 "HVESS Thermal Management Maintenance Mode is not requested" ;
VAL_ 2350644990 HVBusLowSideResistorConnectReq 3 "Don't care/take no action" 2 "Reserved" 1 "Connection Requested" 0 "Connection not Requested" ;
VAL_ 2350644990 HVBusHiSideResistorConnectReq 3 "Don't care/take no action" 2 "Reserved" 1 "Connection Requested" 0 "Connection not Requested" ;
VAL_ 2350644990 OpConsent 3 "Don't care/Take no action" 2 "Error" 1 "Consent given" 0 "Consent revoked" ;
VAL_ 2350644990 EnableInternalChargerCmd 3 "Don't care/Take no action" 2 "Reserved" 1 "Enable charging" 0 "Disable charging" ;
VAL_ 2350644990 CellBalancingCmd 3 "Don't care/Take no action" 2 "Reserved" 1 "Cell Balancing requested" 0 "Cell Balancing not requested" ;
VAL_ 2350644990 HVBusPassiveIsolTestCmd 3 "Don't care/Take no action" 2 "Inhibit Passive Isolation Test" 1 "Passive Isolation Test request" 0 "Passive Isolation Test not requested" ;
VAL_ 2350644990 HVBusActiveIsolTestCmd 3 "Don't care/Take no action" 2 "Inhibit Active Isolation Test" 1 "Active Isolation Test request" 0 "Active Isolation Test not requested" ;
VAL_ 2350644990 PwrDownCmd 3 "Don't care/Take no action" 2 "Execute emergency power-down" 1 "Execute normal power-down" 0 "Power-down not requested" ;
VAL_ 2350644990 HVBusConnectCmd 3 "Don't care/Take no action" 2 "Emergency contactor closure request" 1 "Close Contactor" 0 "Open Contactor" ;
VAL_ 2499548158 RightRearCabDoorLatchPos 7 "Not Available" 6 "Error" 5 "Reserved" 4 "Reserved" 3 "Reserved" 2 "Door Latch Ajar" 1 "Door Latch Fully Closed/Latched" 0 "Door Latch Open" ;
VAL_ 2499548158 LeftRearCabDoorLatchPos 7 "Not Available" 6 "Error" 5 "Reserved" 4 "Reserved" 3 "Reserved" 2 "Door Latch Ajar" 1 "Door Latch Fully Closed/Latched" 0 "Door Latch Open" ;
VAL_ 2499548158 RightFrontCabDoorLatchPos 7 "Not Available" 6 "Error" 5 "Reserved" 4 "Reserved" 3 "Reserved" 2 "Door Latch Ajar" 1 "Door Latch Fully Closed/Latched" 0 "Door Latch Open" ;
VAL_ 2499548158 LeftFrontCabDoorLatchPos 7 "Not Available" 6 "Error" 5 "Reserved" 4 "Reserved" 3 "Reserved" 2 "Door Latch Ajar" 1 "Door Latch Fully Closed/Latched" 0 "Door Latch Open" ;
VAL_ 2499547902 MirrorAutoPanningEnable 3 "Not available/Take no action" 2 "Reserved" 1 "Enable panning" 0 "Disable panning" ;
VAL_ 2499547902 MirrorFoldingSw 3 "Take no action" 2 "Reserved" 1 "Request to toggle mirror position" 0 "No Request" ;
VAL_ 2499547902 MirrorRight2HeatCmd 3 "Take no action" 2 "Reserved" 1 "Mirror heat on" 0 "Mirror heat off" ;
VAL_ 2499547902 MirrorLeft2HeatCmd 3 "Take no action" 2 "Reserved" 1 "Mirror heat on" 0 "Mirror heat off" ;
VAL_ 2499547902 MirrorRight1HeatCmd 3 "Take no action" 2 "Reserved" 1 "Mirror heat on" 0 "Mirror heat off" ;
VAL_ 2499547902 MirrorLeft1HeatCmd 3 "Take no action" 2 "Reserved" 1 "Mirror heat on" 0 "Mirror heat off" ;
VAL_ 2499547902 MirrorRight2VerticalCmd 3 "Take no action" 2 "Reset" 1 "Move down" 0 "Move up" ;
VAL_ 2499547902 MirrorRight2HorizontalCmd 3 "Take no action" 2 "Reset" 1 "Move right" 0 "Move left" ;
VAL_ 2499547902 MirrorLeft2VerticalCmd 3 "Take no action" 2 "Reset" 1 "Move down" 0 "Move up" ;
VAL_ 2499547902 MirrorLeft2HorizontalCmd 3 "Take no action" 2 "Reset" 1 "Move right" 0 "Move left" ;
VAL_ 2499547902 MirrorRight1VerticalCmd 3 "Take no action" 2 "Reset" 1 "Move down" 0 "Move up" ;
VAL_ 2499547902 MirrorRight1HorizontalCmd 3 "Take no action" 2 "Reset" 1 "Move right" 0 "Move left" ;
VAL_ 2499547902 MirrorLeft1VerticalCmd 3 "Take no action" 2 "Reset" 1 "Move down" 0 "Move up" ;
VAL_ 2499547902 MirrorLeft1HorizontalCmd 3 "Take no action" 2 "Reset" 1 "Move right" 0 "Move left" ;
VAL_ 2499547902 RightRearWindowPosCmd 7 "Take no action" 6 "Reserved" 5 "Reserved" 4 "Reserved" 3 "Window auto down" 2 "Window auto up" 1 "Window move down" 0 "Window move up" ;
VAL_ 2499547902 LeftRearWindowPosCmd 7 "Take no action" 6 "Reserved" 5 "Reserved" 4 "Reserved" 3 "Window auto down" 2 "Window auto up" 1 "Window move down" 0 "Window move up" ;
VAL_ 2499547902 RightFrontWindowPosCmd 7 "Take no action" 6 "Reserved" 5 "Reserved" 4 "Reserved" 3 "Window auto down" 2 "Window auto up" 1 "Window move down" 0 "Window move up" ;
VAL_ 2499547902 LeftFrontWindowPosCmd 7 "Take no action" 6 "Reserved" 5 "Reserved" 4 "Reserved" 3 "Window auto down" 2 "Window auto up" 1 "Window move down" 0 "Window move up" ;
VAL_ 2499547902 RemoteCabDoorLockReq 7 "Take no action" 6 "Reserved" 5 "Request lock all cab door latches" 4 "Request unlock all cab door latches" 3 "Request unlock right rear cab door latch" 2 "Request unlock left rear cab door latch" 1 "Request unlock right front cab door latch" 0 "Request unlock left front cab door latch" ;
VAL_ 2499547902 DoorsLockActCmd 7 "Take no action" 6 "Reserved" 5 "Lock all cab door latches" 4 "Unlock all cab door latches" 3 "Unlock right rear cab door latch" 2 "Unlock left rear cab door latch" 1 "Unlock right front cab door latch" 0 "Unlock left front cab door latch" ;
VAL_ 2431710718 AutomaticEngStartConsentSummary 3 "Not available" 2 "Error" 1 "Consent" 0 "No consent" ;
VAL_ 2431710718 OpEngStartConsentSummary 3 "Not available" 2 "Error" 1 "Consent" 0 "No consent" ;
VAL_ 2431710718 ReqLatchStatus 15 "Not available" 6 "Start request unlatched, start could not be completed because the starter command was not successful" 5 "Start request unlatched, start aborted due to abort request" 4 "Start request unlatched, consent not established within allowed time" 3 "Start request unlatched, start completed" 2 "Start request latched, consent confirmed" 1 "Start request latched, waiting for consent" 0 "Start request not received" ;
VAL_ 2431710718 StarterCmd 7 "Don't care / Take no action" 3 "Command withdrawn" 2 "Command active for starter 2" 1 "Command active for starter 1" 0 "Command not active" ;
VAL_ 2431710718 CtrlMessageRate 3 "Not available" 2 "Reserved" 1 "Once every 250 ms or on change but no faster than 20 ms" 0 "Once every 20 ms" ;
VAL_ 2431708670 TransShiftSelectorReqVehDir 7 "Not supported" 6 "Error" 5 "SAE Reserved" 4 "SAE Reserved" 3 "Reverse direction selected" 2 "Forward direction selected" 1 "No direction selected, Neutral" 0 "No direction selected, Park" ;
VAL_ 2431708670 Starter2Feedback 7 "Not available" 4 "Starter command unlatched,  start aborted by starter controller" 3 "Starter command unlatched,  start abort command received from arbitrator" 2 "Starter command unlatched,  start completed" 1 "Starter command latched" 0 "Starter not commanded" ;
VAL_ 2431708670 Starter1Feedback 7 "Not available" 4 "Starter command unlatched,  start aborted by starter controller" 3 "Starter command unlatched,  start abort command received from arbitrator" 2 "Starter command unlatched,  start completed" 1 "Starter command latched" 0 "Starter not commanded" ;
VAL_ 2431708670 AbortReq 3 "Don't care / Take no action" 2 "Reserved" 1 "Abort requested" 0 "Abort not requested" ;
VAL_ 2431708670 Consent 7 "Not available" 3 "Consent to both" 2 "Consent to automatic start only" 1 "Consent to operator-requested start only" 0 "No consent" ;
VAL_ 2431708670 Req 3 "Not available" 2 "Start requested,  automatic type" 1 "Start requested,  operator type" 0 "Start not requested" ;
VAL_ 2565926142 NOxSnsr2SelfDiagSt 7 "Not Supported" 4 "NOx Sensor ATO2 Self-diagnosis not possible" 3 "NOx Sensor ATO2 Self-diagnosis aborted" 2 "NOx Sensor ATO2 Self-diagnosis Result Complete" 1 "NOx Sensor ATO2 Self-diagnosis active flag" 0 "Diagnosis not active" ;
VAL_ 2565926142 Snsr2HtrCtrl 3 "Heater off" 2 "Preheat 1" 1 "Preheat 2" 0 "Automatic" ;
VAL_ 2565926142 WRPercentO22ReadingStable 3 "Not available" 2 "Error" 1 "Stable" 0 "Not stable" ;
VAL_ 2565926142 NOx2ReadingStable 3 "Not available" 2 "Error" 1 "Stable" 0 "Not stable" ;
VAL_ 2565926142 Snsr2AtTemp 3 "Not available" 2 "Error" 1 "In range" 0 "Not in range" ;
VAL_ 2565926142 Snsr2PwrInRange 3 "Not available" 2 "Error" 1 "In range" 0 "Not in range" ;
VAL_ 2565925886 NOxSnsr2SelfDiagStatus 7 "Not Supported" 6 "Reserved" 5 "Reserved" 4 "NOx Sensor EEB2 Self-diagnosis not possible" 3 "NOx Sensor EEB2 Self-diagnosis aborted" 2 "NOx Sensor EEB2 Self-diagnosis Result Complete" 1 "NOx Sensor EEB2 Self-diagnosis active flag" 0 "Diagnosis not active" ;
VAL_ 2565925886 HtrCtrl 3 "Heater off" 2 "Preheat 1" 1 "Preheat 2" 0 "Automatic" ;
VAL_ 2565925886 WRPercentO22ReadingStable 3 "Not available" 2 "Error" 1 "Stable" 0 "Not stable" ;
VAL_ 2565925886 SCRInNOx2ReadingStable 3 "Not available" 2 "Error" 1 "Stable" 0 "Not stable" ;
VAL_ 2565925886 AtTemp 3 "Not available" 2 "Error" 1 "In range" 0 "Not in range" ;
VAL_ 2565925886 PwrInRange 3 "Not available" 2 "Error" 1 "In range" 0 "Not in range" ;
VAL_ 2565925630 NOxSnsr2SelfDiagSt 7 "Not Supported" 4 "NOx Sensor ATO1 Self-diagnosis not possible" 3 "NOx Sensor ATO1 Self-diagnosis aborted" 2 "NOx Sensor ATO1 Self-diagnosis Result Complete" 1 "NOx Sensor ATO1 Self-diagnosis active flag" 0 "Diagnosis not active" ;
VAL_ 2565925630 Snsr2HtrCtrl 3 "Heater off" 2 "Preheat 1" 1 "Preheat 2" 0 "Automatic" ;
VAL_ 2565925630 WRPercentO22ReadingStable 3 "Not available" 2 "Error" 1 "Stable" 0 "Not stable" ;
VAL_ 2565925630 NOx2ReadingStable 3 "Not available" 2 "Error" 1 "Stable" 0 "Not stable" ;
VAL_ 2565925630 Snsr2AtTemp 3 "Not available" 2 "Error" 1 "In range" 0 "Not in range" ;
VAL_ 2565925630 Snsr2PwrInRange 3 "Not available" 2 "Error" 1 "In range" 0 "Not in range" ;
VAL_ 2565925374 NOxSnsr2SelfDiagStatus 7 "Not Supported" 6 "Reserved" 5 "Reserved" 4 "NOx Sensor EEB1 Self-diagnosis not possible" 3 "NOx Sensor EEB1 Self-diagnosis aborted" 2 "NOx Sensor EEB1 Self-diagnosis Result Complete" 1 "NOx Sensor EEB1 Self-diagnosis active flag" 0 "Diagnosis not active" ;
VAL_ 2565925374 Snsr2HtrCtrl 3 "Heater off" 2 "Preheat 1" 1 "Preheat 2" 0 "Automatic" ;
VAL_ 2565925374 WRPercentO22ReadingStable 3 "Not available" 2 "Error" 1 "Stable" 0 "Not stable" ;
VAL_ 2565925374 SCRInNOx2ReadingStable 3 "Not available" 2 "Error" 1 "Stable" 0 "Not stable" ;
VAL_ 2565925374 Snsr2AtTemp 3 "Not available" 2 "Error" 1 "In range" 0 "Not in range" ;
VAL_ 2565925374 Snsr2PwrInRange 3 "Not available" 2 "Error" 1 "In range" 0 "Not in range" ;
VAL_ 2364598526 FuelAct2MotorCurDis 3 "Don't Care/Take No Action" 2 "Reserved" 1 "Disable" 0 "Do Not Disable" ;
VAL_ 2364598526 FuelAct1MotorCurDis 3 "Don't Care/Take No Action" 2 "Reserved" 1 "Disable" 0 "Do Not Disable" ;
VAL_ 2565900286 DeratingReason 255 "Not Available" 254 "Error" 253 "Other" 6 "Smart Charging" 5 "GA, Ground Assembly) Internal" 4 "GA, Ground Assembly) Temperature" 3 "Vehicle Internal" 2 "VA, Vehicle Assembly) Alignment" 1 "VA, Vehicle Assembly) Temperature" 0 "Not Derating" ;
VAL_ 2565900286 St 255 "Not Available" 254 "Error" 9 "GA" 8 "FOD" 7 "VA" 6 "Shutdown" 5 "Power Transfer" 4 "Idle" 3 "Awaiting Alignment" 2 "Session Initiated" 1 "Standby" 0 "Off" ;
VAL_ 2566838014 HSI1EmbeddedIntegritySupport 3 "HSI1 CRC and Counter are not supported by the sender" 2 "Reserved" 1 "HSI1 protection is supported using J1939-76 SHM" 0 "HSI1 embedded CRC and Counter are supported by the sender" ;
VAL_ 2566838014 HVESSThermalMnmgtMaintenanceSw 3 "Not available" 2 "Error" 1 "On" 0 "Off" ;
VAL_ 2566838014 PropulsionMotorCoolantFillSw 3 "Not available" 2 "Error" 1 "On" 0 "Off" ;
VAL_ 2566838014 PwrECoolantFillSw 3 "Not available" 2 "Error" 1 "On" 0 "Off" ;
VAL_ 2566838014 ShutdownSw 3 "Not Available" 2 "Error" 1 "On" 0 "Off" ;
VAL_ 2566838014 PropulsionDisableSw 3 "Not Available" 2 "Error" 1 "On" 0 "Off" ;
VAL_ 2566838014 HybrdSystmBrkPdlRgnrtvBrkngDsblS 3 "Not Available" 2 "Error" 1 "Brake pedal regenerative braking disable switch is on" 0 "Brake pedal regenerative braking disable switch is off" ;
VAL_ 2566838014 HybrdSystmRgnrtvBrkngDsbleSwitch 3 "Not Available" 2 "Error" 1 "Regenerative Braking  Disable Switch is on" 0 "Regenerative Braking Disable Switch is off" ;
VAL_ 2566838014 HybrdSystmOffBrdChrgrCnnctnSttus 3 "Not available" 2 "Error" 1 "Off-board charger is connected" 0 "Off-board charger is not connected" ;
VAL_ 2566838014 HybrdSystmPwrElctrncsClntLvlSwtc 3 "Not Available" 2 "Error" 1 "Coolant Level is sufficient" 0 "Coolant Level is not sufficient" ;
VAL_ 2566838014 HybrdSystmPrplsnClantLevelSwitch 3 "Not Available" 2 "Error" 1 "Coolant Level is sufficient" 0 "Coolant Level is not sufficient" ;
VAL_ 2566838014 HybrdSystmPrtctionOverrideSwitch 3 "Not Available" 2 "Error" 1 "Active" 0 "Not Active" ;
VAL_ 2566687998 RegenSt6774 15 "Not Available" 3 "Regeneration is active and has been initiated due to time based conditions" 2 "Regeneration is active and has been initiated because of sensor conditions" 1 "Regneration is active and has been initiated by request via SPN 6783" 0 "Regeneration is not active" ;
VAL_ 2566687998 RegenSt 3 "Not available" 2 "Regeneration failed" 1 "Regeneration was successful" 0 "Regeneration has not completed during this power cycle" ;
VAL_ 2566687998 HtrSt 3 "Heater is off" 2 "Heater is in ramp up mode" 1 "Heater is being held at a specified level" 0 "Heater is in closed loop control" ;
VAL_ 2566687742 PwrSupply 3 "Unavailable" 2 "Error" 1 "On" 0 "Off" ;
VAL_ 2566687742 DetectionSt 15 "Not supported" 8 "Halt particulate matter detection" 7 "Sensor regeneration did not complete due to system parameters out of range" 6 "Relearning particulate sensor resistance after particulate sensor regeneration" 5 "Heater diagnostics test" 4 "Cooling after particulate sensor regeneration" 3 "Heater is active for particulate sensor regeneration" 2 "Particulate matter detection" 1 "Waiting for dew point" 0 "Initialization for particulate matter detection" ;
VAL_ 2365348350 ShareActiveCirc 3 "Not available" 2 "Error" 1 "On" 0 "Off" ;
VAL_ 2365348350 EngLoadShareStatus 15 "Unavailable" 14 "Error" 4 "Unloading" 3 "Loading" 2 "Slave" 1 "Master" 0 "Offline" ;
VAL_ 2365348350 EngUnloadStatus 3 "Not Available" 2 "Error" 1 "Requested" 0 "Not Requested" ;
VAL_ 2633782014 BinWeighingErrorStatus 15 "Not available / not applicable" 3 "Weighing error: empty bin lifted" 2 "Weighing error: bin lifted" 1 "Bad lift cycle" 0 "No error" ;
VAL_ 2365346302 LiftAxle4Status 7 "Not available" 6 "Error" 5 "Loading" 4 "Lowering" 3 "Up" 2 "Lifting" 1 "Unloading" 0 "Down" ;
VAL_ 2365346302 LiftAxle3Status 7 "Not available" 6 "Error" 5 "Loading" 4 "Lowering" 3 "Up" 2 "Lifting" 1 "Unloading" 0 "Down" ;
VAL_ 2365346302 LiftAxle2Status 7 "Not available" 6 "Error" 5 "Loading" 4 "Lowering" 3 "Up" 2 "Lifting" 1 "Unloading" 0 "Down" ;
VAL_ 2365346302 LiftAxle1Status 7 "Not available" 6 "Error" 5 "Loading" 4 "Lowering" 3 "Up" 2 "Lifting" 1 "Unloading" 0 "Down" ;
VAL_ 2566672638 DeliveryTransactionStatus 15 "Not Available" 14 "Error" 2 "Transaction Complete" 1 "Transaction In Progress" 0 "Transaction Not In Progress" ;
VAL_ 2566672638 HaulModeStatus 15 "Not Available" 14 "Error" 5 "Unloaded" 4 "Unloading" 3 "Loaded" 2 "Approaching Loaded" 1 "Loading" 0 "Not in Haul Mode" ;
VAL_ 2566672382 PayloadWeightSensor8Status 3 "Not available" 2 "Error" 1 "Sensor degraded" 0 "Sensor fully functional" ;
VAL_ 2566672382 PayloadWeightSensor7Status 3 "Not available" 2 "Error" 1 "Sensor degraded" 0 "Sensor fully functional" ;
VAL_ 2566672382 PayloadWeightSensor6Status 3 "Not available" 2 "Error" 1 "Sensor degraded" 0 "Sensor fully functional" ;
VAL_ 2566672382 PayloadWeightSensor5Status 3 "Not available" 2 "Error" 1 "Sensor degraded" 0 "Sensor fully functional" ;
VAL_ 2566672382 PayloadWeightSensor4Status 3 "Not available" 2 "Error" 1 "Sensor degraded" 0 "Sensor fully functional" ;
VAL_ 2566672382 PayloadWeightSensor3Status 3 "Not available" 2 "Error" 1 "Sensor degraded" 0 "Sensor fully functional" ;
VAL_ 2566672382 PayloadWeightSensor2Status 3 "Not available" 2 "Error" 1 "Sensor degraded" 0 "Sensor fully functional" ;
VAL_ 2566672382 PayloadWeightSensor1Status 2 "Error" 1 "Sensor degraded" 0 "Sensor fully functional" 3 "Not available" ;
VAL_ 2566671614 SCROprtrInducementOverrideEnable 3 "Not available" 2 "SAE Reserved" 1 "Override allowed" 0 "Override not allowed" ;
VAL_ 2566671102 AFT1CondNotMetForActiveClean 3 "Not available" 2 "Reserved for SAE Assignment" 1 "SCR System Cleaning Inhibited" 0 "SCR System Cleaning not Inhibited" ;
VAL_ 2566671102 SCRSystemCleaningForcedStatus 7 "not available" 6 "Reserved for SAE Assignment" 5 "Reserved for SAE Assignment" 4 "Reserved for SAE Assignment" 3 "Reserved for SAE Assignment" 2 "Active, Forced by Service Tool" 1 "Active, Forced by Switch" 0 "Not Active" ;
VAL_ 2566671102 SCRSystmClnngAtmtcIntationConfig 3 "not available" 2 "reserved for SAE assignment" 1 "enabled" 0 "not enabled" ;
VAL_ 2566671102 SCRSystmClnngInhbtdDTVhclSpdBlwA 3 "not available" 2 "reserved for SAE assignment" 1 "inhibited" 0 "not inhibited" ;
VAL_ 2566671102 SCRSystmClnngInhbtdDTEngNtWrmdUp 3 "not available" 2 "reserved for SAE assignment" 1 "inhibited" 0 "not inhibited" ;
VAL_ 2566671102 SCRSystmClnngInhbtdDTPrmnntSystm 3 "not available" 2 "reserved for SAE assignment" 1 "inhibited" 0 "not inhibited" ;
VAL_ 2566671102 SCRSystmClnngInhbtdDTTmprrySystm 3 "not available" 2 "reserved for SAE assignment" 1 "inhibited" 0 "not inhibited" ;
VAL_ 2566671102 SCRSystmClnngInhbtdDTSystmTmeout 3 "not available" 2 "reserved for SAE assignment" 1 "inhibited" 0 "not inhibited" ;
VAL_ 2566671102 SCRSystmClnngInhbtdDTSystmFltAct 3 "not available" 2 "reserved for SAE assignment" 1 "inhibited" 0 "not inhibited" ;
VAL_ 2566671102 SCRSystmClnngInhbtdDTLwExhstTemp 3 "not available" 2 "reserved for SAE assignment" 1 "inhibited" 0 "not inhibited" ;
VAL_ 2566671102 SCRSystmClnngInhbtdDTPrkngBrkNtS 3 "not available" 2 "reserved for SAE assignment" 1 "inhibited" 0 "not inhibited" ;
VAL_ 2566671102 SCRSystmClnngInhbtdDTVhclSpdAbvA 3 "not available" 2 "reserved for SAE assignment" 1 "inhibited" 0 "not inhibited" ;
VAL_ 2566671102 SCRSystmClnngInhbtdDTOtOfNeutral 3 "not available" 2 "reserved for SAE assignment" 1 "inhibited" 0 "not inhibited" ;
VAL_ 2566671102 SCRSystmClnngInhbtdDTAcclPdlOffI 3 "not available" 2 "reserved for SAE assignment" 1 "inhibited" 0 "not inhibited" ;
VAL_ 2566671102 SCRSystmClnngInhbtdDeToPTOActive 3 "not available" 2 "reserved for SAE assignment" 1 "inhibited" 0 "not inhibited" ;
VAL_ 2566671102 SCRSystmClnngInhbtdDTSrvcBrkActv 3 "not available" 2 "reserved for SAE assignment" 1 "inhibited" 0 "not inhibited" ;
VAL_ 2566671102 SCRSystmClnngInhbtdDTCltchDsnggd 3 "not available" 2 "reserved for SAE assignment" 1 "inhibited" 0 "not inhibited" ;
VAL_ 2566671102 SCRSystmClnngInhbtdDTInhbtSwitch 3 "not available" 2 "reserved for SAE assignment" 1 "inhibited" 0 "not inhibited" ;
VAL_ 2566671102 SCRSystemCleaningInhibitedStatus 3 "not available" 2 "reserved for SAE assignment" 1 "inhibited" 0 "not inhibited" ;
VAL_ 2566671102 SCRSystemCleaningStatus 3 "not available" 2 "SCR system cleaning is needed" 1 "active" 0 "not active" ;
VAL_ 2566671102 SCRSystemCleaningLampCmd 7 "not available" 6 "reserved for SAE assignment" 5 "reserved for SAE assignment" 4 "On, fast blink" 3 "reserved for SAE assignment" 2 "reserved for SAE assignment" 1 "On, solid" 0 "Off" ;
